VERSION ""

NS_ :

BS_:
BU_: IAP ODS _4WD BCM HUD DATC MDPS AAF_Tester AEMC SMK _4WD EPB CUBIS MTS TMU EVP CGW TPMS LPI DI_BOX SPAS EMS LCA TCU IBOX FATC AFLS FPCM SCC AHLS AVM ABS SNV OPI PGS SAS AAF Dummy LDWS_LKAS LVR ESC PSB CLU ECS ACU REA
BO_ 339 TCS11: 8 ESC
	SG_ TCS_REQ : 0|1@1+ (1.0,0.0) [0.0|1.0] ""  _4WD,EMS,EPB,TCU
	SG_ MSR_C_REQ : 1|1@1+ (1.0,0.0) [0.0|1.0] ""  EMS,EPB,SCC,TCU
	SG_ TCS_PAS : 2|1@1+ (1.0,0.0) [0.0|1.0] ""  _4WD,CLU,EMS,SCC,SPAS,TCU
	SG_ TCS_GSC : 3|1@1+ (1.0,0.0) [0.0|1.0] ""  _4WD,EMS,TCU
	SG_ CF_Esc_LimoInfo : 4|2@1+ (1.0,0.0) [0.0|3.0] ""  _4WD,SCC
	SG_ ABS_DIAG : 6|1@1+ (1.0,0.0) [0.0|1.0] ""  _4WD,CLU,EMS,EPB
	SG_ ABS_DEF : 7|1@1+ (1.0,0.0) [0.0|1.0] ""  _4WD,ACU,ECS,EMS,EPB,SCC,SPAS,TCU
	SG_ TCS_DEF : 8|1@1+ (1.0,0.0) [0.0|1.0] ""  _4WD,EMS,EPB,SCC,SPAS,TCU
	SG_ TCS_CTL : 9|1@1+ (1.0,0.0) [0.0|1.0] ""  _4WD,EMS,EPB,SCC,SPAS,TCU
	SG_ ABS_ACT : 10|1@1+ (1.0,0.0) [0.0|1.0] ""  _4WD,ACU,ECS,EMS,EPB,LDWS_LKAS,SCC,SPAS,TCU
	SG_ EBD_DEF : 11|1@1+ (1.0,0.0) [0.0|1.0] ""  _4WD,EMS,EPB,SPAS,TCU
	SG_ ESP_PAS : 12|1@1+ (1.0,0.0) [0.0|1.0] ""  _4WD,ACU,CLU,EMS,EPB,LDWS_LKAS,SCC,TCU
	SG_ ESP_DEF : 13|1@1+ (1.0,0.0) [0.0|1.0] ""  _4WD,ACU,ECS,EMS,EPB,LDWS_LKAS,SCC,TCU
	SG_ ESP_CTL : 14|1@1+ (1.0,0.0) [0.0|1.0] ""  _4WD,ACU,ECS,EMS,EPB,LDWS_LKAS,SCC,SPAS,TCU
	SG_ TCS_MFRN : 15|1@1+ (1.0,0.0) [0.0|1.0] ""  EMS,EPB,TCU
	SG_ DBC_CTL : 16|1@1+ (1.0,0.0) [0.0|1.0] ""  _4WD,EMS,EPB
	SG_ DBC_PAS : 17|1@1+ (1.0,0.0) [0.0|1.0] ""  _4WD,EMS,EPB
	SG_ DBC_DEF : 18|1@1+ (1.0,0.0) [0.0|1.0] ""  _4WD,EMS,EPB
	SG_ HAC_CTL : 19|1@1+ (1.0,0.0) [0.0|1.0] ""  _4WD,CLU,EMS,EPB,TCU
	SG_ HAC_PAS : 20|1@1+ (1.0,0.0) [0.0|1.0] ""  _4WD,CLU,EMS,EPB,TCU
	SG_ HAC_DEF : 21|1@1+ (1.0,0.0) [0.0|1.0] ""  _4WD,CLU,EMS,EPB,TCU
	SG_ ESS_STAT : 22|2@1+ (1.0,0.0) [0.0|3.0] ""  _4WD,BCM,CLU,EMS,EPB
	SG_ TQI_TCS : 24|8@1+ (0.390625,0.0) [0.0|99.609375] "%"  EMS,EPB,TCU
	SG_ TQI_MSR : 32|8@1+ (0.390625,0.0) [0.0|99.609375] "%"  EMS,EPB,TCU
	SG_ TQI_SLW_TCS : 40|8@1+ (0.390625,0.0) [0.0|99.609375] "%"  EMS,EPB,TCU
	SG_ CF_Esc_BrkCtl : 48|1@1+ (1.0,0.0) [0.0|1.0] ""  EMS
	SG_ BLA_CTL : 49|2@1+ (1.0,0.0) [0.0|3.0] ""  BCM,CGW,CLU
	SG_ AliveCounter_TCS1 : 52|4@1+ (1.0,0.0) [0.0|14.0] ""  EMS,EPB,LDWS_LKAS
	SG_ CheckSum_TCS1 : 56|8@1+ (1.0,0.0) [0.0|255.0] ""  EMS,EPB,LDWS_LKAS

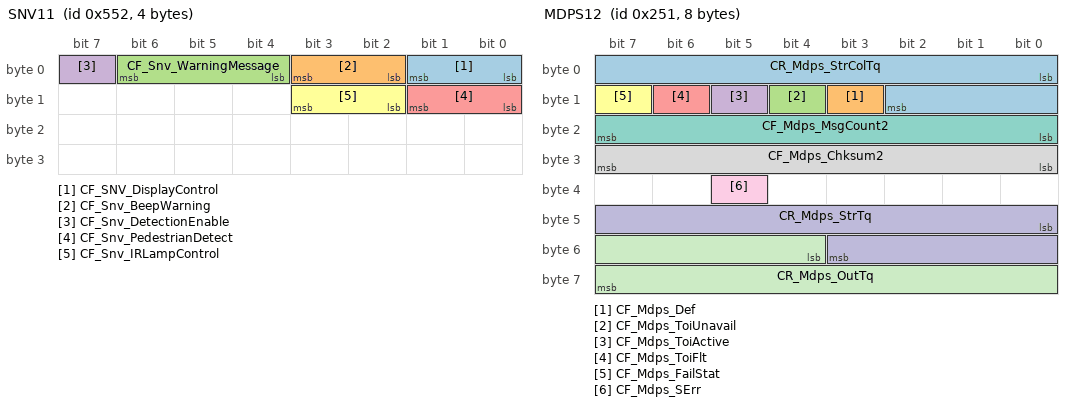
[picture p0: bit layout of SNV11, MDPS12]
BO_ 1362 SNV11: 4 SNV
	SG_ CF_SNV_DisplayControl : 0|2@1+ (1.0,0.0) [0.0|3.0] ""  CLU,HUD
	SG_ CF_Snv_BeepWarning : 2|2@1+ (1.0,0.0) [0.0|3.0] ""  CLU,HUD
	SG_ CF_Snv_WarningMessage : 4|3@1+ (1.0,0.0) [0.0|7.0] ""  CLU,HUD
	SG_ CF_Snv_DetectionEnable : 7|1@1+ (1.0,0.0) [0.0|1.0] ""  BCM,CLU,HUD
	SG_ CF_Snv_PedestrianDetect : 8|2@1+ (1.0,0.0) [0.0|3.0] ""  BCM,CLU,HUD
	SG_ CF_Snv_IRLampControl : 10|2@1+ (1.0,0.0) [0.0|3.0] ""  BCM,CLU,HUD

BO_ 593 MDPS12: 8 MDPS
	SG_ CR_Mdps_StrColTq : 0|11@1+ (0.0078125,-8.0) [-8.0|7.9921875] "Nm"  LDWS_LKAS
	SG_ CF_Mdps_Def : 11|1@1+ (1.0,0.0) [0.0|1.0] ""  ESC
	SG_ CF_Mdps_ToiUnavail : 12|1@1+ (1.0,0.0) [0.0|1.0] ""  LDWS_LKAS
	SG_ CF_Mdps_ToiActive : 13|1@1+ (1.0,0.0) [0.0|1.0] ""  LDWS_LKAS
	SG_ CF_Mdps_ToiFlt : 14|1@1+ (1.0,0.0) [0.0|1.0] ""  LDWS_LKAS
	SG_ CF_Mdps_FailStat : 15|1@1+ (1.0,0.0) [0.0|1.0] ""  LDWS_LKAS
	SG_ CF_Mdps_MsgCount2 : 16|8@1+ (1.0,0.0) [0.0|255.0] ""  ESC,LDWS_LKAS
	SG_ CF_Mdps_Chksum2 : 24|8@1+ (1.0,0.0) [0.0|255.0] ""  ESC,LDWS_LKAS
	SG_ CF_Mdps_SErr : 37|1@1+ (1.0,0.0) [0.0|1.0] ""  ESC
	SG_ CR_Mdps_StrTq : 40|12@1+ (0.01,-20.48) [-20.48|20.47] "Nm"  ESC
	SG_ CR_Mdps_OutTq : 52|12@1+ (0.1,-204.8) [-204.8|204.7] ""  ESC,LDWS_LKAS

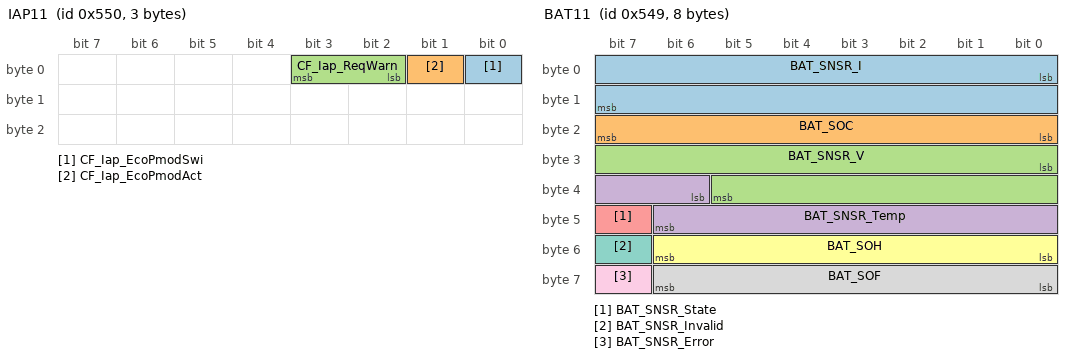
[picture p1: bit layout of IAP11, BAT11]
BO_ 1360 IAP11: 3 IAP
	SG_ CF_Iap_EcoPmodSwi : 0|1@1+ (1.0,0.0) [0.0|1.0] ""  CLU
	SG_ CF_Iap_EcoPmodAct : 1|1@1+ (1.0,0.0) [0.0|1.0] ""  CLU
	SG_ CF_Iap_ReqWarn : 2|2@1+ (1.0,0.0) [0.0|3.0] ""  CLU

BO_ 1356 TCU_DCT14: 8 TCU
	SG_ Vehicle_Stop_Time : 0|5@1+ (1.0,0.0) [0.0|0.0] ""  CLU
	SG_ HILL_HOLD_WARNING : 5|1@1+ (1.0,0.0) [0.0|0.0] ""  CLU

BO_ 1353 BAT11: 8 EMS
	SG_ BAT_SNSR_I : 0|16@1+ (0.01,-327.0) [-327.0|328.0] "A"  CGW,CUBIS,IBOX,TMU
	SG_ BAT_SOC : 16|8@1+ (1.0,0.0) [0.0|100.0] "%"  CGW,CUBIS,IBOX,TMU
	SG_ BAT_SNSR_V : 24|14@1+ (0.0010,6.0) [6.0|18.0] "V"  CGW,CUBIS,IBOX,TMU
	SG_ BAT_SNSR_Temp : 38|9@1- (0.5,-40.0) [-40.0|125.0] "¡É"  CGW,CUBIS,IBOX,TMU
	SG_ BAT_SNSR_State : 47|1@1+ (1.0,0.0) [0.0|1.0] ""  CGW,CUBIS,IBOX,TMU
	SG_ BAT_SOH : 48|7@1+ (1.0,0.0) [0.0|100.0] "%"  CGW,CUBIS,IBOX,TMU
	SG_ BAT_SNSR_Invalid : 55|1@1+ (1.0,0.0) [0.0|1.0] ""  CGW,CUBIS,IBOX,TMU
	SG_ BAT_SOF : 56|7@1+ (0.1,0.0) [0.0|12.0] "V"  CGW,CUBIS,IBOX,TMU
	SG_ BAT_SNSR_Error : 63|1@1+ (1.0,0.0) [0.0|1.0] ""  CGW,CUBIS,IBOX,TMU

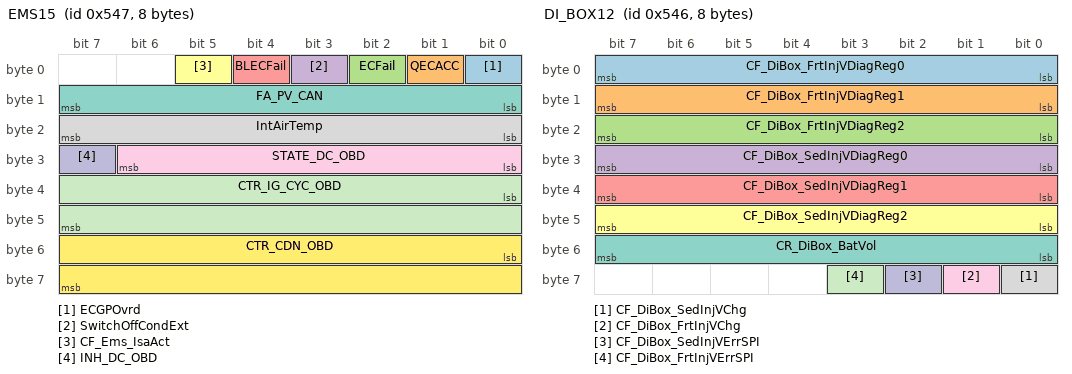
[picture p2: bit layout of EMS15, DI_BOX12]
BO_ 1351 EMS15: 8 EMS
	SG_ ECGPOvrd : 0|1@1+ (1.0,0.0) [0.0|1.0] ""  ESC,IBOX,SCC
	SG_ QECACC : 1|1@1+ (1.0,0.0) [0.0|1.0] ""  ESC,IBOX
	SG_ ECFail : 2|1@1+ (1.0,0.0) [0.0|1.0] ""  ESC,IBOX
	SG_ SwitchOffCondExt : 3|1@1+ (1.0,0.0) [0.0|1.0] ""  ESC,IBOX
	SG_ BLECFail : 4|1@1+ (1.0,0.0) [0.0|1.0] ""  ESC,IBOX
	SG_ CF_Ems_IsaAct : 5|1@1+ (1.0,0.0) [0.0|1.0] ""  CLU
	SG_ FA_PV_CAN : 8|8@1+ (0.3906,0.0) [0.0|99.2] "%"  IBOX,LDWS_LKAS,TCU
	SG_ IntAirTemp : 16|8@1+ (0.75,-48.0) [-48.0|143.25] "¡É"  _4WD,ECS,EPB,IBOX,TCU
	SG_ STATE_DC_OBD : 24|7@1+ (1.0,0.0) [0.0|127.0] ""  IBOX,TCU
	SG_ INH_DC_OBD : 31|1@1+ (1.0,0.0) [0.0|1.0] ""  IBOX,TCU
	SG_ CTR_IG_CYC_OBD : 32|16@1+ (1.0,0.0) [0.0|65535.0] ""  ACU,IBOX,TCU
	SG_ CTR_CDN_OBD : 48|16@1+ (1.0,0.0) [0.0|65535.0] ""  IBOX,TCU

BO_ 1350 DI_BOX12: 8 DI_BOX
	SG_ CF_DiBox_FrtInjVDiagReg0 : 0|8@1+ (1.0,0.0) [0.0|255.0] ""  EMS
	SG_ CF_DiBox_FrtInjVDiagReg1 : 8|8@1+ (1.0,0.0) [0.0|255.0] ""  EMS
	SG_ CF_DiBox_FrtInjVDiagReg2 : 16|8@1+ (1.0,0.0) [0.0|255.0] ""  EMS
	SG_ CF_DiBox_SedInjVDiagReg0 : 24|8@1+ (1.0,0.0) [0.0|255.0] ""  EMS
	SG_ CF_DiBox_SedInjVDiagReg1 : 32|8@1+ (1.0,0.0) [0.0|255.0] ""  EMS
	SG_ CF_DiBox_SedInjVDiagReg2 : 40|8@1+ (1.0,0.0) [0.0|255.0] ""  EMS
	SG_ CR_DiBox_BatVol : 48|8@1+ (0.1,0.0) [0.0|25.5] "V"  EMS
	SG_ CF_DiBox_SedInjVChg : 56|1@1+ (1.0,0.0) [0.0|1.0] ""  EMS
	SG_ CF_DiBox_FrtInjVChg : 57|1@1+ (1.0,0.0) [0.0|1.0] ""  EMS
	SG_ CF_DiBox_SedInjVErrSPI : 58|1@1+ (1.0,0.0) [0.0|1.0] ""  EMS
	SG_ CF_DiBox_FrtInjVErrSPI : 59|1@1+ (1.0,0.0) [0.0|1.0] ""  EMS

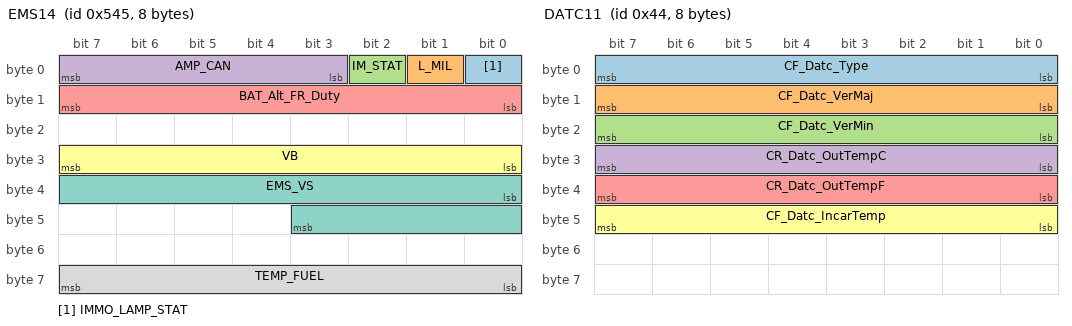
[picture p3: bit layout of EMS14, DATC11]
BO_ 1349 EMS14: 8 EMS
	SG_ IMMO_LAMP_STAT : 0|1@1+ (1.0,0.0) [0.0|1.0] ""  CLU,IBOX
	SG_ L_MIL : 1|1@1+ (1.0,0.0) [0.0|1.0] ""  CLU,CUBIS,IBOX
	SG_ IM_STAT : 2|1@1+ (1.0,0.0) [0.0|1.0] ""  CLU,IBOX
	SG_ AMP_CAN : 3|5@1+ (10.731613,458.98) [458.98|791.660003] "mmHg"  CLU,IBOX,TCU,TPMS
	SG_ BAT_Alt_FR_Duty : 8|8@1+ (0.4,0.0) [0.0|100.0] "%"  CGW,CUBIS,IBOX,TMU
	SG_ VB : 24|8@1+ (0.1015625,0.0) [0.0|25.8984375] "V"  CLU,CUBIS,DATC,EPB,FPCM,IBOX
	SG_ EMS_VS : 32|12@1+ (0.0625,0.0) [0.0|255.875] "km/h"  CLU
	SG_ TEMP_FUEL : 56|8@1+ (0.75,-48.0) [-48.0|143.25] "¡É"  FPCM

BO_ 68 DATC11: 8 DATC
	SG_ CF_Datc_Type : 0|8@1+ (1.0,0.0) [0.0|255.0] ""  CLU
	SG_ CF_Datc_VerMaj : 8|8@1+ (1.0,0.0) [0.0|255.0] ""  CLU
	SG_ CF_Datc_VerMin : 16|8@1+ (1.0,0.0) [0.0|255.0] ""  CLU
	SG_ CR_Datc_OutTempC : 24|8@1+ (0.5,-41.0) [-41.0|86.5] "¡É"  CLU,FPCM
	SG_ CR_Datc_OutTempF : 32|8@1+ (1.0,-42.0) [-42.0|213.0] "¡É"  CLU
	SG_ CF_Datc_IncarTemp : 40|8@1+ (0.5,-40.0) [-40.0|60.0] "¡É"  BCM,CLU

BO_ 67 DATC13: 8 DATC
	SG_ CF_Datc_TempDispUnit : 0|2@1+ (1.0,0.0) [0.0|3.0] ""  CLU,IBOX
	SG_ CF_Datc_ModDisp : 2|4@1+ (1.0,0.0) [0.0|15.0] ""  CLU
	SG_ CF_Datc_IonClean : 6|2@1+ (1.0,0.0) [0.0|3.0] ""  CLU
	SG_ CF_Datc_ChgReqDisp : 8|2@1+ (1.0,0.0) [0.0|3.0] ""  CLU
	SG_ CF_Datc_IntakeDisp : 10|2@1+ (1.0,0.0) [0.0|3.0] ""  CLU
	SG_ CF_Datc_AutoDisp : 12|2@1+ (1.0,0.0) [0.0|3.0] ""  CLU
	SG_ CF_Datc_FrDefLed : 14|2@1+ (1.0,0.0) [0.0|3.0] ""  CLU,IBOX
	SG_ CF_Datc_AutoDefogBlink : 16|2@1+ (1.0,0.0) [0.0|3.0] ""  CLU
	SG_ CF_Datc_ClmScanDisp : 18|2@1+ (1.0,0.0) [0.0|3.0] ""  CLU
	SG_ CF_Datc_AqsDisp : 20|2@1+ (1.0,0.0) [0.0|3.0] ""  CLU
	SG_ CF_Datc_AcDisp : 22|2@1+ (1.0,0.0) [0.0|3.0] ""  CLU
	SG_ CF_Datc_OpSts : 25|3@1+ (1.0,0.0) [0.0|7.0] ""  CLU
	SG_ CF_Mtc_MaxAcDisp : 28|2@1+ (1.0,0.0) [0.0|3.0] ""  CLU
	SG_ CF_Datc_DualDisp : 30|2@1+ (1.0,0.0) [0.0|3.0] ""  CLU
	SG_ CF_Datc_PwrInf : 32|4@1+ (1.0,0.0) [0.0|15.0] ""  CLU
	SG_ CF_Datc_RearManual : 38|2@1+ (1.0,0.0) [0.0|3.0] ""  CLU
	SG_ CF_Datc_RearAutoDisp : 40|2@1+ (1.0,0.0) [0.0|1.0] ""  CLU
	SG_ CF_Datc_RearOffDisp : 42|2@1+ (1.0,0.0) [0.0|3.0] ""  CLU
	SG_ CF_Datc_RearClimateScnDisp : 44|2@1+ (1.0,0.0) [0.0|3.0] ""  CLU
	SG_ CF_Datc_RearChgReqDisp : 46|2@1+ (1.0,0.0) [0.0|3.0] ""  CLU
	SG_ CF_Datc_RearModDisp : 48|4@1+ (1.0,0.0) [0.0|15.0] ""  CLU
	SG_ CF_Datc_RearBlwDisp : 52|4@1+ (1.0,0.0) [0.0|15.0] ""  CLU
	SG_ CF_Datc_PSModDisp : 56|4@1+ (1.0,0.0) [0.0|15.0] ""  CLU
	SG_ CF_Datc_FrontBlwDisp : 60|4@1+ (1.0,0.0) [0.0|15.0] ""  CLU,IBOX

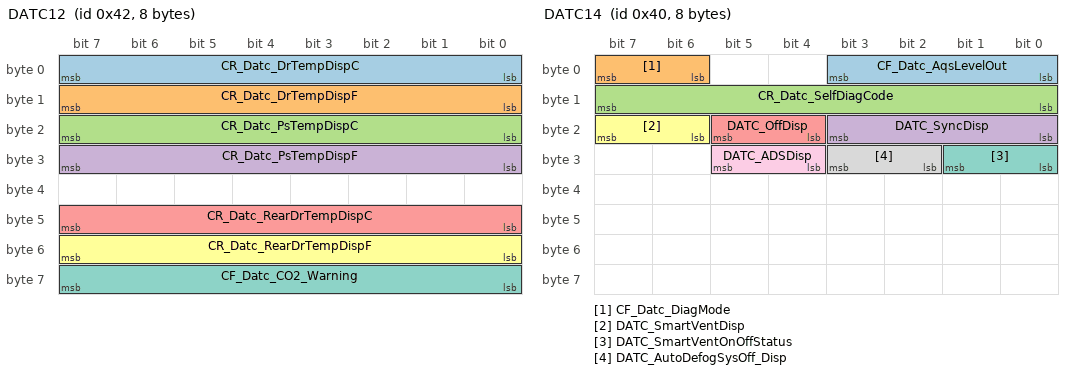
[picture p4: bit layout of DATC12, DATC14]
BO_ 66 DATC12: 8 DATC
	SG_ CR_Datc_DrTempDispC : 0|8@1+ (0.5,14.0) [15.0|32.0] "¡É"  CLU,IBOX
	SG_ CR_Datc_DrTempDispF : 8|8@1+ (1.0,56.0) [58.0|90.0] "¢µ"  CLU,IBOX
	SG_ CR_Datc_PsTempDispC : 16|8@1+ (0.5,14.0) [15.0|32.0] "¡É"  CLU,IBOX
	SG_ CR_Datc_PsTempDispF : 24|8@1+ (1.0,56.0) [58.0|90.0] "¢µ"  CLU,IBOX
	SG_ CR_Datc_RearDrTempDispC : 40|8@1+ (0.5,14.0) [15.0|32.0] "¡É"  CLU
	SG_ CR_Datc_RearDrTempDispF : 48|8@1+ (1.0,58.0) [58.0|90.0] "¢µ"  CLU
	SG_ CF_Datc_CO2_Warning : 56|8@1+ (1.0,0.0) [0.0|3.0] ""  CLU

BO_ 1345 CGW1: 8 BCM
	SG_ CF_Gway_IGNSw : 0|3@1+ (1.0,0.0) [0.0|7.0] ""  AVM,CLU,ECS,EMS,EPB,ESC,IBOX,LVR,MDPS,SAS,SCC,ECS,EMS,EPB,ESC,IBOX,LVR,MDPS,SAS,SCC
	SG_ CF_Gway_RKECmd : 3|3@1+ (1.0,0.0) [0.0|7.0] ""  CLU,ECS,EMS,IBOX,ECS,EMS,IBOX
	SG_ CF_Gway_DrvKeyLockSw : 6|1@1+ (1.0,0.0) [0.0|1.0] ""  ECS,EMS,IBOX,ECS,EMS,IBOX
	SG_ CF_Gway_DrvKeyUnlockSw : 7|1@1+ (1.0,0.0) [0.0|1.0] ""  ECS,EMS,IBOX,ECS,EMS,IBOX
	SG_ CF_Gway_DrvDrSw : 8|2@1+ (1.0,0.0) [0.0|3.0] ""  CLU,ECS,EMS,EPB,ESC,IBOX,SCC,TCU,ECS,EMS,EPB,ESC,IBOX,SCC,TCU
	SG_ CF_Gway_DrvSeatBeltSw : 10|2@1+ (1.0,0.0) [0.0|3.0] ""  EMS,EPB,ESC,IBOX,PSB,TCU,EMS,EPB,ESC,IBOX,PSB,TCU
	SG_ CF_Gway_TrunkTgSw : 12|2@1+ (1.0,0.0) [0.0|3.0] ""  CLU,ECS,EMS,EPB,ESC,IBOX,ECS,EMS,EPB,ESC,IBOX
	SG_ CF_Gway_AstSeatBeltSw : 14|2@1+ (1.0,0.0) [0.0|3.0] ""  IBOX,PSB,IBOX,PSB
	SG_ CF_Gway_SMKOption : 16|1@1+ (1.0,0.0) [0.0|1.0] ""  CLU,EMS,IBOX,EMS,IBOX,SMK
	SG_ CF_Gway_HoodSw : 17|2@1+ (1.0,0.0) [0.0|3.0] ""  CLU,EMS,EPB,ESC,IBOX,EMS,EPB,ESC,IBOX
	SG_ CF_Gway_TurnSigLh : 19|2@1+ (1.0,0.0) [0.0|3.0] ""  CLU,EMS,IBOX,LCA,LDWS_LKAS,SCC,EMS,IBOX,LCA,LDWS_LKAS,SCC
	SG_ CF_Gway_WiperIntT : 21|3@1+ (1.0,0.0) [0.0|7.0] ""  CLU,EMS,IBOX,LDWS_LKAS,EMS,ESC,IBOX,LDWS_LKAS
	SG_ CF_Gway_WiperIntSw : 24|1@1+ (1.0,0.0) [0.0|1.0] ""  CLU,EMS,IBOX,LDWS_LKAS,EMS,ESC,IBOX,LDWS_LKAS
	SG_ CF_Gway_WiperLowSw : 25|1@1+ (1.0,0.0) [0.0|1.0] ""  CLU,EMS,IBOX,LDWS_LKAS,EMS,ESC,IBOX,LDWS_LKAS
	SG_ CF_Gway_WiperHighSw : 26|1@1+ (1.0,0.0) [0.0|1.0] ""  CLU,EMS,IBOX,LDWS_LKAS,EMS,ESC,IBOX,LDWS_LKAS
	SG_ CF_Gway_WiperAutoSw : 27|1@1+ (1.0,0.0) [0.0|1.0] ""  CLU,EMS,IBOX,LDWS_LKAS,EMS,ESC,IBOX,LDWS_LKAS
	SG_ CF_Gway_RainSnsState : 28|3@1+ (1.0,0.0) [0.0|7.0] ""  AFLS,EMS,IBOX,LDWS_LKAS,AFLS,EMS,ESC,IBOX,LDWS_LKAS
	SG_ CF_Gway_HeadLampLow : 31|1@1+ (1.0,0.0) [0.0|1.0] ""  AFLS,CLU,EMS,IBOX,LDWS_LKAS,SNV,AFLS,EMS,IBOX,LDWS_LKAS,SNV
	SG_ CF_Gway_HeadLampHigh : 32|1@1+ (1.0,0.0) [0.0|1.0] ""  AFLS,CLU,EMS,IBOX,LDWS_LKAS,AFLS,EMS,IBOX,LDWS_LKAS
	SG_ CF_Gway_HazardSw : 33|2@1+ (1.0,0.0) [0.0|3.0] ""  ABS,EMS,ESC,IBOX,LCA,LDWS_LKAS,ABS,EMS,ESC,IBOX,LCA,LDWS_LKAS
	SG_ CF_Gway_AstDrSw : 35|1@1+ (1.0,0.0) [0.0|1.0] ""  CLU,IBOX,IBOX
	SG_ CF_Gway_DefoggerRly : 36|1@1+ (1.0,0.0) [0.0|1.0] ""  EMS,IBOX,EMS,IBOX
	SG_ CF_Gway_ALightStat : 37|1@1+ (1.0,0.0) [0.0|1.0] ""  AFLS,IBOX,LDWS_LKAS,AFLS,IBOX,LDWS_LKAS
	SG_ CF_Gway_LightSwState : 38|2@1+ (1.0,0.0) [0.0|3.0] ""  AFLS,IBOX,LDWS_LKAS,AFLS,IBOX,LDWS_LKAS
	SG_ CF_Gway_Frt_Fog_Act : 40|1@1+ (1.0,0.0) [0.0|1.0] ""  AFLS,CLU,IBOX,LDWS_LKAS,AFLS,IBOX,LDWS_LKAS
	SG_ CF_Gway_TSigRHSw : 41|1@1+ (1.0,0.0) [0.0|1.0] ""  IBOX,LDWS_LKAS,IBOX,LDWS_LKAS
	SG_ CF_Gway_TSigLHSw : 42|1@1+ (1.0,0.0) [0.0|1.0] ""  IBOX,LDWS_LKAS,IBOX,LDWS_LKAS
	SG_ CF_Gway_DriveTypeOption : 43|1@1+ (1.0,0.0) [0.0|1.0] ""  CLU,IBOX,LDWS_LKAS,IBOX,LDWS_LKAS
	SG_ CF_Gway_StarterRlyState : 44|1@1+ (1.0,0.0) [0.0|1.0] ""  EMS,IBOX,EMS,IBOX,SMK
	SG_ CF_Gway_PassiveAccessLock : 45|2@1+ (1.0,0.0) [0.0|7.0] ""  CLU,ECS,EMS,IBOX,ECS,EMS,IBOX,SMK
	SG_ CF_Gway_WiperMistSw : 47|1@1+ (1.0,0.0) [0.0|1.0] ""  CLU,EMS,IBOX,LDWS_LKAS
	SG_ CF_Gway_PassiveAccessUnlock : 48|2@1+ (1.0,0.0) [0.0|7.0] ""  CLU,ECS,EMS,IBOX,ECS,EMS,IBOX,SMK
	SG_ CF_Gway_RrSunRoofOpenState : 50|1@1+ (1.0,0.0) [0.0|1.0] ""  CLU,DATC,IBOX
	SG_ CF_Gway_PassingSW : 51|1@1+ (1.0,0.0) [0.0|1.0] ""  AFLS,IBOX,LDWS_LKAS,AFLS,IBOX,LDWS_LKAS
	SG_ CF_Gway_HBAControlMode : 52|1@1+ (1.0,0.0) [0.0|1.0] ""  IBOX,LDWS_LKAS,IBOX,LDWS_LKAS
	SG_ CF_Gway_HLpHighSw : 53|1@1+ (1.0,0.0) [0.0|1.0] ""  IBOX,LDWS_LKAS,IBOX,LDWS_LKAS
	SG_ CF_Gway_InhibitRMT : 54|2@1+ (1.0,0.0) [0.0|3.0] ""  EMS,EPB,ESC,IBOX,LCA,LDWS_LKAS,MDPS,PGS,SCC,SPAS,TPMS,EPB,ESC,IBOX,LCA,LDWS_LKAS,PGS,SCC,SPAS,TPMS
	SG_ CF_Gway_RainSnsOption : 56|1@1+ (1.0,0.0) [0.0|1.0] ""  CLU
	SG_ C_SunRoofOpenState : 57|1@1+ (1.0,0.0) [0.0|1.0] ""  CLU,DATC,IBOX,DATC,IBOX
	SG_ CF_Gway_Ign1 : 58|1@1+ (1.0,0.0) [0.0|1.0] ""  CLU
	SG_ CF_Gway_Ign2 : 59|1@1+ (1.0,0.0) [0.0|1.0] ""  CLU
	SG_ CF_Gway_ParkBrakeSw : 60|2@1+ (1.0,0.0) [0.0|3.0] ""  CLU,ESC,IBOX,SCC,ESC,IBOX,SCC
	SG_ CF_Gway_TurnSigRh : 62|2@1+ (1.0,0.0) [0.0|3.0] ""  CLU,EMS,IBOX,LCA,LDWS_LKAS,SCC,EMS,IBOX,LCA,LDWS_LKAS,SCC

BO_ 64 DATC14: 8 DATC
	SG_ CF_Datc_AqsLevelOut : 0|4@1+ (1.0,0.0) [0.0|3.0] ""  CLU
	SG_ CF_Datc_DiagMode : 6|2@1+ (1.0,0.0) [0.0|3.0] ""  CLU
	SG_ CR_Datc_SelfDiagCode : 8|8@1+ (1.0,-1.0) [0.0|254.0] ""  CLU
	SG_ DATC_SyncDisp : 16|4@1+ (1.0,0.0) [0.0|3.0] ""  CLU
	SG_ DATC_OffDisp : 20|2@1+ (1.0,0.0) [0.0|3.0] ""  CLU
	SG_ DATC_SmartVentDisp : 22|2@1+ (1.0,0.0) [0.0|3.0] ""  CLU
	SG_ DATC_SmartVentOnOffStatus : 24|2@1+ (1.0,0.0) [0.0|3.0] ""  CLU
	SG_ DATC_AutoDefogSysOff_Disp : 26|2@1+ (1.0,0.0) [0.0|3.0] ""  CLU
	SG_ DATC_ADSDisp : 28|2@1+ (1.0,0.0) [0.0|3.0] ""  CLU

BO_ 832 LKAS11: 8 LDWS_LKAS
	SG_ CF_Lkas_LdwsSysState : 2|4@1+ (1.0,0.0) [0.0|15.0] ""  CLU,IBOX,PSB
	SG_ CF_Lkas_SysWarning : 6|4@1+ (1.0,0.0) [0.0|15.0] ""  BCM,CLU
	SG_ CF_Lkas_LdwsLHWarning : 10|2@1+ (1.0,0.0) [0.0|3.0] ""  BCM,CLU,PSB
	SG_ CF_Lkas_LdwsRHWarning : 12|2@1+ (1.0,0.0) [0.0|3.0] ""  BCM,CLU,PSB
	SG_ CF_Lkas_HbaLamp : 14|1@1+ (1.0,0.0) [0.0|1.0] ""  CLU
	SG_ CF_Lkas_FcwBasReq : 15|1@1+ (1.0,0.0) [0.0|1.0] ""  ABS,ESC
	SG_ CR_Lkas_StrToqReq : 16|11@1+ (0.0078125,-8.0) [-8.0|8.0] "Nm"  MDPS
	SG_ CF_Lkas_ActToi : 27|1@1+ (1.0,0.0) [0.0|1.0] ""  MDPS
	SG_ CF_Lkas_ToiFlt : 28|1@1+ (1.0,0.0) [0.0|1.0] ""  MDPS
	SG_ CF_Lkas_HbaSysState : 29|3@1+ (1.0,0.0) [0.0|7.0] ""  BCM,CLU
	SG_ CF_Lkas_FcwOpt : 32|2@1+ (1.0,0.0) [0.0|3.0] ""  CLU
	SG_ CF_Lkas_HbaOpt : 34|1@1+ (1.0,0.0) [0.0|1.0] ""  BCM,CGW
	SG_ CF_Lkas_MsgCount : 36|4@1+ (1.0,0.0) [0.0|15.0] ""  CLU,MDPS
	SG_ CF_Lkas_FcwSysState : 40|3@1+ (1.0,0.0) [0.0|7.0] ""  CLU
	SG_ CF_Lkas_FcwCollisionWarning : 43|2@1+ (1.0,0.0) [0.0|3.0] ""  CLU
	SG_ CF_Lkas_FusionState : 45|2@1+ (1.0,0.0) [0.0|3.0] ""  SCC
	SG_ CF_Lkas_Chksum : 48|8@1+ (1.0,0.0) [0.0|255.0] ""  MDPS
	SG_ CF_Lkas_FcwOpt_USM : 56|3@1+ (1.0,0.0) [0.0|7.0] ""  CLU
	SG_ CF_Lkas_LdwsOpt_USM : 59|3@1+ (1.0,0.0) [0.0|7.0] ""  CLU,MDPS

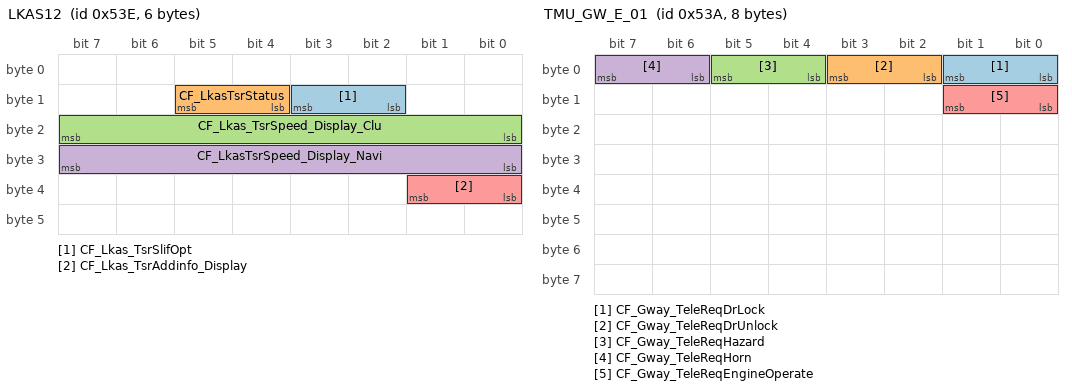
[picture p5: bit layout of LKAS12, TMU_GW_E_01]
BO_ 1342 LKAS12: 6 LDWS_LKAS
	SG_ CF_Lkas_TsrSlifOpt : 10|2@1+ (1.0,0.0) [0.0|3.0] ""  CLU
	SG_ CF_LkasTsrStatus : 12|2@1+ (1.0,0.0) [0.0|3.0] ""  CLU
	SG_ CF_Lkas_TsrSpeed_Display_Clu : 16|8@1+ (1.0,0.0) [0.0|255.0] ""  CLU
	SG_ CF_LkasTsrSpeed_Display_Navi : 24|8@1+ (1.0,0.0) [0.0|255.0] ""  BCM,CLU
	SG_ CF_Lkas_TsrAddinfo_Display : 32|2@1+ (1.0,0.0) [0.0|3.0] ""  CLU

BO_ 1338 TMU_GW_E_01: 8 CLU
	SG_ CF_Gway_TeleReqDrLock : 0|2@1+ (1.0,0.0) [0.0|3.0] ""  BCM
	SG_ CF_Gway_TeleReqDrUnlock : 2|2@1+ (1.0,0.0) [0.0|3.0] ""  BCM
	SG_ CF_Gway_TeleReqHazard : 4|2@1+ (1.0,0.0) [0.0|3.0] ""  BCM
	SG_ CF_Gway_TeleReqHorn : 6|2@1+ (1.0,0.0) [0.0|3.0] ""  BCM
	SG_ CF_Gway_TeleReqEngineOperate : 8|2@1+ (1.0,0.0) [0.0|3.0] ""  BCM

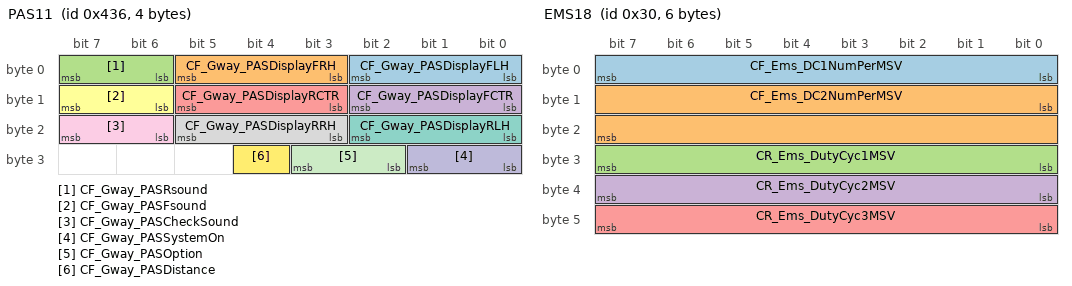
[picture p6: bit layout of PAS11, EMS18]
BO_ 1078 PAS11: 4 BCM
	SG_ CF_Gway_PASDisplayFLH : 0|3@1+ (1.0,0.0) [0.0|7.0] ""  AVM,CLU,AVM
	SG_ CF_Gway_PASDisplayFRH : 3|3@1+ (1.0,0.0) [0.0|7.0] ""  AVM,CLU,AVM
	SG_ CF_Gway_PASRsound : 6|2@1+ (1.0,0.0) [0.0|3.0] ""  CLU,Dummy
	SG_ CF_Gway_PASDisplayFCTR : 8|3@1+ (1.0,0.0) [0.0|7.0] ""  AVM,CLU,AVM
	SG_ CF_Gway_PASDisplayRCTR : 11|3@1+ (1.0,0.0) [0.0|7.0] ""  AVM,CLU,PGS,AVM
	SG_ CF_Gway_PASFsound : 14|2@1+ (1.0,0.0) [0.0|3.0] ""  CLU,Dummy
	SG_ CF_Gway_PASDisplayRLH : 16|3@1+ (1.0,0.0) [0.0|7.0] ""  AVM,CLU,PGS,AVM
	SG_ CF_Gway_PASDisplayRRH : 19|3@1+ (1.0,0.0) [0.0|7.0] ""  AVM,CLU,PGS,AVM
	SG_ CF_Gway_PASCheckSound : 22|2@1+ (1.0,0.0) [0.0|3.0] ""  CLU,Dummy
	SG_ CF_Gway_PASSystemOn : 24|2@1+ (1.0,0.0) [0.0|3.0] ""  CLU,Dummy
	SG_ CF_Gway_PASOption : 26|2@1+ (1.0,0.0) [0.0|3.0] ""  CLU
	SG_ CF_Gway_PASDistance : 28|1@1+ (1.0,0.0) [0.0|1.0] ""  CLU

BO_ 48 EMS18: 6 EMS
	SG_ CF_Ems_DC1NumPerMSV : 0|8@1+ (1.0,0.0) [0.0|255.0] ""  DI_BOX
	SG_ CF_Ems_DC2NumPerMSV : 8|16@1+ (1.0,0.0) [0.0|65535.0] ""  DI_BOX
	SG_ CR_Ems_DutyCyc1MSV : 24|8@1+ (0.1953,0.0) [0.0|49.8] "%"  DI_BOX
	SG_ CR_Ems_DutyCyc2MSV : 32|8@1+ (0.13725,0.0) [0.0|35.0] "%"  DI_BOX
	SG_ CR_Ems_DutyCyc3MSV : 40|8@1+ (0.392,0.0) [0.0|100.0] "%"  DI_BOX

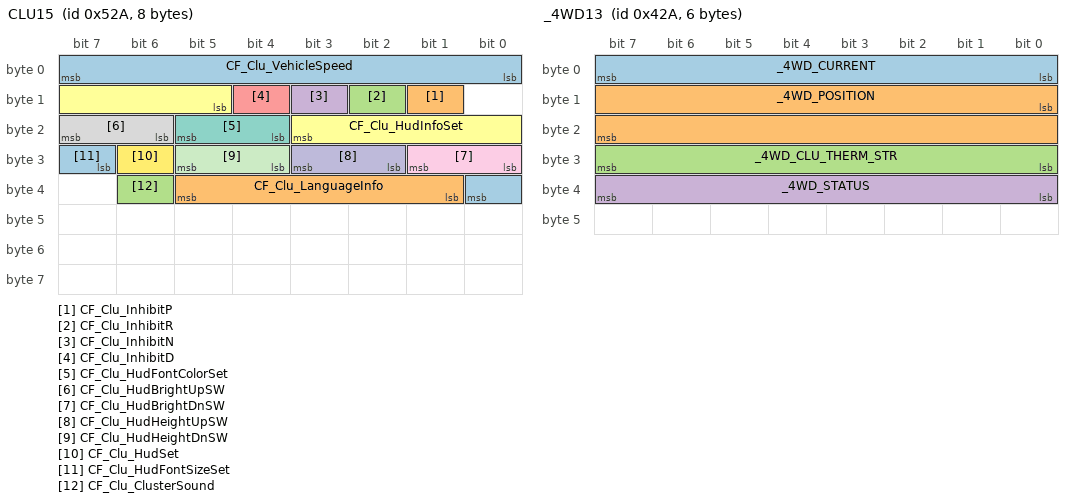
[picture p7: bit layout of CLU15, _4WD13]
BO_ 1322 CLU15: 8 CLU
	SG_ CF_Clu_VehicleSpeed : 0|8@1+ (1.0,0.0) [0.0|255.0] ""  BCM
	SG_ CF_Clu_InhibitP : 9|1@1+ (1.0,0.0) [0.0|1.0] ""  BCM
	SG_ CF_Clu_InhibitR : 10|1@1+ (1.0,0.0) [0.0|1.0] ""  BCM
	SG_ CF_Clu_InhibitN : 11|1@1+ (1.0,0.0) [0.0|1.0] ""  BCM
	SG_ CF_Clu_InhibitD : 12|1@1+ (1.0,0.0) [0.0|1.0] ""  BCM
	SG_ CF_Clu_HudInfoSet : 13|7@1+ (1.0,0.0) [0.0|127.0] ""  HUD
	SG_ CF_Clu_HudFontColorSet : 20|2@1+ (1.0,0.0) [0.0|3.0] ""  HUD
	SG_ CF_Clu_HudBrightUpSW : 22|2@1+ (1.0,0.0) [0.0|3.0] ""  HUD
	SG_ CF_Clu_HudBrightDnSW : 24|2@1+ (1.0,0.0) [0.0|3.0] ""  HUD
	SG_ CF_Clu_HudHeightUpSW : 26|2@1+ (1.0,0.0) [0.0|3.0] ""  HUD
	SG_ CF_Clu_HudHeightDnSW : 28|2@1+ (1.0,0.0) [0.0|3.0] ""  HUD
	SG_ CF_Clu_HudSet : 30|1@1+ (1.0,0.0) [0.0|1.0] ""  HUD
	SG_ CF_Clu_HudFontSizeSet : 31|2@1+ (1.0,0.0) [0.0|3.0] ""  HUD
	SG_ CF_Clu_LanguageInfo : 33|5@1+ (1.0,0.0) [0.0|31.0] ""  BCM,PGS
	SG_ CF_Clu_ClusterSound : 38|1@1- (1.0,0.0) [0.0|0.0] ""  BCM,CGW,FATC

BO_ 1066 _4WD13: 6 _4WD
	SG_ _4WD_CURRENT : 0|8@1+ (0.390625,0.0) [-50.0|50.0] "A"  TCU
	SG_ _4WD_POSITION : 8|16@1+ (0.015625,0.0) [-180.0|180.0] "Deg"  TCU
	SG_ _4WD_CLU_THERM_STR : 24|8@1+ (1.0,0.0) [0.0|100.0] "%"  TCU
	SG_ _4WD_STATUS : 32|8@1+ (1.0,0.0) [0.0|15.0] ""  ESC,TCU

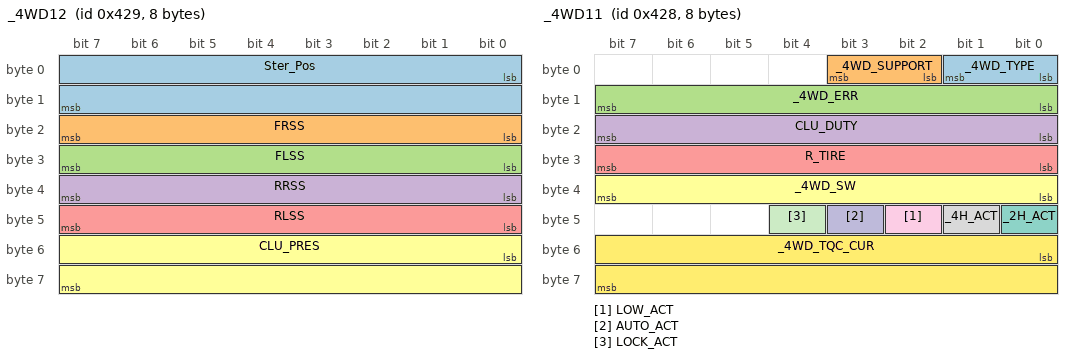
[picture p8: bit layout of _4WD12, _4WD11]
BO_ 1065 _4WD12: 8 _4WD
	SG_ Ster_Pos : 0|16@1+ (1.0,-600.0) [-600.0|600.0] "Deg"  ESC
	SG_ FRSS : 16|8@1+ (1.0,0.0) [0.0|254.0] "km/h"  ESC
	SG_ FLSS : 24|8@1+ (1.0,0.0) [0.0|254.0] "km/h"  ESC
	SG_ RRSS : 32|8@1+ (1.0,0.0) [0.0|254.0] "km/h"  ESC
	SG_ RLSS : 40|8@1+ (1.0,0.0) [0.0|254.0] "km/h"  ESC
	SG_ CLU_PRES : 48|16@1+ (0.0625,-50.0) [-50.0|50.0] "Bar"  ESC

BO_ 809 EMS12: 8 EMS
	SG_ CONF_TCU m1 : 0|6@1+ (1.0,0.0) [0.0|63.0] ""  _4WD,ACU,BCM,CLU,DATC,EPB,ESC,IBOX,LCA,SMK
	SG_ CAN_VERS m0 : 0|6@1+ (1.0,0.0) [0.0|7.7] ""  _4WD,ABS,ESC,IBOX
	SG_ TQ_STND m3 : 0|6@1+ (10.0,0.0) [0.0|630.0] "Nm"  _4WD,DATC,ECS,EPB,ESC,FATC,IBOX
	SG_ OBD_FRF_ACK m2 : 0|6@1+ (1.0,0.0) [0.0|63.0] ""  _4WD,ESC,IBOX
	SG_ MUL_CODE M : 6|2@1+ (1.0,0.0) [0.0|3.0] ""  _4WD,ABS,ACU,BCM,CLU,DATC,ECS,EPB,ESC,IBOX,LCA,SMK,TCU
	SG_ TEMP_ENG : 8|8@1+ (0.75,-48.0) [-48.0|143.25] "¡É"  _4WD,BCM,CLU,DATC,EPB,ESC,IBOX,SMK,TCU
	SG_ MAF_FAC_ALTI_MMV : 16|8@1+ (0.00781,0.0) [0.0|1.99155] ""  IBOX,TCU
	SG_ VB_OFF_ACT : 24|1@1+ (1.0,0.0) [0.0|1.0] ""  IBOX,TCU
	SG_ ACK_ES : 25|1@1+ (1.0,0.0) [0.0|1.0] ""  _4WD,ACU,IBOX
	SG_ CONF_MIL_FMY : 26|3@1+ (1.0,0.0) [0.0|7.0] ""  ESC,IBOX,TCU
	SG_ OD_OFF_REQ : 29|1@1+ (1.0,0.0) [0.0|1.0] ""  IBOX,TCU
	SG_ ACC_ACT : 30|1@1+ (1.0,0.0) [0.0|1.0] ""  _4WD,ABS,CLU,ESC,IAP,IBOX,SCC,TCU
	SG_ CLU_ACK : 31|1@1+ (1.0,0.0) [0.0|1.0] ""  _4WD,EPB,ESC,IBOX
	SG_ BRAKE_ACT : 32|2@1+ (1.0,0.0) [0.0|3.0] ""  _4WD,ABS,ACU,AFLS,CLU,DATC,ECS,EPB,ESC,IBOX,LDWS_LKAS,TCU
	SG_ ENG_CHR : 34|4@1+ (1.0,0.0) [0.0|15.0] ""  _4WD,ABS,ACU,CLU,DATC,EPB,ESC,FATC,IBOX,SCC,SMK,TCU
	SG_ GP_CTL : 38|2@1+ (1.0,0.0) [0.0|3.0] ""  IBOX
	SG_ TPS : 40|8@1+ (0.4694836,-15.0234742) [-15.0234742|104.6948357] "%"  _4WD,ABS,ACU,CLU,DATC,ECS,EPB,ESC,IBOX,TCU
	SG_ PV_AV_CAN : 48|8@1+ (0.3906,0.0) [0.0|99.603] "%"  _4WD,AAF,ABS,ACU,AFLS,CLU,DATC,EPB,ESC,IAP,IBOX,LDWS_LKAS,SCC,TCU
	SG_ ENG_VOL : 56|8@1+ (0.1,0.0) [0.0|25.5] "liter"  _4WD,ABS,ACU,BCM,CLU,DATC,EPB,ESC,IBOX,LDWS_LKAS,SCC,SMK

BO_ 1064 _4WD11: 8 _4WD
	SG_ _4WD_TYPE : 0|2@1+ (1.0,0.0) [0.0|3.0] ""  ACU,ESC,TPMS
	SG_ _4WD_SUPPORT : 2|2@1+ (1.0,0.0) [0.0|3.0] ""  ABS,ESC,TPMS
	SG_ _4WD_ERR : 8|8@1+ (1.0,0.0) [0.0|255.0] ""  CLU,ESC
	SG_ CLU_DUTY : 16|8@1+ (1.0,0.0) [0.0|64.0] "%"  ABS,ESC
	SG_ R_TIRE : 24|8@1+ (1.0,200.0) [200.0|455.0] "mm"  ABS,ESC,TPMS
	SG_ _4WD_SW : 32|8@1+ (1.0,0.0) [0.0|9.9] ""  ESC
	SG_ _2H_ACT : 40|1@1+ (1.0,0.0) [0.0|1.0] ""  ABS,ESC
	SG_ _4H_ACT : 41|1@1+ (1.0,0.0) [0.0|1.0] ""  ABS,CLU,ESC,TPMS
	SG_ LOW_ACT : 42|1@1+ (1.0,0.0) [0.0|1.0] ""  ABS,ESC,TCU,TPMS
	SG_ AUTO_ACT : 43|1@1+ (1.0,0.0) [0.0|1.0] ""  ABS,ESC,TPMS
	SG_ LOCK_ACT : 44|1@1+ (1.0,0.0) [0.0|1.0] ""  ABS,CLU,ESC,TPMS
	SG_ _4WD_TQC_CUR : 48|16@1+ (1.0,0.0) [0.0|65535.0] "Nm"  ABS,ESC

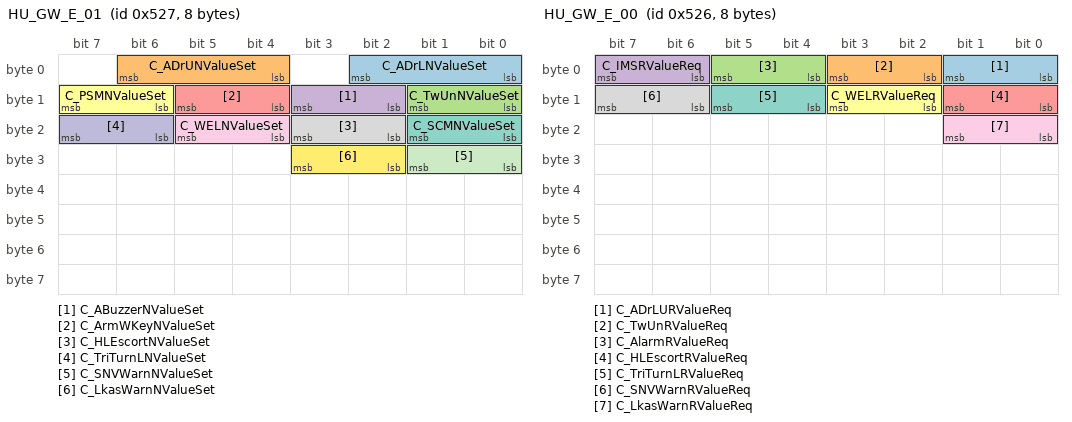
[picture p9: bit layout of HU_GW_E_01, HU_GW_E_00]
BO_ 1319 HU_GW_E_01: 8 CLU
	SG_ C_ADrLNValueSet : 0|3@1+ (1.0,0.0) [0.0|7.0] ""  BCM
	SG_ C_ADrUNValueSet : 4|3@1+ (1.0,0.0) [0.0|7.0] ""  BCM
	SG_ C_TwUnNValueSet : 8|2@1+ (1.0,0.0) [0.0|3.0] ""  BCM
	SG_ C_ABuzzerNValueSet : 10|2@1+ (1.0,0.0) [0.0|3.0] ""  BCM
	SG_ C_ArmWKeyNValueSet : 12|2@1+ (1.0,0.0) [0.0|3.0] ""  BCM
	SG_ C_PSMNValueSet : 14|2@1+ (1.0,0.0) [0.0|3.0] ""  BCM
	SG_ C_SCMNValueSet : 16|2@1+ (1.0,0.0) [0.0|3.0] ""  BCM
	SG_ C_HLEscortNValueSet : 18|2@1+ (1.0,0.0) [0.0|3.0] ""  BCM
	SG_ C_WELNValueSet : 20|2@1+ (1.0,0.0) [0.0|3.0] ""  BCM
	SG_ C_TriTurnLNValueSet : 22|2@1+ (1.0,0.0) [0.0|3.0] ""  BCM
	SG_ C_SNVWarnNValueSet : 24|2@1+ (1.0,0.0) [0.0|3.0] ""  BCM
	SG_ C_LkasWarnNValueSet : 26|2@1+ (1.0,0.0) [0.0|3.0] ""  BCM

BO_ 1318 HU_GW_E_00: 8 CLU
	SG_ C_ADrLURValueReq : 0|2@1+ (1.0,0.0) [0.0|3.0] ""  BCM
	SG_ C_TwUnRValueReq : 2|2@1+ (1.0,0.0) [0.0|3.0] ""  BCM
	SG_ C_AlarmRValueReq : 4|2@1+ (1.0,0.0) [0.0|3.0] ""  BCM
	SG_ C_IMSRValueReq : 6|2@1+ (1.0,0.0) [0.0|3.0] ""  BCM
	SG_ C_HLEscortRValueReq : 8|2@1+ (1.0,0.0) [0.0|3.0] ""  BCM
	SG_ C_WELRValueReq : 10|2@1+ (1.0,0.0) [0.0|3.0] ""  BCM
	SG_ C_TriTurnLRValueReq : 12|2@1+ (1.0,0.0) [0.0|3.0] ""  BCM
	SG_ C_SNVWarnRValueReq : 14|2@1+ (1.0,0.0) [0.0|3.0] ""  BCM
	SG_ C_LkasWarnRValueReq : 16|2@1+ (1.0,0.0) [0.0|3.0] ""  BCM

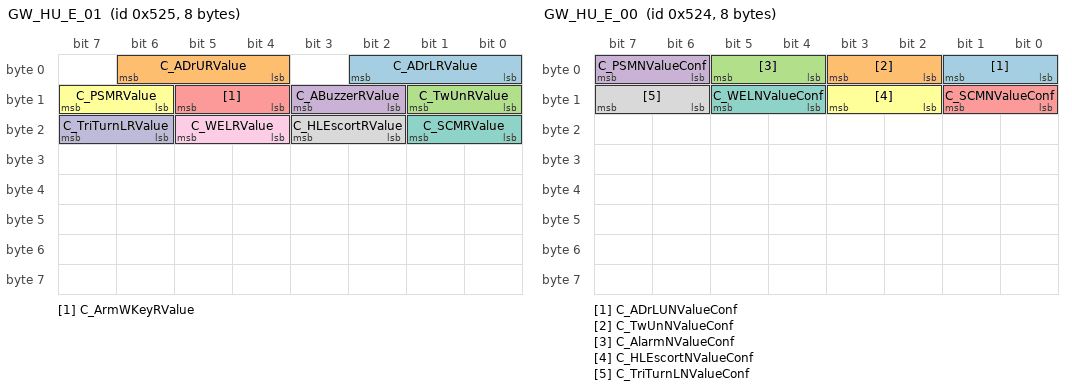
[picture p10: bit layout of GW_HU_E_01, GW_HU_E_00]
BO_ 1317 GW_HU_E_01: 8 BCM
	SG_ C_ADrLRValue : 0|3@1+ (1.0,0.0) [0.0|7.0] ""  CLU
	SG_ C_ADrURValue : 4|3@1+ (1.0,0.0) [0.0|7.0] ""  CLU
	SG_ C_TwUnRValue : 8|2@1+ (1.0,0.0) [0.0|3.0] ""  CLU
	SG_ C_ABuzzerRValue : 10|2@1+ (1.0,0.0) [0.0|3.0] ""  CLU
	SG_ C_ArmWKeyRValue : 12|2@1+ (1.0,0.0) [0.0|3.0] ""  CLU
	SG_ C_PSMRValue : 14|2@1+ (1.0,0.0) [0.0|3.0] ""  CLU
	SG_ C_SCMRValue : 16|2@1+ (1.0,0.0) [0.0|3.0] ""  CLU
	SG_ C_HLEscortRValue : 18|2@1+ (1.0,0.0) [0.0|3.0] ""  CLU
	SG_ C_WELRValue : 20|2@1+ (1.0,0.0) [0.0|3.0] ""  CLU
	SG_ C_TriTurnLRValue : 22|2@1+ (1.0,0.0) [0.0|3.0] ""  CLU

BO_ 1316 GW_HU_E_00: 8 BCM
	SG_ C_ADrLUNValueConf : 0|2@1+ (1.0,0.0) [0.0|3.0] ""  CLU
	SG_ C_TwUnNValueConf : 2|2@1+ (1.0,0.0) [0.0|3.0] ""  CLU
	SG_ C_AlarmNValueConf : 4|2@1+ (1.0,0.0) [0.0|3.0] ""  CLU
	SG_ C_PSMNValueConf : 6|2@1+ (1.0,0.0) [0.0|3.0] ""  CLU
	SG_ C_SCMNValueConf : 8|2@1+ (1.0,0.0) [0.0|3.0] ""  CLU
	SG_ C_HLEscortNValueConf : 10|2@1+ (1.0,0.0) [0.0|3.0] ""  CLU
	SG_ C_WELNValueConf : 12|2@1+ (1.0,0.0) [0.0|3.0] ""  CLU
	SG_ C_TriTurnLNValueConf : 14|2@1+ (1.0,0.0) [0.0|3.0] ""  CLU

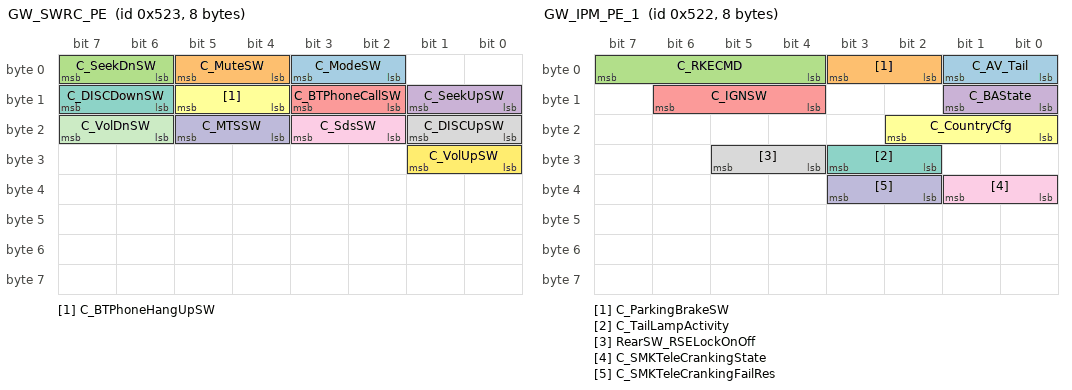
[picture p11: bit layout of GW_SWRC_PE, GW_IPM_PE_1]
BO_ 1315 GW_SWRC_PE: 8 BCM
	SG_ C_ModeSW : 2|2@1+ (1.0,0.0) [0.0|3.0] ""  CLU
	SG_ C_MuteSW : 4|2@1+ (1.0,0.0) [0.0|3.0] ""  CLU
	SG_ C_SeekDnSW : 6|2@1+ (1.0,0.0) [0.0|3.0] ""  CLU
	SG_ C_SeekUpSW : 8|2@1+ (1.0,0.0) [0.0|3.0] ""  CLU
	SG_ C_BTPhoneCallSW : 10|2@1+ (1.0,0.0) [0.0|3.0] ""  CLU
	SG_ C_BTPhoneHangUpSW : 12|2@1+ (1.0,0.0) [0.0|3.0] ""  CLU
	SG_ C_DISCDownSW : 14|2@1+ (1.0,0.0) [0.0|3.0] ""  CLU
	SG_ C_DISCUpSW : 16|2@1+ (1.0,0.0) [0.0|3.0] ""  CLU
	SG_ C_SdsSW : 18|2@1+ (1.0,0.0) [0.0|3.0] ""  CLU
	SG_ C_MTSSW : 20|2@1+ (1.0,0.0) [0.0|3.0] ""  CLU
	SG_ C_VolDnSW : 22|2@1+ (1.0,0.0) [0.0|3.0] ""  CLU
	SG_ C_VolUpSW : 24|2@1+ (1.0,0.0) [0.0|3.0] ""  CLU

BO_ 1314 GW_IPM_PE_1: 8 BCM
	SG_ C_AV_Tail : 0|2@1+ (1.0,0.0) [0.0|3.0] ""  CLU
	SG_ C_ParkingBrakeSW : 2|2@1+ (1.0,0.0) [0.0|3.0] ""  CLU
	SG_ C_RKECMD : 4|4@1+ (1.0,0.0) [0.0|15.0] ""  CLU
	SG_ C_BAState : 8|2@1+ (1.0,0.0) [0.0|3.0] ""  CLU
	SG_ C_IGNSW : 12|3@1+ (1.0,0.0) [0.0|7.0] ""  CLU
	SG_ C_CountryCfg : 16|3@1+ (1.0,0.0) [0.0|7.0] ""  CLU
	SG_ C_TailLampActivity : 26|2@1+ (1.0,0.0) [0.0|3.0] ""  CLU
	SG_ RearSW_RSELockOnOff : 28|2@1+ (1.0,0.0) [0.0|3.0] ""  CLU
	SG_ C_SMKTeleCrankingState : 32|2@1+ (1.0,0.0) [0.0|3.0] ""  CLU
	SG_ C_SMKTeleCrankingFailRes : 34|2@1+ (1.0,0.0) [0.0|3.0] ""  CLU

BO_ 1057 SCC12: 8 SCC
	SG_ CF_VSM_Prefill : 0|1@1+ (1.0,0.0) [0.0|1.0] ""  ESC
	SG_ CF_VSM_DecCmdAct : 1|1@1+ (1.0,0.0) [0.0|1.0] ""  ESC
	SG_ CF_VSM_HBACmd : 2|2@1+ (1.0,0.0) [0.0|3.0] ""  ESC
	SG_ CF_VSM_Warn : 4|2@1+ (1.0,0.0) [0.0|3.0] ""  CLU,ESC,IAP
	SG_ CF_VSM_Stat : 6|2@1+ (1.0,0.0) [0.0|3.0] ""  CLU,ESC,PSB
	SG_ CF_VSM_BeltCmd : 8|3@1+ (1.0,0.0) [0.0|7.0] ""  ESC,PSB
	SG_ ACCFailInfo : 11|2@1+ (1.0,0.0) [0.0|3.0] ""  CLU,CUBIS,ESC,IBOX
	SG_ ACCMode : 13|2@1+ (1.0,0.0) [0.0|3.0] ""  CLU,ESC,IBOX,TCU
	SG_ StopReq : 15|1@1+ (1.0,0.0) [0.0|1.0] ""  EPB,ESC
	SG_ CR_VSM_DecCmd : 16|8@1+ (0.01,0.0) [0.0|2.55] "g"  ESC
	SG_ aReqMax : 24|11@1+ (0.01,-10.23) [-10.23|10.24] "m/s^2"  EMS,ESC,TCU
	SG_ TakeOverReq : 35|1@1+ (1.0,0.0) [0.0|1.0] ""  CLU,ESC,TCU
	SG_ PreFill : 36|1@1+ (1.0,0.0) [0.0|1.0] ""  ESC,TCU
	SG_ aReqMin : 37|11@1+ (0.01,-10.23) [-10.23|10.24] "m/s^2"  EMS,ESC,TCU
	SG_ CF_VSM_ConfMode : 48|2@1+ (1.0,0.0) [0.0|3.0] ""  CLU,ESC
	SG_ AEB_Failinfo : 50|2@1+ (1.0,0.0) [0.0|3.0] ""  CLU,ESC
	SG_ AEB_Status : 52|2@1+ (1.0,0.0) [0.0|3.0] ""  CLU,ESC
	SG_ AEB_CmdAct : 54|1@1+ (1.0,0.0) [0.0|1.0] ""  ESC
	SG_ AEB_StopReq : 55|1@1+ (1.0,0.0) [0.0|1.0] ""  CLU,ESC
	SG_ CR_VSM_Alive : 56|4@1+ (1.0,0.0) [0.0|15.0] ""  ESC,PSB
	SG_ CR_VSM_ChkSum : 60|4@1+ (1.0,0.0) [0.0|15.0] ""  ESC,PSB

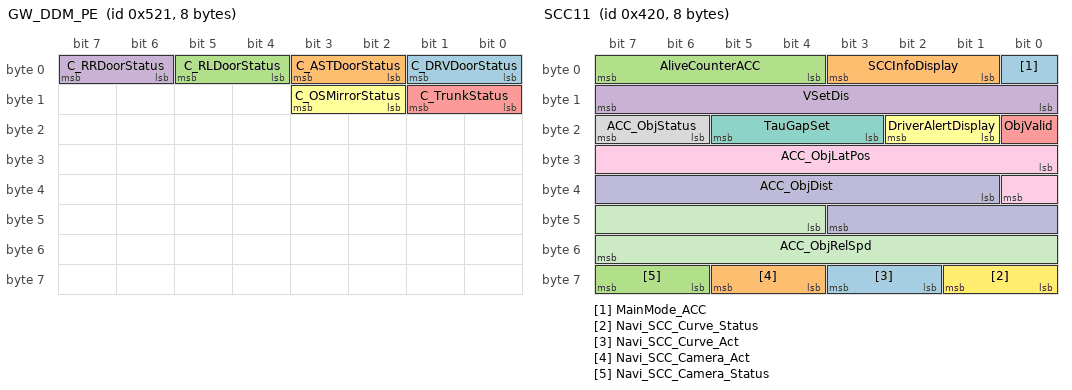
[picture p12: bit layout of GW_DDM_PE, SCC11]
BO_ 1313 GW_DDM_PE: 8 BCM
	SG_ C_DRVDoorStatus : 0|2@1+ (1.0,0.0) [0.0|3.0] ""  CLU
	SG_ C_ASTDoorStatus : 2|2@1+ (1.0,0.0) [0.0|3.0] ""  CLU
	SG_ C_RLDoorStatus : 4|2@1+ (1.0,0.0) [0.0|3.0] ""  CLU
	SG_ C_RRDoorStatus : 6|2@1+ (1.0,0.0) [0.0|3.0] ""  CLU
	SG_ C_TrunkStatus : 8|2@1+ (1.0,0.0) [0.0|3.0] ""  CLU
	SG_ C_OSMirrorStatus : 10|2@1+ (1.0,0.0) [0.0|3.0] ""  CLU

BO_ 1056 SCC11: 8 SCC
	SG_ MainMode_ACC : 0|1@1+ (1.0,0.0) [0.0|1.0] ""  CLU,EMS,ESC
	SG_ SCCInfoDisplay : 1|3@1+ (1.0,0.0) [0.0|7.0] ""  CLU,ESC
	SG_ AliveCounterACC : 4|4@1+ (1.0,0.0) [0.0|15.0] ""  CLU,EMS,ESC,TCU
	SG_ VSetDis : 8|8@1+ (1.0,0.0) [0.0|255.0] "km/h or MPH"  CLU,ESC,TCU
	SG_ ObjValid : 16|1@1+ (1.0,0.0) [0.0|1.0] ""  CLU,ESC,TCU
	SG_ DriverAlertDisplay : 17|2@1+ (1.0,0.0) [0.0|3.0] ""  CLU,ESC
	SG_ TauGapSet : 19|3@1+ (1.0,0.0) [0.0|7.0] ""  CLU,ESC,TCU
	SG_ ACC_ObjStatus : 22|2@1+ (1.0,0.0) [0.0|3.0] ""  ABS,ESC
	SG_ ACC_ObjLatPos : 24|9@1+ (0.1,-20.0) [-20.0|31.1] "m"  ABS,ESC
	SG_ ACC_ObjDist : 33|11@1+ (0.1,0.0) [0.0|204.7] "m"  ABS,ESC
	SG_ ACC_ObjRelSpd : 44|12@1+ (0.1,-170.0) [-170.0|239.5] "m/s"  ABS,ESC
	SG_ Navi_SCC_Curve_Status : 56|2@1+ (1.0,0.0) [0.0|3.0] ""  CLU
	SG_ Navi_SCC_Curve_Act : 58|2@1+ (1.0,0.0) [0.0|3.0] ""  CLU
	SG_ Navi_SCC_Camera_Act : 60|2@1+ (1.0,0.0) [0.0|3.0] ""  CLU
	SG_ Navi_SCC_Camera_Status : 62|2@1+ (1.0,0.0) [0.0|3.0] ""  CLU

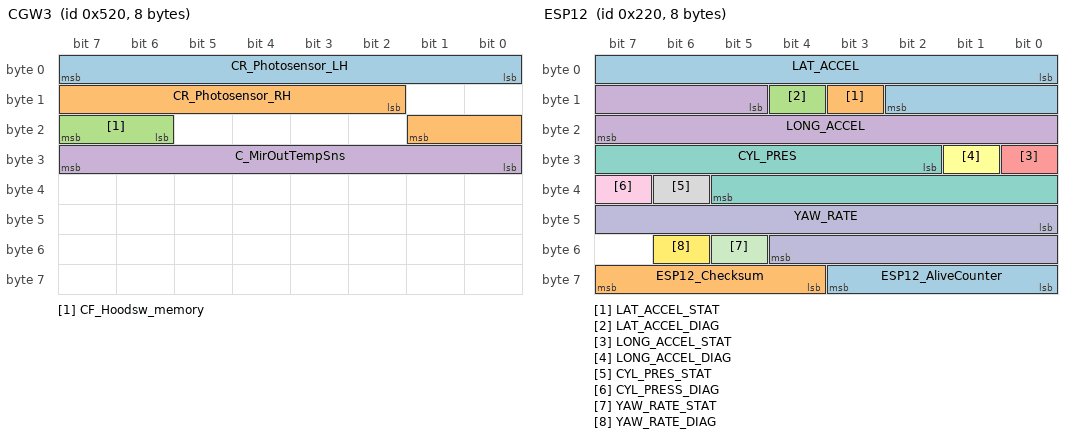
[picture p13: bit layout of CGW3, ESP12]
BO_ 1312 CGW3: 8 BCM
	SG_ CR_Photosensor_LH : 0|8@1+ (78.125,0.0) [0.0|20000.0] ""  DATC,DATC
	SG_ CR_Photosensor_RH : 10|8@1+ (78.125,0.0) [0.0|20000.0] ""  DATC,DATC
	SG_ CF_Hoodsw_memory : 22|2@1+ (1.0,0.0) [0.0|3.0] ""  EMS,EMS
	SG_ C_MirOutTempSns : 24|8@1+ (0.5,-40.5) [-40.0|60.0] "¡É"  AAF,CLU,DATC,EMS,SPAS,AAF,DATC,EMS,SPAS

BO_ 544 ESP12: 8 ESC
	SG_ LAT_ACCEL : 0|11@1+ (0.01,-10.23) [-10.23|10.24] "m/s^2"  _4WD,ECS,IBOX,LCA,LDWS_LKAS,MDPS,PSB,SCC,TCU
	SG_ LAT_ACCEL_STAT : 11|1@1+ (1.0,0.0) [0.0|1.0] ""  _4WD,IBOX,LDWS_LKAS,MDPS,PSB,SCC,TCU
	SG_ LAT_ACCEL_DIAG : 12|1@1+ (1.0,0.0) [0.0|1.0] ""  _4WD,IBOX,LDWS_LKAS,MDPS,PSB,SCC,TCU
	SG_ LONG_ACCEL : 13|11@1+ (0.01,-10.23) [-10.23|10.24] "m/s^2"  _4WD,ECS,EMS,EPB,IBOX,LCA,LDWS_LKAS,PSB,SCC,SPAS,TCU
	SG_ LONG_ACCEL_STAT : 24|1@1+ (1.0,0.0) [0.0|1.0] ""  _4WD,EMS,EPB,IBOX,LDWS_LKAS,PSB,SCC,SPAS,TCU
	SG_ LONG_ACCEL_DIAG : 25|1@1+ (1.0,0.0) [0.0|1.0] ""  _4WD,EMS,EPB,IBOX,LDWS_LKAS,PSB,SCC,SPAS,TCU
	SG_ CYL_PRES : 26|12@1+ (0.1,0.0) [0.0|409.5] "Bar"  _4WD,ECS,EMS,EPB,IBOX,LDWS_LKAS,PSB,SCC,TCU
	SG_ CYL_PRES_STAT : 38|1@1+ (1.0,0.0) [0.0|1.0] ""  _4WD,ECS,EMS,EPB,IBOX,LDWS_LKAS,PSB,SCC,TCU
	SG_ CYL_PRESS_DIAG : 39|1@1+ (1.0,0.0) [0.0|1.0] ""  _4WD,ECS,EMS,EPB,IBOX,PSB,SCC,TCU
	SG_ YAW_RATE : 40|13@1+ (0.01,-40.95) [-40.95|40.96] "¢ª/s"  _4WD,AFLS,IBOX,LCA,LDWS_LKAS,MDPS,PSB,SCC,SPAS,TCU
	SG_ YAW_RATE_STAT : 53|1@1+ (1.0,0.0) [0.0|1.0] ""  _4WD,AFLS,IBOX,LCA,LDWS_LKAS,MDPS,PSB,SCC,SPAS,TCU
	SG_ YAW_RATE_DIAG : 54|1@1+ (1.0,0.0) [0.0|1.0] ""  _4WD,AFLS,IBOX,LCA,LDWS_LKAS,MDPS,PSB,SCC,SPAS,TCU
	SG_ ESP12_AliveCounter : 56|4@1+ (1.0,0.0) [0.0|15.0] ""  _4WD,EMS,LPI,TCU,TMU
	SG_ ESP12_Checksum : 60|4@1+ (1.0,0.0) [0.0|15.0] ""  _4WD,EMS,LPI,TCU,TMU

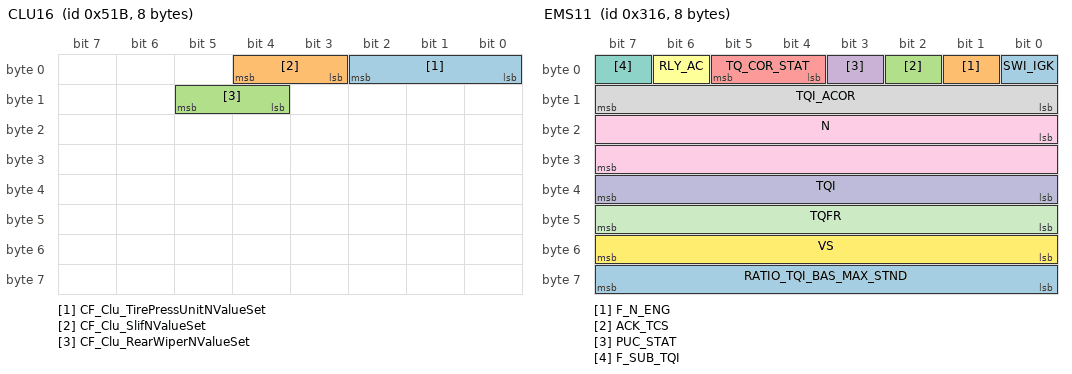
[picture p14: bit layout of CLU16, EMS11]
BO_ 1307 CLU16: 8 CLU
	SG_ CF_Clu_TirePressUnitNValueSet : 0|3@1+ (1.0,0.0) [0.0|7.0] ""  TPMS
	SG_ CF_Clu_SlifNValueSet : 3|2@1+ (1.0,0.0) [0.0|3.0] ""  LDWS_LKAS
	SG_ CF_Clu_RearWiperNValueSet : 12|2@1+ (1.0,0.0) [0.0|3.0] ""  BCM

BO_ 790 EMS11: 8 EMS
	SG_ SWI_IGK : 0|1@1+ (1.0,0.0) [0.0|1.0] ""  _4WD,ABS,ACU,AHLS,CUBIS,DI_BOX,ECS,EPB,ESC,IBOX,LDWS_LKAS,MDPS,REA,SAS,SCC,TCU
	SG_ F_N_ENG : 1|1@1+ (1.0,0.0) [0.0|1.0] ""  _4WD,ACU,AFLS,CLU,CUBIS,DATC,ECS,EPB,ESC,IBOX,MDPS,SCC,TCU
	SG_ ACK_TCS : 2|1@1+ (1.0,0.0) [0.0|1.0] ""  ESC,IBOX
	SG_ PUC_STAT : 3|1@1+ (1.0,0.0) [0.0|1.0] ""  _4WD,CLU,DATC,IBOX,TCU
	SG_ TQ_COR_STAT : 4|2@1+ (1.0,0.0) [0.0|3.0] ""  _4WD,ESC,IBOX,TCU
	SG_ RLY_AC : 6|1@1+ (1.0,0.0) [0.0|1.0] ""  DATC,IBOX,TCU
	SG_ F_SUB_TQI : 7|1@1+ (1.0,0.0) [0.0|1.0] ""  _4WD,ECS,EPB,ESC,IBOX,TCU
	SG_ TQI_ACOR : 8|8@1+ (0.390625,0.0) [0.0|99.6094] "%"  _4WD,EPB,ESC,IBOX,TCU
	SG_ N : 16|16@1+ (0.25,0.0) [0.0|16383.75] "rpm"  _4WD,ACU,AFLS,CLU,CUBIS,DATC,ECS,EPB,ESC,FPCM,IBOX,MDPS,SCC,TCU
	SG_ TQI : 32|8@1+ (0.390625,0.0) [0.0|99.6094] "%"  _4WD,ECS,EPB,ESC,IBOX,TCU
	SG_ TQFR : 40|8@1+ (0.390625,0.0) [0.0|99.6094] "%"  _4WD,EPB,ESC,IBOX,TCU
	SG_ VS : 48|8@1+ (1.0,0.0) [0.0|254.0] "km/h"  _4WD,AAF,ACU,AHLS,BCM,CLU,DATC,ECS,EPB,IBOX,LCA,LDWS_LKAS,LVR,MDPS,ODS,SCC,SMK,SPAS,TCU,TPMS
	SG_ RATIO_TQI_BAS_MAX_STND : 56|8@1+ (0.0078,0.0) [0.0|2.0] ""  _4WD,IBOX,TCU

BO_ 1301 CLU14: 8 CLU
	SG_ CF_Clu_ADrUNValueSet : 0|3@1+ (1.0,0.0) [0.0|7.0] ""  BCM
	SG_ CF_Clu_ADrLNValueSet : 3|3@1+ (1.0,0.0) [0.0|7.0] ""  BCM
	SG_ CF_Clu_EscortHLNValueSet : 6|2@1+ (1.0,0.0) [0.0|3.0] ""  BCM
	SG_ CF_Clu_DoorLSNValueSet : 8|3@1+ (1.0,0.0) [0.0|7.0] ""  BCM
	SG_ CF_Clu_PSMNValueSet : 11|3@1+ (1.0,0.0) [0.0|7.0] ""  BCM
	SG_ CF_Clu_TTUnlockNValueSet : 14|2@1+ (1.0,0.0) [0.0|3.0] ""  BCM
	SG_ CF_Clu_PTGMNValueSet : 16|2@1+ (1.0,0.0) [0.0|3.0] ""  BCM
	SG_ CF_Clu_SCMNValueSet : 18|2@1+ (1.0,0.0) [0.0|3.0] ""  BCM
	SG_ CF_Clu_WlightNValueSet : 20|2@1+ (1.0,0.0) [0.0|3.0] ""  BCM
	SG_ CF_Clu_TempUnitNValueSet : 22|2@1+ (1.0,0.0) [0.0|3.0] ""  BCM,DATC
	SG_ CF_Clu_MoodLpNValueSet : 24|3@1+ (1.0,0.0) [0.0|7.0] ""  BCM
	SG_ CF_Clu_TrfChgSet : 27|2@1+ (1.0,0.0) [0.0|3.0] ""  AFLS
	SG_ CF_Clu_OTTurnNValueSet : 29|3@1+ (1.0,0.0) [0.0|7.0] ""  BCM
	SG_ CF_Clu_LcaNValueSet : 32|2@1+ (1.0,0.0) [0.0|3.0] ""  LCA
	SG_ CF_Clu_RctaNValueSet : 34|2@1+ (1.0,0.0) [0.0|3.0] ""  LCA
	SG_ CF_Clu_RcwNValueSet : 36|2@1+ (1.0,0.0) [0.0|3.0] ""  LCA
	SG_ CF_Clu_EscOffNValueSet : 38|3@1+ (1.0,0.0) [0.0|7.0] ""  ESC
	SG_ CF_Clu_SccNaviCrvNValueSet : 41|2@1+ (1.0,0.0) [0.0|3.0] ""  SCC
	SG_ CF_Clu_SccNaviCamNValueSet : 43|2@1+ (1.0,0.0) [0.0|3.0] ""  SCC
	SG_ CF_Clu_SccAebNValueSet : 45|2@1+ (1.0,0.0) [0.0|3.0] ""  SCC
	SG_ CF_Clu_LkasModeNValueSet : 47|2@1+ (1.0,0.0) [0.0|3.0] ""  LDWS_LKAS
	SG_ CF_Clu_FcwNValueSet : 51|2@1+ (1.0,0.0) [0.0|3.0] ""  LDWS_LKAS
	SG_ CF_Clu_PasSpkrLvNValueSet : 53|3@1+ (1.0,0.0) [0.0|7.0] ""  BCM
	SG_ CF_Clu_SccDrvModeNValueSet : 56|3@1+ (1.0,0.0) [0.0|7.0] ""  SCC
	SG_ CF_Clu_HAnBNValueSet : 59|2@1+ (1.0,0.0) [0.0|3.0] ""  BCM
	SG_ CF_Clu_HfreeTrunkTgNValueSet : 61|3@1+ (1.0,0.0) [0.0|7.0] ""  BCM

BO_ 275 TCU13: 8 TCU
	SG_ N_TGT_LUP : 0|8@1+ (10.0,500.0) [500.0|3040.0] "rpm"  EMS,IBOX
	SG_ SLOPE_TCU : 8|6@1+ (0.5,-16.0) [-16.0|15.5] "%"  CLU,CUBIS,EMS,IBOX
	SG_ CF_Tcu_InhCda : 14|1@1+ (1.0,0.0) [0.0|1.0] ""  EMS,IBOX
	SG_ CF_Tcu_IsgInhib : 15|1@1+ (1.0,0.0) [0.0|1.0] ""  EMS,IBOX
	SG_ CF_Tcu_BkeOnReq : 16|2@1+ (1.0,0.0) [0.0|3.0] ""  EMS,IBOX
	SG_ CF_Tcu_NCStat : 18|2@1+ (1.0,0.0) [0.0|3.0] ""  EMS,IBOX
	SG_ CF_Tcu_TarGr : 20|4@1+ (1.0,0.0) [0.0|15.0] ""  _4WD,CLU,DATC,EMS,EPB,ESC,IBOX,SCC
	SG_ CF_Tcu_ShfPatt : 24|4@1+ (1.0,0.0) [0.0|15.0] ""  CLU,CUBIS,EMS,IBOX
	SG_ CF_Tcu_InhVis : 28|1@1+ (1.0,0.0) [0.0|1.0] ""  EMS,IBOX
	SG_ CF_Tcu_PRelReq : 29|1@1+ (1.0,0.0) [0.0|1.0] ""  IBOX,LVR
	SG_ CF_Tcu_ITPhase : 30|1@1+ (1.0,0.0) [0.0|1.0] ""  EMS,IBOX
	SG_ CF_Tcu_ActEcoRdy : 31|1@1+ (1.0,0.0) [0.0|1.0] ""  EMS,IBOX
	SG_ CF_Tcu_TqGrdLim : 32|8@1+ (10.0,0.0) [0.0|2540.0] "Nm/s"  EMS,IBOX
	SG_ CR_Tcu_IsgTgtRPM : 40|8@1+ (20.0,0.0) [0.0|3500.0] "rpm"  EMS,IBOX
	SG_ CF_Tcu_SptRdy : 48|1@1+ (1.0,0.0) [0.0|1.0] ""  CLU,IBOX
	SG_ CF_Tcu_SbwPInfo : 56|1@1+ (1.0,0.0) [0.0|1.0] ""  EMS,IBOX
	SG_ CF_Tcu_Alive3 : 58|2@1+ (1.0,0.0) [0.0|3.0] ""  EMS,IBOX
	SG_ CF_Tcu_ChkSum3 : 60|4@1+ (1.0,0.0) [0.0|15.0] ""  EMS,IBOX

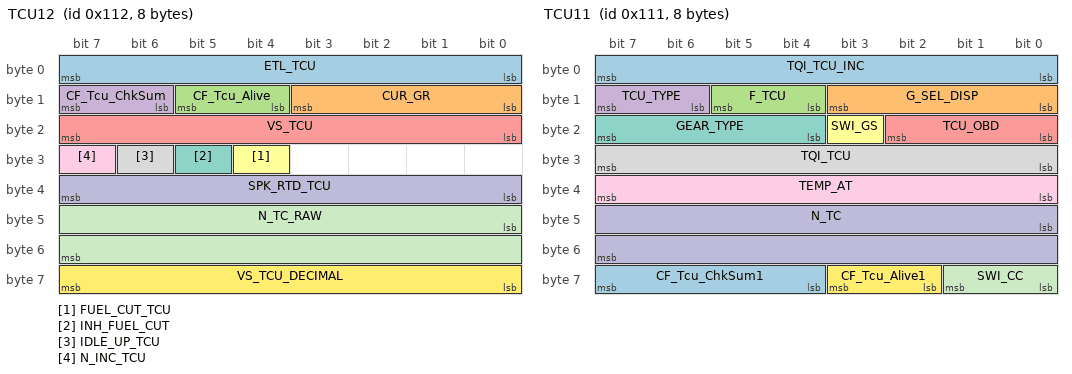
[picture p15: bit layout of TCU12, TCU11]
BO_ 274 TCU12: 8 TCU
	SG_ ETL_TCU : 0|8@1+ (2.0,0.0) [0.0|508.0] "Nm"  EMS,IBOX
	SG_ CUR_GR : 8|4@1+ (1.0,0.0) [0.0|15.0] ""  _4WD,EMS,ESC,IBOX,SCC,TPMS
	SG_ CF_Tcu_Alive : 12|2@1+ (1.0,0.0) [0.0|3.0] ""  EMS,ESC,IBOX,SCC
	SG_ CF_Tcu_ChkSum : 14|2@1+ (1.0,0.0) [0.0|3.0] ""  EMS,ESC,IBOX,SCC
	SG_ VS_TCU : 16|8@1+ (1.0,0.0) [0.0|254.0] "km/h"  BCM,CLU,DATC,EMS,IBOX,LCA,LVR,PGS,SMK,SNV
	SG_ FUEL_CUT_TCU : 28|1@1+ (1.0,0.0) [0.0|1.0] ""  EMS,IBOX
	SG_ INH_FUEL_CUT : 29|1@1+ (1.0,0.0) [0.0|1.0] ""  EMS,IBOX
	SG_ IDLE_UP_TCU : 30|1@1+ (1.0,0.0) [0.0|1.0] ""  EMS,IBOX
	SG_ N_INC_TCU : 31|1@1+ (1.0,0.0) [0.0|1.0] ""  EMS,IBOX
	SG_ SPK_RTD_TCU : 32|8@1+ (0.375,-23.625) [-15.0|15.0] "¢ª"  EMS,IBOX
	SG_ N_TC_RAW : 40|16@1+ (0.25,0.0) [0.0|16383.5] "rpm"  EMS,IBOX
	SG_ VS_TCU_DECIMAL : 56|8@1+ (0.0078125,0.0) [0.0|0.9921875] "km/h"  CLU,EMS,IBOX,LCA

BO_ 273 TCU11: 8 TCU
	SG_ TQI_TCU_INC : 0|8@1+ (0.390625,0.0) [0.0|99.609375] "%"  EMS,ESC,IBOX
	SG_ G_SEL_DISP : 8|4@1+ (1.0,0.0) [0.0|15.0] ""  _4WD,AFLS,AVM,BCM,CGW,CLU,CUBIS,ECS,EMS,EPB,ESC,IAP,IBOX,LCA,LDWS_LKAS,LVR,MDPS,PGS,SCC,SMK,SNV,SPAS,TPMS
	SG_ F_TCU : 12|2@1+ (1.0,0.0) [0.0|3.0] ""  EMS,ESC,IBOX
	SG_ TCU_TYPE : 14|2@1+ (1.0,0.0) [0.0|3.0] ""  _4WD,EMS,ESC,IBOX
	SG_ TCU_OBD : 16|3@1+ (1.0,0.0) [0.0|7.0] ""  EMS,ESC,IBOX
	SG_ SWI_GS : 19|1@1+ (1.0,0.0) [0.0|1.0] ""  _4WD,EMS,EPB,ESC,IBOX,SCC
	SG_ GEAR_TYPE : 20|4@1+ (1.0,0.0) [0.0|15.0] ""  _4WD,CLU,EMS,ESC,IBOX,SCC
	SG_ TQI_TCU : 24|8@1+ (0.390625,0.0) [0.0|99.609375] "%"  EMS,ESC,IBOX
	SG_ TEMP_AT : 32|8@1+ (1.0,-40.0) [-40.0|214.0] "¡É"  AAF,CLU,CUBIS,EMS,ESC,IBOX
	SG_ N_TC : 40|16@1+ (0.25,0.0) [0.0|16383.5] "rpm"  _4WD,EMS,EPB,ESC,IBOX
	SG_ SWI_CC : 56|2@1+ (1.0,0.0) [0.0|3.0] ""  _4WD,CLU,EMS,ESC,IBOX
	SG_ CF_Tcu_Alive1 : 58|2@1+ (1.0,0.0) [0.0|3.0] ""  EMS,IBOX
	SG_ CF_Tcu_ChkSum1 : 60|4@1+ (1.0,0.0) [0.0|15.0] ""  EMS,IBOX

BO_ 16 ACU13: 8 ACU
	SG_ CF_Acu_CshAct : 0|1@1+ (1.0,0.0) [0.0|1.0] ""  CUBIS,IBOX,ODS

BO_ 1040 CGW_USM1: 8 BCM
	SG_ CF_Gway_ATTurnRValue : 0|2@1+ (1.0,0.0) [0.0|3.0] ""  CLU
	SG_ CF_Gway_PTGMRValue : 2|2@1+ (1.0,0.0) [0.0|3.0] ""  CLU
	SG_ CF_Gway_EscortHLRValue : 4|2@1+ (1.0,0.0) [0.0|3.0] ""  CLU
	SG_ CF_Gway_TTUnlockRValue : 6|2@1+ (1.0,0.0) [0.0|3.0] ""  CLU
	SG_ CF_Gway_ADrLRValue : 8|3@1+ (1.0,0.0) [0.0|7.0] ""  CLU
	SG_ CF_Gway_ADrURValue : 11|3@1+ (1.0,0.0) [0.0|7.0] ""  CLU
	SG_ CF_Gway_SCMRValue : 14|2@1+ (1.0,0.0) [0.0|3.0] ""  CLU
	SG_ CF_Gway_WlightRValue : 16|2@1+ (1.0,0.0) [0.0|3.0] ""  CLU
	SG_ CF_Gway_PSMRValue : 18|3@1+ (1.0,0.0) [0.0|7.0] ""  CLU
	SG_ CF_Gway_OTTurnRValue : 21|3@1+ (1.0,0.0) [0.0|7.0] ""  CLU
	SG_ CF_Gway_DrLockSoundRValue : 24|3@1+ (1.0,0.0) [0.0|7.0] ""  CLU
	SG_ CF_Gway_HAnBRValue : 27|3@1+ (1.0,0.0) [0.0|7.0] ""  CLU
	SG_ CF_Gway_MoodLpRValue : 30|2@1+ (1.0,0.0) [0.0|3.0] ""  CLU
	SG_ CF_Gway_HfreeTrunkRValue : 32|3@1+ (1.0,0.0) [0.0|7.0] ""  CLU
	SG_ CF_Gway_AutoLightRValue : 35|3@1+ (1.0,0.0) [0.0|7.0] ""  CLU
	SG_ CF_Gway_RearWiperRValue : 38|2@1+ (1.0,0.0) [0.0|3.0] ""  CLU
	SG_ CF_Gway_PasSpkrLvRValue : 40|3@1+ (1.0,0.0) [0.0|7.0] ""  CLU

BO_ 1292 CLU13: 8 CLU
	SG_ CF_Clu_LowfuelWarn : 0|2@1+ (1.0,0.0) [0.0|3.0] ""  BCM,FPCM,IBOX
	SG_ CF_Clu_RefDetMod : 2|1@1+ (1.0,0.0) [0.0|1.0] ""  IBOX
	SG_ CF_Clu_AvgFCU : 3|2@1+ (1.0,0.0) [0.0|3.0] ""  IBOX
	SG_ CF_Clu_AvsmCur : 5|1@1+ (1.0,0.0) [0.0|1.0] ""  ESC,SCC
	SG_ CF_Clu_AvgFCI : 6|10@1+ (0.1,0.0) [0.0|102.2] ""  IBOX
	SG_ CF_Clu_DrivingModeSwi : 16|2@1+ (1.0,0.0) [0.0|3.0] ""  DATC,ECS,EMS,ESC,IAP,MDPS,TCU
	SG_ CF_Clu_FuelDispLvl : 18|5@1+ (1.0,0.0) [0.0|31.0] ""  CGW,IBOX
	SG_ CF_Clu_FlexSteerSW : 23|1@1+ (1.0,0.0) [0.0|1.0] ""  MDPS
	SG_ CF_Clu_DTE : 24|10@1+ (1.0,0.0) [0.0|1023.0] ""  DATC
	SG_ CF_Clu_TripUnit : 34|2@1+ (1.0,0.0) [0.0|3.0] ""  DATC
	SG_ CF_Clu_SWL_Stat : 36|3@1+ (1.0,0.0) [0.0|7.0] ""  ACU,EMS
	SG_ CF_Clu_ActiveEcoSW : 39|1@1+ (1.0,0.0) [0.0|1.0] ""  DATC,EMS,TCU
	SG_ CF_Clu_EcoDriveInf : 40|3@1+ (1.0,0.0) [0.0|7.0] ""  CUBIS,EMS,IAP,IBOX
	SG_ CF_Clu_IsaMainSW : 43|1@1+ (1.0,0.0) [0.0|1.0] ""  EMS
	SG_ CF_Clu_LdwsLkasSW : 56|1@1+ (1.0,0.0) [0.0|1.0] ""  LDWS_LKAS
	SG_ CF_Clu_AltLStatus : 59|1@1+ (1.0,0.0) [0.0|1.0] ""  BCM,DATC,EMS
	SG_ CF_Clu_AliveCnt2 : 60|4@1+ (1.0,0.0) [0.0|15.0] ""  EMS,LDWS_LKAS

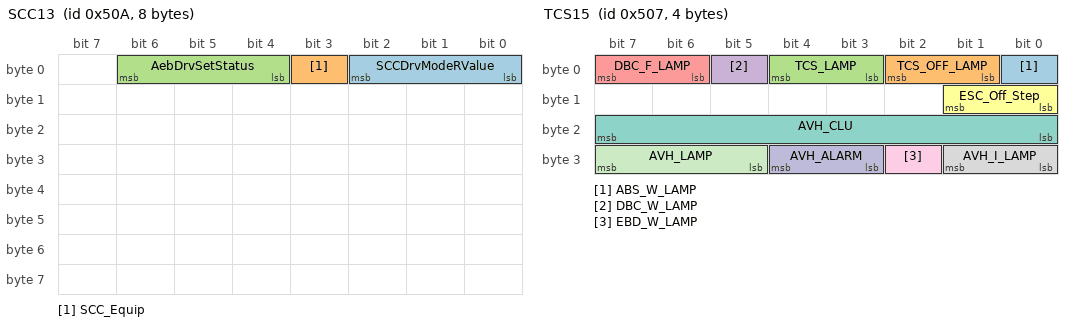
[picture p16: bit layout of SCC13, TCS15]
BO_ 1290 SCC13: 8 SCC
	SG_ SCCDrvModeRValue : 0|3@1+ (1.0,0.0) [0.0|7.0] ""  CLU
	SG_ SCC_Equip : 3|1@1+ (1.0,0.0) [0.0|1.0] ""  ESC
	SG_ AebDrvSetStatus : 4|3@1+ (1.0,0.0) [0.0|7.0] ""  CLU,ESC

BO_ 1287 TCS15: 4 ESC
	SG_ ABS_W_LAMP : 0|1@1+ (1.0,0.0) [0.0|1.0] ""  _4WD,CLU,CUBIS,IBOX
	SG_ TCS_OFF_LAMP : 1|2@1+ (1.0,0.0) [0.0|1.0] ""  _4WD,ACU,CLU
	SG_ TCS_LAMP : 3|2@1+ (1.0,0.0) [0.0|3.0] ""  _4WD,ACU,CLU,CUBIS,IBOX,SCC
	SG_ DBC_W_LAMP : 5|1@1+ (1.0,0.0) [0.0|1.0] ""  _4WD,CLU
	SG_ DBC_F_LAMP : 6|2@1+ (1.0,0.0) [0.0|3.0] ""  _4WD,CLU
	SG_ ESC_Off_Step : 8|2@1+ (1.0,0.0) [0.0|3.0] ""  CLU
	SG_ AVH_CLU : 16|8@1+ (1.0,0.0) [0.0|255.0] ""  CLU,EPB
	SG_ AVH_I_LAMP : 24|2@1+ (1.0,0.0) [0.0|3.0] ""  EPB
	SG_ EBD_W_LAMP : 26|1@1+ (1.0,0.0) [0.0|1.0] ""  _4WD,CLU
	SG_ AVH_ALARM : 27|2@1+ (1.0,0.0) [0.0|3.0] ""  CLU
	SG_ AVH_LAMP : 29|3@1+ (1.0,0.0) [0.0|7.0] ""  CLU,EPB,SPAS

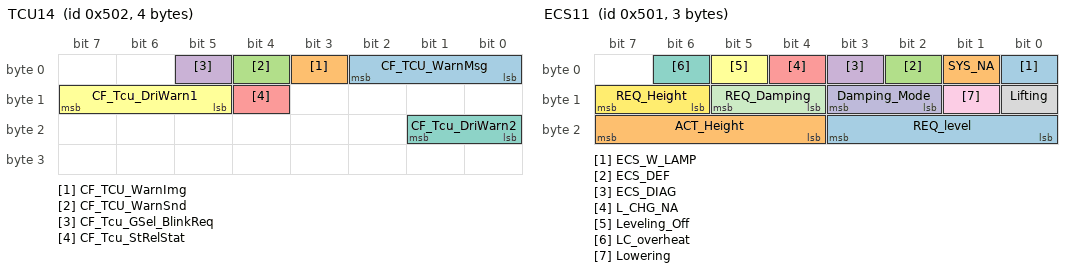
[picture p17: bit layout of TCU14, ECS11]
BO_ 1282 TCU14: 4 TCU
	SG_ CF_TCU_WarnMsg : 0|3@1+ (1.0,0.0) [0.0|7.0] ""  CLU
	SG_ CF_TCU_WarnImg : 3|1@1+ (1.0,0.0) [0.0|1.0] ""  CLU
	SG_ CF_TCU_WarnSnd : 4|1@1+ (1.0,0.0) [0.0|1.0] ""  CLU
	SG_ CF_Tcu_GSel_BlinkReq : 5|1@1+ (1.0,0.0) [0.0|1.0] ""  CLU,LVR
	SG_ CF_Tcu_StRelStat : 12|1@1+ (1.0,0.0) [0.0|1.0] ""  CLU,EMS,ESC
	SG_ CF_Tcu_DriWarn1 : 13|3@1+ (1.0,0.0) [0.0|7.0] ""  CLU,EMS,ESC
	SG_ CF_Tcu_DriWarn2 : 16|2@1+ (1.0,0.0) [0.0|3.0] ""  CLU,EMS,ESC

BO_ 1281 ECS11: 3 ECS
	SG_ ECS_W_LAMP : 0|1@1+ (1.0,0.0) [0.0|1.0] ""  CLU,CUBIS,IBOX
	SG_ SYS_NA : 1|1@1+ (1.0,0.0) [0.0|1.0] ""  CLU
	SG_ ECS_DEF : 2|1@1+ (1.0,0.0) [0.0|1.0] ""  CLU
	SG_ ECS_DIAG : 3|1@1+ (1.0,0.0) [0.0|1.0] ""  CLU
	SG_ L_CHG_NA : 4|1@1+ (1.0,0.0) [0.0|1.0] ""  CLU
	SG_ Leveling_Off : 5|1@1+ (1.0,0.0) [0.0|1.0] ""  CLU
	SG_ LC_overheat : 6|1@1+ (1.0,0.0) [0.0|1.0] ""  CLU
	SG_ Lifting : 8|1@1+ (1.0,0.0) [0.0|1.0] ""  CLU
	SG_ Lowering : 9|1@1+ (1.0,0.0) [0.0|1.0] ""  CLU
	SG_ Damping_Mode : 10|2@1+ (1.0,0.0) [0.0|3.0] ""  CLU
	SG_ REQ_Damping : 12|2@1+ (1.0,0.0) [0.0|3.0] ""  CLU
	SG_ REQ_Height : 14|2@1+ (1.0,0.0) [0.0|3.0] ""  CLU
	SG_ REQ_level : 16|4@1+ (1.0,0.0) [0.0|15.0] ""  CLU
	SG_ ACT_Height : 20|4@1+ (1.0,0.0) [0.0|15.0] ""  CLU

BO_ 1024 CLU_CFG11: 2 CLU
	SG_ Vehicle_Type : 0|16@1+ (1.0,0.0) [0.0|65536.0] ""  _4WD

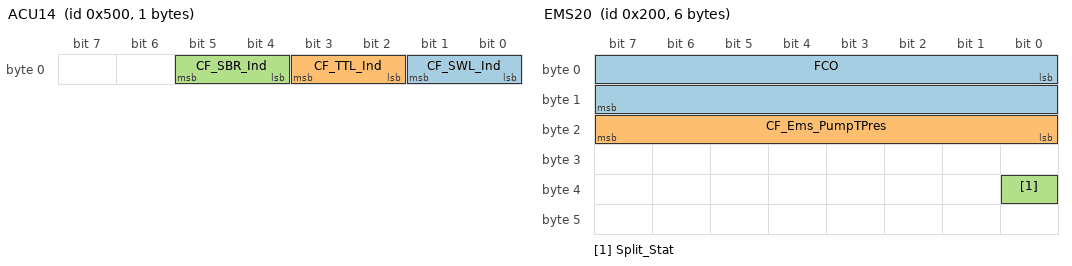
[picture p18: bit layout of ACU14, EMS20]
BO_ 1280 ACU14: 1 ACU
	SG_ CF_SWL_Ind : 0|2@1+ (1.0,0.0) [0.0|3.0] ""  CLU
	SG_ CF_TTL_Ind : 2|2@1+ (1.0,0.0) [0.0|3.0] ""  CLU
	SG_ CF_SBR_Ind : 4|2@1+ (1.0,0.0) [0.0|3.0] ""  BCM,CLU

BO_ 512 EMS20: 6 EMS
	SG_ FCO : 0|16@1+ (0.128,0.0) [0.0|8388.48] "ul"  CLU,CUBIS,FPCM,IBOX
	SG_ CF_Ems_PumpTPres : 16|8@1+ (3.137254902,0.0) [0.0|800.0] "kPa"  FPCM,IBOX
	SG_ Split_Stat : 32|1@1+ (1.0,0.0) [0.0|1.0] ""  FPCM

BO_TX_BU_ 1078 : BCM,CLU;
BO_TX_BU_ 1345 : BCM,CLU;
BO_TX_BU_ 1312 : BCM,CLU;
CM_ BO_ 1064 "[P] Periodic";
CM_ SG_ 1064 _4WD_TYPE "* FF = Front engine and Front wheel driving
* FR = Front engine and Rear wheel driving";
CM_ SG_ 1064 _4WD_ERR "This ¨è is for the ¡°4WD ECU, MAGNA & WIA JVÞä¡± system applied vehicles only.";
CM_ SG_ 1064 CLU_DUTY "Part time 4WD system does not support this information via CAN";
CM_ BO_ 1065 "[P] Periodic";
CM_ SG_ 1065 FRSS "This signal is not available in a part time 4WD system and 4WD system which use propeller shaft speed.";
CM_ SG_ 1065 FLSS "This signal is not available in a part time 4WD system and 4WD system which use propeller shaft speed.";
CM_ SG_ 1065 RRSS "This signal is not available in a part time 4WD system and 4WD system which use propeller shaft speed.";
CM_ SG_ 1065 RLSS "This signal is not available in a part time 4WD system and 4WD system which use propeller shaft speed.";
CM_ BO_ 1066 "[P] Periodic";
CM_ BO_ 16 "[E] On Event";
CM_ BO_ 1280 "[P] Periodic";
CM_ BO_ 1345 "[PE] Periodic and On Event";
CM_ SG_ 1345 CF_Gway_LightSwState "This signal is for ¡°IPM (Gateway)¡± applied vehicles only.";
CM_ SG_ 1345 CF_Gway_TSigRHSw "This signal is for ¡°IPM (Gateway)¡± applied vehicles only.";
CM_ SG_ 1345 CF_Gway_TSigLHSw "This signal is for ¡°IPM (Gateway)¡± applied vehicles only.";
CM_ SG_ 1345 CF_Gway_DriveTypeOption "This signal is for ¡°IPM (Gateway)¡± applied vehicles only.";
CM_ SG_ 1345 CF_Gway_StarterRlyState "This signal is for ¡°IPM (Gateway)¡± applied vehicles only.";
CM_ SG_ 1345 CF_Gway_PassiveAccessLock "This signal is for ¡°IPM (Gateway)¡± applied vehicles only.";
CM_ SG_ 1345 CF_Gway_PassiveAccessUnlock "This signal is for ¡°IPM (Gateway)¡± applied vehicles only.";
CM_ SG_ 1345 CF_Gway_HLpHighSw "This signal is for ¡°IPM (Gateway)¡± applied vehicles only.";
CM_ SG_ 1345 CF_Gway_InhibitRMT "This signal is for ¡°IPM (Gateway)¡± applied vehicles only.";
CM_ SG_ 1345 CF_Gway_Ign1 "Status of Ignition 1";
CM_ SG_ 1345 CF_Gway_Ign2 "Status of Ignition 2";
CM_ BO_ 1312 "[P] Periodic";
CM_ BO_ 1040 "[PE] Periodic and On Event";
CM_ SG_ 1040 CF_Gway_ATTurnRValue "This signal is for ¡°IPM (Gateway)¡± applied vehicles only.";
CM_ SG_ 1040 CF_Gway_EscortHLRValue "This signal is for ¡°IPM (Gateway)¡± applied vehicles only.";
CM_ SG_ 1040 CF_Gway_TTUnlockRValue "This signal is for ¡°IPM (Gateway)¡± applied vehicles only.";
CM_ SG_ 1040 CF_Gway_ADrLRValue "This signal is for ¡°IPM (Gateway)¡± applied vehicles only.";
CM_ SG_ 1040 CF_Gway_ADrURValue "This signal is for ¡°IPM (Gateway)¡± applied vehicles only.";
CM_ SG_ 1040 CF_Gway_SCMRValue "This signal is for ¡°IPM (Gateway)¡± applied vehicles only.";
CM_ SG_ 1040 CF_Gway_WlightRValue "This signal is for ¡°IPM (Gateway)¡± applied vehicles only.";
CM_ SG_ 1040 CF_Gway_PSMRValue "This signal is for ¡°IPM (Gateway)¡± applied vehicles only.";
CM_ SG_ 1040 CF_Gway_PasSpkrLvRValue "This signal is for ¡°IPM (Gateway)¡± applied vehicles only.";
CM_ BO_ 1313 "[PE] Periodic and On Event";
CM_ BO_ 1316 "[E] On Event";
CM_ BO_ 1317 "[E] On Event";
CM_ BO_ 1314 "[PE] Periodic and On Event";
CM_ BO_ 1315 "[PE] Periodic and On Event";
CM_ BO_ 1078 "[PE] Periodic and On Event";
CM_ SG_ 1078 CF_Gway_PASDisplayFLH "This signal is for ¡°IPM (Gateway)¡± applied vehicles only.";
CM_ SG_ 1078 CF_Gway_PASDisplayFRH "This signal is for ¡°IPM (Gateway)¡± applied vehicles only.";
CM_ SG_ 1078 CF_Gway_PASRsound "This signal is for ¡°IPM (Gateway)¡± applied vehicles only.";
CM_ SG_ 1078 CF_Gway_PASDisplayFCTR "This signal is for ¡°IPM (Gateway)¡± applied vehicles only.";
CM_ SG_ 1078 CF_Gway_PASDisplayRCTR "This signal is for ¡°IPM (Gateway)¡± applied vehicles only.";
CM_ SG_ 1078 CF_Gway_PASFsound "This signal is for ¡°IPM (Gateway)¡± applied vehicles only.";
CM_ SG_ 1078 CF_Gway_PASDisplayRLH "This signal is for ¡°IPM (Gateway)¡± applied vehicles only.";
CM_ SG_ 1078 CF_Gway_PASDisplayRRH "This signal is for ¡°IPM (Gateway)¡± applied vehicles only.";
CM_ SG_ 1078 CF_Gway_PASCheckSound "This signal is for ¡°IPM (Gateway)¡± applied vehicles only.";
CM_ BO_ 1292 "[P] Periodic";
CM_ SG_ 1292 CF_Clu_FlexSteerSW "This signal is for the FlexSteer system equipped vehicle only";
CM_ SG_ 1292 CF_Clu_ActiveEcoSW "This signal is for the Active ECO equipped vehicle only.";
CM_ SG_ 1292 CF_Clu_EcoDriveInf "This signal is for ¡°IPM (Gateway)¡± applied vehicles only.";
CM_ SG_ 1292 CF_Clu_AltLStatus "This signal is for ¡°IPM (Gateway)¡± applied vehicles only.";
CM_ SG_ 1292 CF_Clu_AliveCnt2 "This signal is for ¡°IPM (Gateway)¡± applied vehicles only.";
CM_ BO_ 1301 "[E] On Event";
CM_ SG_ 1301 CF_Clu_TrfChgSet "When this signal change, the message (CLU4) is sent 3 times.";
CM_ SG_ 1301 CF_Clu_SccNaviCamNValueSet "Request to set SCC system state";
CM_ SG_ 1301 CF_Clu_LkasModeNValueSet "Request to set LKAS control mode";
CM_ BO_ 1322 "[PE] Periodic and On Event";
CM_ SG_ 1322 CF_Clu_HudInfoSet "Request to set HUD display contents information";
CM_ SG_ 1322 CF_Clu_HudFontColorSet "Request to set HUD Color";
CM_ SG_ 1322 CF_Clu_HudBrightUpSW "Request to increase HUD Brightness";
CM_ SG_ 1322 CF_Clu_HudBrightDnSW "Request to decrease HUD Brightness";
CM_ SG_ 1322 CF_Clu_HudHeightUpSW "Request to increase HUD Height";
CM_ SG_ 1322 CF_Clu_HudHeightDnSW "Request to decrease HUD Height";
CM_ SG_ 1322 CF_Clu_HudSet "Request to set HUD display";
CM_ SG_ 1322 CF_Clu_HudFontSizeSet "Request to set HUD Font size";
CM_ SG_ 1322 CF_Clu_ClusterSound "Sound type of Cluster";
CM_ BO_ 1307 "[E] On Event";
CM_ SG_ 1307 CF_Clu_TirePressUnitNValueSet "Request to set Tire Pressure Unit";
CM_ SG_ 1307 CF_Clu_SlifNValueSet "Request to set SLIF status";
CM_ BO_ 1024 "[E] On Event";
CM_ BO_ 1318 "[E] On Event";
CM_ BO_ 1319 "[E] On Event";
CM_ BO_ 1338 "[E] On Event";
CM_ SG_ 1338 CF_Gway_TeleReqDrLock "-";
CM_ SG_ 1338 CF_Gway_TeleReqDrUnlock "-";
CM_ SG_ 1338 CF_Gway_TeleReqHazard "-";
CM_ SG_ 1338 CF_Gway_TeleReqHorn "-";
CM_ SG_ 1338 CF_Gway_TeleReqEngineOperate "-";
CM_ BO_ 68 "[PE] Periodic and On Event";
CM_ SG_ 68 CF_Datc_Type "This signal is for ¡°IPM (Gateway)¡± applied vehicles only.";
CM_ SG_ 68 CF_Datc_VerMaj "This signal is for ¡°IPM (Gateway)¡± applied vehicles only.";
CM_ SG_ 68 CF_Datc_VerMin "This signal is for ¡°IPM (Gateway)¡± applied vehicles only.";
CM_ SG_ 68 CR_Datc_OutTempC "This signal is for ¡°IPM (Gateway)¡± applied vehicles only.";
CM_ SG_ 68 CR_Datc_OutTempF "This signal is for ¡°IPM (Gateway)¡± applied vehicles only.";
CM_ BO_ 66 "[PE] Periodic and On Event";
CM_ SG_ 66 CR_Datc_DrTempDispC "This signal is for ¡°IPM (Gateway)¡± applied vehicles only.";
CM_ SG_ 66 CR_Datc_DrTempDispF "This signal is for ¡°IPM (Gateway)¡± applied vehicles only.";
CM_ SG_ 66 CR_Datc_PsTempDispC "This signal is for ¡°IPM (Gateway)¡± applied vehicles only.";
CM_ SG_ 66 CR_Datc_PsTempDispF "This signal is for ¡°IPM (Gateway)¡± applied vehicles only.";
CM_ BO_ 67 "[PE] Periodic and On Event";
CM_ SG_ 67 CF_Datc_TempDispUnit "This signal is for ¡°IPM (Gateway)¡± applied vehicles only.";
CM_ SG_ 67 CF_Datc_ModDisp "This signal is for ¡°IPM (Gateway)¡± applied vehicles only.";
CM_ SG_ 67 CF_Datc_IonClean "This signal is for ¡°IPM (Gateway)¡± applied vehicles only.";
CM_ SG_ 67 CF_Datc_ChgReqDisp "This signal is for ¡°IPM (Gateway)¡± applied vehicles only.";
CM_ SG_ 67 CF_Datc_IntakeDisp "This signal is for ¡°IPM (Gateway)¡± applied vehicles only.";
CM_ SG_ 67 CF_Datc_AutoDisp "This signal is for ¡°IPM (Gateway)¡± applied vehicles only.";
CM_ SG_ 67 CF_Datc_FrDefLed "This signal is for ¡°IPM (Gateway)¡± applied vehicles only.";
CM_ SG_ 67 CF_Datc_AutoDefogBlink "This signal is for ¡°IPM (Gateway)¡± applied vehicles only.";
CM_ SG_ 67 CF_Datc_ClmScanDisp "This signal is for ¡°IPM (Gateway)¡± applied vehicles only.";
CM_ SG_ 67 CF_Datc_AqsDisp "This signal is for ¡°IPM (Gateway)¡± applied vehicles only.";
CM_ SG_ 67 CF_Datc_AcDisp "This signal is for ¡°IPM (Gateway)¡± applied vehicles only.";
CM_ SG_ 67 CF_Datc_OpSts "This signal is for ¡°IPM (Gateway)¡± applied vehicles only.";
CM_ SG_ 67 CF_Mtc_MaxAcDisp "This signal is for ¡°IPM (Gateway)¡± applied vehicles only.";
CM_ SG_ 67 CF_Datc_DualDisp "This signal is for ¡°IPM (Gateway)¡± applied vehicles only.";
CM_ SG_ 67 CF_Datc_PwrInf "This signal is for ¡°IPM (Gateway)¡± applied vehicles only.";
CM_ SG_ 67 CF_Datc_RearManual "This signal is for ¡°IPM (Gateway)¡± applied vehicles only.";
CM_ SG_ 67 CF_Datc_RearBlwDisp "This signal is for ¡°IPM (Gateway)¡± applied vehicles only.";
CM_ SG_ 67 CF_Datc_FrontBlwDisp "This signal is for ¡°IPM (Gateway)¡± applied vehicles only.";
CM_ BO_ 64 "[PE] Periodic and On Event";
CM_ SG_ 64 CF_Datc_DiagMode "This signal is for ¡°IPM (Gateway)¡± applied vehicles only.";
CM_ SG_ 64 CR_Datc_SelfDiagCode "This signal is for ¡°IPM (Gateway)¡± applied vehicles only.";
CM_ BO_ 1350 "[P] Periodic";
CM_ BO_ 1281 "[P] Periodic";
CM_ SG_ 1281 REQ_level "Request level by ECS switch or automatic";
CM_ BO_ 1353 "[P] Periodic";
CM_ SG_ 1353 BAT_SNSR_I "This signal is Battery Current from battery sensor.";
CM_ SG_ 1353 BAT_SOC "This signal is Battery SOC from battery sensor.";
CM_ SG_ 1353 BAT_SNSR_V "This signal is Battery Voltage from battery sensor.";
CM_ SG_ 1353 BAT_SNSR_Temp "This signal is Battery electrolyte temperature from battery sensor.";
CM_ SG_ 1353 BAT_SNSR_State "This signal is Battery SOC is plausible or not.";
CM_ SG_ 1353 BAT_SOH "This signal is Battery SOH from battery sensor.";
CM_ SG_ 1353 BAT_SNSR_Invalid "This singnal is Battery Sensor Invalid flag.";
CM_ SG_ 1353 BAT_SOF "This signal is Battery SOF from battery sensor.";
CM_ SG_ 1353 BAT_SNSR_Error "This signal is Response error of Battery LIN sensor signal.";
CM_ BO_ 790 "[P] Periodic";
CM_ SG_ 790 SWI_IGK "In case of Delphi ECU, Output period tolerance(+1ms) will be applied to Engine Lamda3.";
CM_ SG_ 790 F_N_ENG "In case of Delphi ECU, Output period tolerance(+1ms) will be applied to Engine Lamda3.";
CM_ SG_ 790 ACK_TCS "In case of Delphi ECU, Output period tolerance(+1ms) will be applied to Engine Lamda3.";
CM_ SG_ 790 PUC_STAT "In case of Delphi ECU, Output period tolerance(+1ms) will be applied to Engine Lamda3.";
CM_ SG_ 790 TQ_COR_STAT "In case of Delphi ECU, Output period tolerance(+1ms) will be applied to Engine Lamda3.";
CM_ SG_ 790 RLY_AC "In case of Delphi ECU, Output period tolerance(+1ms) will be applied to Engine Lamda3.";
CM_ SG_ 790 F_SUB_TQI "In case of Delphi ECU, Output period tolerance(+1ms) will be applied to Engine Lamda3.";
CM_ SG_ 790 TQI_ACOR "In case of Delphi ECU, Output period tolerance(+1ms) will be applied to Engine Lamda3.";
CM_ SG_ 790 N "In case of Delphi ECU, Output period tolerance(+1ms) will be applied to Engine Lamda3.";
CM_ SG_ 790 TQI "In case of Delphi ECU, Output period tolerance(+1ms) will be applied to Engine Lamda3.";
CM_ SG_ 790 TQFR "In case of Delphi ECU, Output period tolerance(+1ms) will be applied to Engine Lamda3.";
CM_ SG_ 790 VS "In case of Delphi ECU, Output period tolerance(+1ms) will be applied to Engine Lamda3.";
CM_ SG_ 790 RATIO_TQI_BAS_MAX_STND "In case of Delphi ECU, Output period tolerance(+1ms) will be applied to Engine Lamda3.";
CM_ BO_ 809 "[P] Periodic";
CM_ SG_ 809 CONF_TCU "1. For the automatic variant coding at E.O.L : This signal value is valid 1.5sec later from initial IG-ON
2. In case of Delphi ECU, Output period tolerance(+1ms) will be applied to Engine Lamda3.";
CM_ SG_ 809 CAN_VERS "In case of Delphi ECU, Output period tolerance(+1ms) will be applied to Engine Lamda3.";
CM_ SG_ 809 TQ_STND "1. In case of an engine which maximum engine torque is higher than 520Nm, this factor value is 15.
2. In case of Delphi ECU, Output period tolerance(+1ms) will be applied to Engine Lamda3.";
CM_ SG_ 809 OBD_FRF_ACK "In case of Delphi ECU, Output period tolerance(+1ms) will be applied to Engine Lamda3.";
CM_ SG_ 809 MUL_CODE "In case of Delphi ECU, Output period tolerance(+1ms) will be applied to Engine Lamda3.";
CM_ SG_ 809 TEMP_ENG "In case of Delphi ECU, Output period tolerance(+1ms) will be applied to Engine Lamda3.";
CM_ SG_ 809 MAF_FAC_ALTI_MMV "In case of Delphi ECU, Output period tolerance(+1ms) will be applied to Engine Lamda3.";
CM_ SG_ 809 VB_OFF_ACT "1. This signal is only for the gasoline system.
2. In case of Delphi ECU, Output period tolerance(+1ms) will be applied to Engine Lamda3.";
CM_ SG_ 809 ACK_ES "In case of Delphi ECU, Output period tolerance(+1ms) will be applied to Engine Lamda3.";
CM_ SG_ 809 CONF_MIL_FMY "1. This value represents a calibrated constant from the ECU.
2. In case of Delphi ECU, Output period tolerance(+1ms) will be applied to Engine Lamda3.";
CM_ SG_ 809 OD_OFF_REQ "1. This signal is available in the auto cruise control system equiped vehicles only.
2. In case of Delphi ECU, Output period tolerance(+1ms) will be applied to Engine Lamda3.";
CM_ SG_ 809 ACC_ACT "1. There is signal relationship between ¡®ACC_ACT¡¯ and ¡®PV_AV_CAN¡¯. See ¡®PV_AV_CAN¡¯ signal description page.
2. In case of Delphi ECU, Output period tolerance(+1ms) will be applied to Engine Lamda3.";
CM_ SG_ 809 CLU_ACK "1. This signal is for the diesel engine and ISG system installed vehicles only.
2. In case of Delphi ECU, Output period tolerance(+1ms) will be applied to Engine Lamda3.";
CM_ SG_ 809 BRAKE_ACT "In case of Delphi ECU, Output period tolerance(+1ms) will be applied to Engine Lamda3.";
CM_ SG_ 809 ENG_CHR "1. For the automatic variant coding at E.O.L : This signal value is valid 1.5sec later from initial IG-ON
2. In case of Delphi ECU, Output period tolerance(+1ms) will be applied to Engine Lamda3.";
CM_ SG_ 809 GP_CTL "1. This signal is for the diesel engine system only.
2. In case of Delphi ECU, Output period tolerance(+1ms) will be applied to Engine Lamda3.";
CM_ SG_ 809 TPS "1. In diesel engine system, there is a signal relationship between TPS and PV_AV_CAN. For the details, please see PV_AV_CAN signal description page. 
2. In case of Delphi ECU, Output period tolerance(+1ms) will be applied to Engine Lamda3.";
CM_ SG_ 809 PV_AV_CAN "In case of Delphi ECU, Output period tolerance(+1ms) will be applied to Engine Lamda3.";
CM_ SG_ 809 ENG_VOL "In case of Delphi ECU, Output period tolerance(+1ms) will be applied to Engine Lamda3.";
CM_ BO_ 1349 "[P] Periodic";
CM_ SG_ 1349 IMMO_LAMP_STAT "In case of Delphi ECU, Output period tolerance(+1ms) will be applied to Engine Lamda3.";
CM_ SG_ 1349 L_MIL "In case of Delphi ECU, Output period tolerance(+1ms) will be applied to Engine Lamda3.";
CM_ SG_ 1349 IM_STAT "In case of Delphi ECU, Output period tolerance(+1ms) will be applied to Engine Lamda3.";
CM_ SG_ 1349 AMP_CAN "In case of Delphi ECU, Output period tolerance(+1ms) will be applied to Engine Lamda3.";
CM_ SG_ 1349 BAT_Alt_FR_Duty "This signal is Filtered electrical load PWM signal from Alternator.";
CM_ SG_ 1349 VB "In case of Delphi ECU, Output period tolerance(+1ms) will be applied to Engine Lamda3.";
CM_ BO_ 1351 "[P] Periodic";
CM_ SG_ 1351 ECGPOvrd "1. This signal is for the ¡°SCC(Smart Cruise Control)¡± system applied vehicles only
2. In case of Delphi ECU, Output period tolerance(+1ms) will be applied to Engine Lamda3.";
CM_ SG_ 1351 QECACC "1. This signal is for the ¡°SCC(Smart Cruise Control)¡± system applied vehicles only
2. In case of Delphi ECU, Output period tolerance(+1ms) will be applied to Engine Lamda3.";
CM_ SG_ 1351 ECFail "1. This signal is for the ¡°SCC(Smart Cruise Control)¡± system applied vehicles only
2. In case of Delphi ECU, Output period tolerance(+1ms) will be applied to Engine Lamda3.";
CM_ SG_ 1351 SwitchOffCondExt "1. This signal is for the ¡°SCC(Smart Cruise Control)¡± system applied vehicles only
2. In case of Delphi ECU, Output period tolerance(+1ms) will be applied to Engine Lamda3.";
CM_ SG_ 1351 BLECFail "1. These signals are for the ¡°SCC(Smart Cruise Control)¡± system applied vehicles only
2. In case of Delphi ECU, Output period tolerance(+1ms) will be applied to Engine Lamda3.";
CM_ SG_ 1351 FA_PV_CAN "1. This signal is for the ¡°SCC(Smart Cruise Control)¡± system applied vehicles only
2. In case of Delphi ECU, Output period tolerance(+1ms) will be applied to Engine Lamda3.";
CM_ SG_ 1351 IntAirTemp "1. This signal is for the ¡°SCC(Smart Cruise Control)¡± system applied vehicles only
2. In case of Delphi ECU, Output period tolerance(+1ms) will be applied to Engine Lamda3.";
CM_ SG_ 1351 STATE_DC_OBD "1. This signal is for the ¡°SCC(Smart Cruise Control)¡± system applied vehicles only
2. In case of Delphi ECU, Output period tolerance(+1ms) will be applied to Engine Lamda3.";
CM_ SG_ 1351 INH_DC_OBD "1. This signal is for the ¡°SCC(Smart Cruise Control)¡± system applied vehicles only
2. In case of Delphi ECU, Output period tolerance(+1ms) will be applied to Engine Lamda3.";
CM_ SG_ 1351 CTR_IG_CYC_OBD "1. This signal is for the ¡°SCC(Smart Cruise Control)¡± system applied vehicles only
2. In case of Delphi ECU, Output period tolerance(+1ms) will be applied to Engine Lamda3.";
CM_ SG_ 1351 CTR_CDN_OBD "1. This signal is for the ¡°SCC(Smart Cruise Control)¡± system applied vehicles only
2. In case of Delphi ECU, Output period tolerance(+1ms) will be applied to Engine Lamda3.";
CM_ BO_ 48 "[PE] Periodic and On Event";
CM_ SG_ 48 CF_Ems_DC1NumPerMSV "1. This signal is for the ¡°DI_BOX(Direction Injection interface BOX)¡± applied vehicles only.
2. This signal output period can be changed according to the engine RPM.";
CM_ SG_ 48 CF_Ems_DC2NumPerMSV "1. This signal is for the ¡°DI_BOX(Direction Injection interface BOX)¡± applied vehicles only.
2. This signal output period can be changed according to the engine RPM.";
CM_ SG_ 48 CR_Ems_DutyCyc1MSV "1. This signal is for the ¡°DI_BOX(Direction Injection interface BOX)¡± applied vehicles only.
2. This signal output period can be changed according to the engine RPM.";
CM_ SG_ 48 CR_Ems_DutyCyc2MSV "1. This signal is for the ¡°DI_BOX(Direction Injection interface BOX)¡± applied vehicles only.
2. This signal output period can be changed according to the engine RPM.";
CM_ SG_ 48 CR_Ems_DutyCyc3MSV "1. This signal is for the ¡°DI_BOX(Direction Injection interface BOX)¡± applied vehicles only.
2. This signal output period can be changed according to the engine RPM.";
CM_ BO_ 512 "[P] Periodic";
CM_ SG_ 512 FCO "In case of Delphi ECU, Output period tolerance(+1ms) will be applied to Engine Lamda3.";
CM_ SG_ 512 Split_Stat "In case of Delphi ECU, Output period tolerance(+1ms) will be applied to Engine Lamda3.";
CM_ BO_ 544 "[P] Periodic";
CM_ BO_ 339 "[P] Periodic";
CM_ BO_ 1287 "[P] Periodic";
CM_ SG_ 1287 AVH_CLU "This message is for ¡°EPB (Electric Parking Brake)¡± system applied vehicle only.";
CM_ SG_ 1287 AVH_I_LAMP "This message is for ¡°EPB (Electric Parking Brake)¡± system applied vehicle only.";
CM_ SG_ 1287 AVH_ALARM "This message is for ¡°EPB (Electric Parking Brake)¡± system applied vehicle only.";
CM_ SG_ 1287 AVH_LAMP "This message is for ¡°EPB (Electric Parking Brake)¡± system applied vehicle only.";
CM_ BO_ 1360 "[P] Periodic";
CM_ BO_ 832 "[P] Periodic";
CM_ SG_ 832 CF_Lkas_FcwOpt_USM "This message is for LDWS/LKAS/FCW/HBA system.";
CM_ SG_ 832 CF_Lkas_LdwsOpt_USM "This message is for LDWS/LKAS system";
CM_ BO_ 1342 "[P] Periodic";
CM_ BO_ 593 "[P] Periodic";
CM_ SG_ 593 CR_Mdps_StrTq "PH > 0 : Left Direction (CCW)
PH < 0 : Right Direction (CW)";
CM_ BO_ 1056 "[P] Periodic";
CM_ SG_ 1056 VSetDis "This signal can be sent in km/h or MPH according to the ¡°SPEED_UNIT¡± signal (See CLU1 message).";
CM_ BO_ 1057 "[P] Periodic";
CM_ BO_ 1290 "[PE] Periodic and On Event";
CM_ SG_ 1290 SCCDrvModeRValue "-";
CM_ BO_ 1362 "[P] Periodic";
CM_ BO_ 273 "[P] Periodic";
CM_ BO_ 274 "[P] Periodic";
CM_ SG_ 274 ETL_TCU "In case of an engine which maximum engine torque is higher than 520Nm, this factor value is 3, Initial value is 765, and max is 762";
CM_ SG_ 274 IDLE_UP_TCU "THIS SIGNAL IS FOR ¡°LAMBDA ENGINE¡± SYSTEM ONLY.";
CM_ BO_ 275 "[P] Periodic";
CM_ BO_ 1282 "[P] Periodic";
CM_ SG_ 1282 CF_Tcu_StRelStat "This message is for the ¡°DCT(Double Clutch T/M)¡± system applied vehicles only
If CAN communication is not available(eg. CAN error etc), all receivers should acknowledge Start release
NOT ready.";
CM_ SG_ 1282 CF_Tcu_DriWarn1 "This message is for the ¡°DCT(Double Clutch T/M)¡± system applied vehicles only";
CM_ SG_ 1282 CF_Tcu_DriWarn2 "This message is for the ¡°DCT(Double Clutch T/M)¡± system applied vehicles only";
CM_ BO_ 1356 "[P] Periodic";
BA_DEF_ SG_ "GenSigEnvVarType" ENUM "Int","Float","Undef" ;
BA_DEF_ SG_ "GenSigEVName" STRING ;
BA_DEF_ SG_ "GenSigInactiveValue" INT 0 65535 ;
BA_DEF_ SG_ "GenSigSendType" ENUM "Cyclic","OnWrite","OnWriteWithRepetition","OnChange","OnChangeWithRepetition","IfActive","IfActiveWithRepetition","NoSigSendType" ;
BA_DEF_ SG_ "GenSigStartValue" INT 0 1215752192 ;
BA_DEF_ SG_ "GwSigLatencyTime" INT 0 65535 ;
BA_DEF_ SG_ "GwSigMissingSourceType" ENUM "Undef","OldValue","DefaultValue","InitialValue" ;
BA_DEF_ SG_ "SignalCategory" HEX 10 15 ;
BA_DEF_ BO_ "GenMsgCycleTime" INT 0 2000 ;
BA_DEF_ BO_ "GenMsgCycleTimeFast" INT 0 500 ;
BA_DEF_ BO_ "GenMsgDelayTime" INT 0 20 ;
BA_DEF_ BO_ "GenMsgILSupport" ENUM "No","Yes" ;
BA_DEF_ BO_ "GenMsgNrOfRepetition" INT 0 3 ;
BA_DEF_ BO_ "GenMsgSendType" ENUM "Cyclic","not_used","not_used","not_used","not_used","not_used","not_used","not_used","NoMsgSendType" ;
BA_DEF_ BO_ "GenMsgStartDelayTime" INT 0 2000 ;
BA_DEF_REL_ BU_SG_REL_ "GenSigTimeoutTime" INT 0 7000 ;
BA_DEF_DEF_ "GenSigEnvVarType" "Undef" ;
BA_DEF_DEF_ "GenSigEVName" "@Signame" ;
BA_DEF_DEF_ "GenSigInactiveValue" 0 ;
BA_DEF_DEF_ "GenSigSendType" "NoSigSendType" ;
BA_DEF_DEF_ "GenSigStartValue" 0 ;
BA_DEF_DEF_ "GwSigLatencyTime" 40 ;
BA_DEF_DEF_ "GwSigMissingSourceType" "Undef" ;
BA_DEF_DEF_ "SignalCategory" 12 ;
BA_DEF_DEF_ "GenMsgCycleTime" 10 ;
BA_DEF_DEF_ "GenMsgCycleTimeFast" 40 ;
BA_DEF_DEF_ "GenMsgDelayTime" 20 ;
BA_DEF_DEF_ "GenMsgILSupport" "Yes" ;
BA_DEF_DEF_ "GenMsgNrOfRepetition" 0 ;
BA_DEF_DEF_ "GenMsgSendType" "Cyclic" ;
BA_DEF_DEF_ "GenMsgStartDelayTime" 0 ;
BA_DEF_DEF_REL_ "GenSigTimeoutTime" 500 ;
BA_ "GenMsgCycleTime" BO_ 1064 20;
BA_ "GenMsgCycleTime" BO_ 1065 20;
BA_ "GenSigStartValue" SG_ 1065 Ster_Pos 600;
BA_ "GenSigStartValue" SG_ 1065 CLU_PRES 800;
BA_ "GenMsgCycleTime" BO_ 1066 20;
BA_ "GenMsgSendType" BO_ 16 8;
BA_ "GenMsgCycleTime" BO_ 16 0;
BA_ "GenMsgNrOfRepetition" BO_ 16 3;
BA_REL_ "GenSigTimeoutTime" BU_SG_REL_ CUBIS SG_ 16 CF_Acu_CshAct 0;
BA_REL_ "GenSigTimeoutTime" BU_SG_REL_ IBOX SG_ 16 CF_Acu_CshAct 0;
BA_REL_ "GenSigTimeoutTime" BU_SG_REL_ ODS SG_ 16 CF_Acu_CshAct 0;
BA_ "GenSigSendType" SG_ 16 CF_Acu_CshAct 4;
BA_ "GenMsgCycleTime" BO_ 1280 100;
BA_REL_ "GenSigTimeoutTime" BU_SG_REL_ CLU SG_ 1280 CF_SWL_Ind 1000;
BA_REL_ "GenSigTimeoutTime" BU_SG_REL_ CLU SG_ 1280 CF_TTL_Ind 1000;
BA_REL_ "GenSigTimeoutTime" BU_SG_REL_ BCM SG_ 1280 CF_SBR_Ind 1000;
BA_REL_ "GenSigTimeoutTime" BU_SG_REL_ CLU SG_ 1280 CF_SBR_Ind 1000;
BA_ "GenMsgCycleTime" BO_ 1345 100;
BA_ "GenMsgNrOfRepetition" BO_ 1345 3;
BA_ "GenSigSendType" SG_ 1345 CF_Gway_IGNSw 4;
BA_ "GenSigSendType" SG_ 1345 CF_Gway_RKECmd 4;
BA_ "GenSigSendType" SG_ 1345 CF_Gway_DrvKeyLockSw 4;
BA_ "GenSigSendType" SG_ 1345 CF_Gway_DrvKeyUnlockSw 4;
BA_ "GenSigSendType" SG_ 1345 CF_Gway_DrvDrSw 4;
BA_ "GenSigSendType" SG_ 1345 CF_Gway_DrvSeatBeltSw 4;
BA_ "GenSigSendType" SG_ 1345 CF_Gway_TrunkTgSw 4;
BA_ "GenSigSendType" SG_ 1345 CF_Gway_AstSeatBeltSw 4;
BA_ "GenSigSendType" SG_ 1345 CF_Gway_SMKOption 4;
BA_ "GenSigSendType" SG_ 1345 CF_Gway_HoodSw 4;
BA_ "GenSigSendType" SG_ 1345 CF_Gway_TurnSigLh 4;
BA_ "GenSigSendType" SG_ 1345 CF_Gway_WiperIntT 4;
BA_ "GenSigSendType" SG_ 1345 CF_Gway_WiperIntSw 4;
BA_ "GenSigSendType" SG_ 1345 CF_Gway_WiperLowSw 4;
BA_ "GenSigSendType" SG_ 1345 CF_Gway_WiperHighSw 4;
BA_ "GenSigSendType" SG_ 1345 CF_Gway_WiperAutoSw 4;
BA_ "GenSigSendType" SG_ 1345 CF_Gway_RainSnsState 4;
BA_ "GenSigSendType" SG_ 1345 CF_Gway_HeadLampLow 4;
BA_ "GenSigSendType" SG_ 1345 CF_Gway_HeadLampHigh 4;
BA_ "GenSigSendType" SG_ 1345 CF_Gway_HazardSw 4;
BA_ "GenSigSendType" SG_ 1345 CF_Gway_AstDrSw 4;
BA_ "GenSigSendType" SG_ 1345 CF_Gway_DefoggerRly 4;
BA_ "GenSigSendType" SG_ 1345 CF_Gway_ALightStat 4;
BA_REL_ "GenSigTimeoutTime" BU_SG_REL_ AFLS SG_ 1345 CF_Gway_LightSwState 1000;
BA_REL_ "GenSigTimeoutTime" BU_SG_REL_ IBOX SG_ 1345 CF_Gway_LightSwState 1000;
BA_REL_ "GenSigTimeoutTime" BU_SG_REL_ LDWS_LKAS SG_ 1345 CF_Gway_LightSwState 1000;
BA_ "GenSigSendType" SG_ 1345 CF_Gway_LightSwState 4;
BA_ "GenSigSendType" SG_ 1345 CF_Gway_Frt_Fog_Act 4;
BA_REL_ "GenSigTimeoutTime" BU_SG_REL_ IBOX SG_ 1345 CF_Gway_TSigRHSw 1000;
BA_REL_ "GenSigTimeoutTime" BU_SG_REL_ LDWS_LKAS SG_ 1345 CF_Gway_TSigRHSw 1000;
BA_ "GenSigSendType" SG_ 1345 CF_Gway_TSigRHSw 4;
BA_REL_ "GenSigTimeoutTime" BU_SG_REL_ IBOX SG_ 1345 CF_Gway_TSigLHSw 1000;
BA_REL_ "GenSigTimeoutTime" BU_SG_REL_ LDWS_LKAS SG_ 1345 CF_Gway_TSigLHSw 1000;
BA_ "GenSigSendType" SG_ 1345 CF_Gway_TSigLHSw 4;
BA_ "GenSigSendType" SG_ 1345 CF_Gway_DriveTypeOption 4;
BA_REL_ "GenSigTimeoutTime" BU_SG_REL_ EMS SG_ 1345 CF_Gway_StarterRlyState 1000;
BA_REL_ "GenSigTimeoutTime" BU_SG_REL_ IBOX SG_ 1345 CF_Gway_StarterRlyState 1000;
BA_ "GenSigSendType" SG_ 1345 CF_Gway_StarterRlyState 4;
BA_REL_ "GenSigTimeoutTime" BU_SG_REL_ CLU SG_ 1345 CF_Gway_PassiveAccessLock 1000;
BA_REL_ "GenSigTimeoutTime" BU_SG_REL_ ECS SG_ 1345 CF_Gway_PassiveAccessLock 1000;
BA_REL_ "GenSigTimeoutTime" BU_SG_REL_ EMS SG_ 1345 CF_Gway_PassiveAccessLock 1000;
BA_REL_ "GenSigTimeoutTime" BU_SG_REL_ IBOX SG_ 1345 CF_Gway_PassiveAccessLock 1000;
BA_ "GenSigSendType" SG_ 1345 CF_Gway_PassiveAccessLock 4;
BA_ "GenSigSendType" SG_ 1345 CF_Gway_WiperMistSw 4;
BA_REL_ "GenSigTimeoutTime" BU_SG_REL_ CLU SG_ 1345 CF_Gway_PassiveAccessUnlock 1000;
BA_REL_ "GenSigTimeoutTime" BU_SG_REL_ ECS SG_ 1345 CF_Gway_PassiveAccessUnlock 1000;
BA_REL_ "GenSigTimeoutTime" BU_SG_REL_ EMS SG_ 1345 CF_Gway_PassiveAccessUnlock 1000;
BA_REL_ "GenSigTimeoutTime" BU_SG_REL_ IBOX SG_ 1345 CF_Gway_PassiveAccessUnlock 1000;
BA_ "GenSigSendType" SG_ 1345 CF_Gway_PassiveAccessUnlock 4;
BA_REL_ "GenSigTimeoutTime" BU_SG_REL_ CLU SG_ 1345 CF_Gway_RrSunRoofOpenState 1000;
BA_REL_ "GenSigTimeoutTime" BU_SG_REL_ DATC SG_ 1345 CF_Gway_RrSunRoofOpenState 1000;
BA_REL_ "GenSigTimeoutTime" BU_SG_REL_ IBOX SG_ 1345 CF_Gway_RrSunRoofOpenState 1000;
BA_ "GenSigSendType" SG_ 1345 CF_Gway_RrSunRoofOpenState 4;
BA_ "GenSigSendType" SG_ 1345 CF_Gway_PassingSW 4;
BA_ "GenSigSendType" SG_ 1345 CF_Gway_HBAControlMode 4;
BA_ "GenSigSendType" SG_ 1345 CF_Gway_HLpHighSw 4;
BA_ "GenSigSendType" SG_ 1345 CF_Gway_InhibitRMT 4;
BA_ "GenSigSendType" SG_ 1345 CF_Gway_RainSnsOption 4;
BA_REL_ "GenSigTimeoutTime" BU_SG_REL_ CLU SG_ 1345 C_SunRoofOpenState 1000;
BA_REL_ "GenSigTimeoutTime" BU_SG_REL_ DATC SG_ 1345 C_SunRoofOpenState 1000;
BA_REL_ "GenSigTimeoutTime" BU_SG_REL_ IBOX SG_ 1345 C_SunRoofOpenState 1000;
BA_ "GenSigSendType" SG_ 1345 C_SunRoofOpenState 4;
BA_REL_ "GenSigTimeoutTime" BU_SG_REL_ CLU SG_ 1345 CF_Gway_Ign1 1000;
BA_ "GenSigSendType" SG_ 1345 CF_Gway_Ign1 4;
BA_REL_ "GenSigTimeoutTime" BU_SG_REL_ CLU SG_ 1345 CF_Gway_Ign2 1000;
BA_ "GenSigSendType" SG_ 1345 CF_Gway_Ign2 4;
BA_ "GenSigSendType" SG_ 1345 CF_Gway_ParkBrakeSw 4;
BA_ "GenSigSendType" SG_ 1345 CF_Gway_TurnSigRh 4;
BA_ "GenMsgCycleTime" BO_ 1312 100;
BA_REL_ "GenSigTimeoutTime" BU_SG_REL_ EMS SG_ 1312 CF_Hoodsw_memory 0;
BA_REL_ "GenSigTimeoutTime" BU_SG_REL_ AAF SG_ 1312 C_MirOutTempSns 1000;
BA_REL_ "GenSigTimeoutTime" BU_SG_REL_ CLU SG_ 1312 C_MirOutTempSns 1000;
BA_REL_ "GenSigTimeoutTime" BU_SG_REL_ DATC SG_ 1312 C_MirOutTempSns 1000;
BA_REL_ "GenSigTimeoutTime" BU_SG_REL_ EMS SG_ 1312 C_MirOutTempSns 1000;
BA_REL_ "GenSigTimeoutTime" BU_SG_REL_ SPAS SG_ 1312 C_MirOutTempSns 1000;
BA_ "GenMsgCycleTime" BO_ 1040 200;
BA_ "GenMsgNrOfRepetition" BO_ 1040 3;
BA_ "GenSigSendType" SG_ 1040 CF_Gway_ATTurnRValue 4;
BA_ "GenSigSendType" SG_ 1040 CF_Gway_PTGMRValue 4;
BA_ "GenSigSendType" SG_ 1040 CF_Gway_EscortHLRValue 4;
BA_ "GenSigSendType" SG_ 1040 CF_Gway_TTUnlockRValue 4;
BA_ "GenSigSendType" SG_ 1040 CF_Gway_ADrLRValue 4;
BA_ "GenSigSendType" SG_ 1040 CF_Gway_ADrURValue 4;
BA_ "GenSigSendType" SG_ 1040 CF_Gway_SCMRValue 4;
BA_ "GenSigSendType" SG_ 1040 CF_Gway_WlightRValue 4;
BA_ "GenSigSendType" SG_ 1040 CF_Gway_PSMRValue 4;
BA_ "GenSigSendType" SG_ 1040 CF_Gway_OTTurnRValue 4;
BA_ "GenSigSendType" SG_ 1040 CF_Gway_DrLockSoundRValue 4;
BA_ "GenSigSendType" SG_ 1040 CF_Gway_HAnBRValue 4;
BA_ "GenSigSendType" SG_ 1040 CF_Gway_MoodLpRValue 4;
BA_ "GenSigSendType" SG_ 1040 CF_Gway_HfreeTrunkRValue 4;
BA_ "GenSigSendType" SG_ 1040 CF_Gway_AutoLightRValue 4;
BA_ "GenSigStartValue" SG_ 1040 CF_Gway_AutoLightRValue 2;
BA_ "GenSigSendType" SG_ 1040 CF_Gway_RearWiperRValue 4;
BA_ "GenSigSendType" SG_ 1040 CF_Gway_PasSpkrLvRValue 4;
BA_ "GenMsgCycleTime" BO_ 1313 200;
BA_ "GenMsgNrOfRepetition" BO_ 1313 3;
BA_REL_ "GenSigTimeoutTime" BU_SG_REL_ CLU SG_ 1313 C_DRVDoorStatus 700;
BA_ "GenSigSendType" SG_ 1313 C_DRVDoorStatus 4;
BA_ "GenSigStartValue" SG_ 1313 C_DRVDoorStatus 3;
BA_REL_ "GenSigTimeoutTime" BU_SG_REL_ CLU SG_ 1313 C_ASTDoorStatus 700;
BA_ "GenSigSendType" SG_ 1313 C_ASTDoorStatus 4;
BA_ "GenSigStartValue" SG_ 1313 C_ASTDoorStatus 3;
BA_REL_ "GenSigTimeoutTime" BU_SG_REL_ CLU SG_ 1313 C_RLDoorStatus 700;
BA_ "GenSigSendType" SG_ 1313 C_RLDoorStatus 4;
BA_ "GenSigStartValue" SG_ 1313 C_RLDoorStatus 3;
BA_REL_ "GenSigTimeoutTime" BU_SG_REL_ CLU SG_ 1313 C_RRDoorStatus 700;
BA_ "GenSigSendType" SG_ 1313 C_RRDoorStatus 4;
BA_ "GenSigStartValue" SG_ 1313 C_RRDoorStatus 3;
BA_REL_ "GenSigTimeoutTime" BU_SG_REL_ CLU SG_ 1313 C_TrunkStatus 700;
BA_ "GenSigSendType" SG_ 1313 C_TrunkStatus 4;
BA_ "GenSigStartValue" SG_ 1313 C_TrunkStatus 3;
BA_REL_ "GenSigTimeoutTime" BU_SG_REL_ CLU SG_ 1313 C_OSMirrorStatus 700;
BA_ "GenSigSendType" SG_ 1313 C_OSMirrorStatus 4;
BA_ "GenSigStartValue" SG_ 1313 C_OSMirrorStatus 3;
BA_ "GenMsgSendType" BO_ 1316 8;
BA_ "GenMsgCycleTime" BO_ 1316 0;
BA_ "GenMsgNrOfRepetition" BO_ 1316 3;
BA_REL_ "GenSigTimeoutTime" BU_SG_REL_ CLU SG_ 1316 C_ADrLUNValueConf 0;
BA_ "GenSigSendType" SG_ 1316 C_ADrLUNValueConf 4;
BA_ "GenSigStartValue" SG_ 1316 C_ADrLUNValueConf 3;
BA_REL_ "GenSigTimeoutTime" BU_SG_REL_ CLU SG_ 1316 C_TwUnNValueConf 0;
BA_ "GenSigSendType" SG_ 1316 C_TwUnNValueConf 4;
BA_ "GenSigStartValue" SG_ 1316 C_TwUnNValueConf 3;
BA_REL_ "GenSigTimeoutTime" BU_SG_REL_ CLU SG_ 1316 C_AlarmNValueConf 0;
BA_ "GenSigSendType" SG_ 1316 C_AlarmNValueConf 4;
BA_ "GenSigStartValue" SG_ 1316 C_AlarmNValueConf 3;
BA_REL_ "GenSigTimeoutTime" BU_SG_REL_ CLU SG_ 1316 C_PSMNValueConf 0;
BA_ "GenSigSendType" SG_ 1316 C_PSMNValueConf 4;
BA_ "GenSigStartValue" SG_ 1316 C_PSMNValueConf 3;
BA_REL_ "GenSigTimeoutTime" BU_SG_REL_ CLU SG_ 1316 C_SCMNValueConf 0;
BA_ "GenSigSendType" SG_ 1316 C_SCMNValueConf 4;
BA_ "GenSigStartValue" SG_ 1316 C_SCMNValueConf 3;
BA_REL_ "GenSigTimeoutTime" BU_SG_REL_ CLU SG_ 1316 C_HLEscortNValueConf 0;
BA_ "GenSigSendType" SG_ 1316 C_HLEscortNValueConf 4;
BA_ "GenSigStartValue" SG_ 1316 C_HLEscortNValueConf 3;
BA_REL_ "GenSigTimeoutTime" BU_SG_REL_ CLU SG_ 1316 C_WELNValueConf 0;
BA_ "GenSigSendType" SG_ 1316 C_WELNValueConf 4;
BA_ "GenSigStartValue" SG_ 1316 C_WELNValueConf 3;
BA_REL_ "GenSigTimeoutTime" BU_SG_REL_ CLU SG_ 1316 C_TriTurnLNValueConf 0;
BA_ "GenSigSendType" SG_ 1316 C_TriTurnLNValueConf 4;
BA_ "GenSigStartValue" SG_ 1316 C_TriTurnLNValueConf 3;
BA_ "GenMsgSendType" BO_ 1317 8;
BA_ "GenMsgCycleTime" BO_ 1317 0;
BA_ "GenMsgNrOfRepetition" BO_ 1317 3;
BA_REL_ "GenSigTimeoutTime" BU_SG_REL_ CLU SG_ 1317 C_ADrLRValue 0;
BA_ "GenSigSendType" SG_ 1317 C_ADrLRValue 4;
BA_ "GenSigStartValue" SG_ 1317 C_ADrLRValue 7;
BA_REL_ "GenSigTimeoutTime" BU_SG_REL_ CLU SG_ 1317 C_ADrURValue 0;
BA_ "GenSigSendType" SG_ 1317 C_ADrURValue 4;
BA_ "GenSigStartValue" SG_ 1317 C_ADrURValue 7;
BA_REL_ "GenSigTimeoutTime" BU_SG_REL_ CLU SG_ 1317 C_TwUnRValue 0;
BA_ "GenSigSendType" SG_ 1317 C_TwUnRValue 4;
BA_ "GenSigStartValue" SG_ 1317 C_TwUnRValue 3;
BA_REL_ "GenSigTimeoutTime" BU_SG_REL_ CLU SG_ 1317 C_ABuzzerRValue 0;
BA_ "GenSigSendType" SG_ 1317 C_ABuzzerRValue 4;
BA_ "GenSigStartValue" SG_ 1317 C_ABuzzerRValue 3;
BA_REL_ "GenSigTimeoutTime" BU_SG_REL_ CLU SG_ 1317 C_ArmWKeyRValue 0;
BA_ "GenSigSendType" SG_ 1317 C_ArmWKeyRValue 4;
BA_ "GenSigStartValue" SG_ 1317 C_ArmWKeyRValue 3;
BA_REL_ "GenSigTimeoutTime" BU_SG_REL_ CLU SG_ 1317 C_PSMRValue 0;
BA_ "GenSigSendType" SG_ 1317 C_PSMRValue 4;
BA_ "GenSigStartValue" SG_ 1317 C_PSMRValue 3;
BA_REL_ "GenSigTimeoutTime" BU_SG_REL_ CLU SG_ 1317 C_SCMRValue 0;
BA_ "GenSigSendType" SG_ 1317 C_SCMRValue 4;
BA_ "GenSigStartValue" SG_ 1317 C_SCMRValue 3;
BA_REL_ "GenSigTimeoutTime" BU_SG_REL_ CLU SG_ 1317 C_HLEscortRValue 0;
BA_ "GenSigSendType" SG_ 1317 C_HLEscortRValue 4;
BA_ "GenSigStartValue" SG_ 1317 C_HLEscortRValue 3;
BA_REL_ "GenSigTimeoutTime" BU_SG_REL_ CLU SG_ 1317 C_WELRValue 0;
BA_ "GenSigSendType" SG_ 1317 C_WELRValue 4;
BA_ "GenSigStartValue" SG_ 1317 C_WELRValue 3;
BA_REL_ "GenSigTimeoutTime" BU_SG_REL_ CLU SG_ 1317 C_TriTurnLRValue 0;
BA_ "GenSigSendType" SG_ 1317 C_TriTurnLRValue 4;
BA_ "GenSigStartValue" SG_ 1317 C_TriTurnLRValue 3;
BA_ "GenMsgCycleTime" BO_ 1314 200;
BA_ "GenMsgNrOfRepetition" BO_ 1314 3;
BA_REL_ "GenSigTimeoutTime" BU_SG_REL_ CLU SG_ 1314 C_AV_Tail 700;
BA_ "GenSigSendType" SG_ 1314 C_AV_Tail 4;
BA_ "GenSigStartValue" SG_ 1314 C_AV_Tail 3;
BA_REL_ "GenSigTimeoutTime" BU_SG_REL_ CLU SG_ 1314 C_ParkingBrakeSW 700;
BA_ "GenSigSendType" SG_ 1314 C_ParkingBrakeSW 4;
BA_ "GenSigStartValue" SG_ 1314 C_ParkingBrakeSW 3;
BA_REL_ "GenSigTimeoutTime" BU_SG_REL_ CLU SG_ 1314 C_RKECMD 700;
BA_ "GenSigSendType" SG_ 1314 C_RKECMD 4;
BA_ "GenSigStartValue" SG_ 1314 C_RKECMD 15;
BA_REL_ "GenSigTimeoutTime" BU_SG_REL_ CLU SG_ 1314 C_BAState 700;
BA_ "GenSigSendType" SG_ 1314 C_BAState 4;
BA_ "GenSigStartValue" SG_ 1314 C_BAState 3;
BA_REL_ "GenSigTimeoutTime" BU_SG_REL_ CLU SG_ 1314 C_IGNSW 700;
BA_ "GenSigSendType" SG_ 1314 C_IGNSW 4;
BA_ "GenSigStartValue" SG_ 1314 C_IGNSW 7;
BA_REL_ "GenSigTimeoutTime" BU_SG_REL_ CLU SG_ 1314 C_CountryCfg 700;
BA_ "GenSigSendType" SG_ 1314 C_CountryCfg 4;
BA_ "GenSigStartValue" SG_ 1314 C_CountryCfg 7;
BA_REL_ "GenSigTimeoutTime" BU_SG_REL_ CLU SG_ 1314 C_TailLampActivity 700;
BA_ "GenSigSendType" SG_ 1314 C_TailLampActivity 4;
BA_ "GenSigStartValue" SG_ 1314 C_TailLampActivity 3;
BA_REL_ "GenSigTimeoutTime" BU_SG_REL_ CLU SG_ 1314 RearSW_RSELockOnOff 700;
BA_ "GenSigSendType" SG_ 1314 RearSW_RSELockOnOff 4;
BA_ "GenSigStartValue" SG_ 1314 RearSW_RSELockOnOff 3;
BA_REL_ "GenSigTimeoutTime" BU_SG_REL_ CLU SG_ 1314 C_SMKTeleCrankingState 700;
BA_ "GenSigSendType" SG_ 1314 C_SMKTeleCrankingState 4;
BA_ "GenSigStartValue" SG_ 1314 C_SMKTeleCrankingState 3;
BA_REL_ "GenSigTimeoutTime" BU_SG_REL_ CLU SG_ 1314 C_SMKTeleCrankingFailRes 700;
BA_ "GenSigSendType" SG_ 1314 C_SMKTeleCrankingFailRes 4;
BA_ "GenSigStartValue" SG_ 1314 C_SMKTeleCrankingFailRes 3;
BA_ "GenMsgCycleTime" BO_ 1315 200;
BA_ "GenMsgNrOfRepetition" BO_ 1315 3;
BA_REL_ "GenSigTimeoutTime" BU_SG_REL_ CLU SG_ 1315 C_ModeSW 700;
BA_ "GenSigSendType" SG_ 1315 C_ModeSW 4;
BA_ "GenSigStartValue" SG_ 1315 C_ModeSW 3;
BA_REL_ "GenSigTimeoutTime" BU_SG_REL_ CLU SG_ 1315 C_MuteSW 700;
BA_ "GenSigSendType" SG_ 1315 C_MuteSW 4;
BA_ "GenSigStartValue" SG_ 1315 C_MuteSW 3;
BA_REL_ "GenSigTimeoutTime" BU_SG_REL_ CLU SG_ 1315 C_SeekDnSW 700;
BA_ "GenSigSendType" SG_ 1315 C_SeekDnSW 4;
BA_ "GenSigStartValue" SG_ 1315 C_SeekDnSW 3;
BA_REL_ "GenSigTimeoutTime" BU_SG_REL_ CLU SG_ 1315 C_SeekUpSW 700;
BA_ "GenSigSendType" SG_ 1315 C_SeekUpSW 4;
BA_ "GenSigStartValue" SG_ 1315 C_SeekUpSW 3;
BA_REL_ "GenSigTimeoutTime" BU_SG_REL_ CLU SG_ 1315 C_BTPhoneCallSW 700;
BA_ "GenSigSendType" SG_ 1315 C_BTPhoneCallSW 4;
BA_ "GenSigStartValue" SG_ 1315 C_BTPhoneCallSW 3;
BA_REL_ "GenSigTimeoutTime" BU_SG_REL_ CLU SG_ 1315 C_BTPhoneHangUpSW 700;
BA_ "GenSigSendType" SG_ 1315 C_BTPhoneHangUpSW 4;
BA_ "GenSigStartValue" SG_ 1315 C_BTPhoneHangUpSW 3;
BA_REL_ "GenSigTimeoutTime" BU_SG_REL_ CLU SG_ 1315 C_DISCDownSW 700;
BA_ "GenSigSendType" SG_ 1315 C_DISCDownSW 4;
BA_ "GenSigStartValue" SG_ 1315 C_DISCDownSW 3;
BA_REL_ "GenSigTimeoutTime" BU_SG_REL_ CLU SG_ 1315 C_DISCUpSW 700;
BA_ "GenSigSendType" SG_ 1315 C_DISCUpSW 4;
BA_ "GenSigStartValue" SG_ 1315 C_DISCUpSW 3;
BA_REL_ "GenSigTimeoutTime" BU_SG_REL_ CLU SG_ 1315 C_SdsSW 700;
BA_ "GenSigSendType" SG_ 1315 C_SdsSW 4;
BA_ "GenSigStartValue" SG_ 1315 C_SdsSW 3;
BA_REL_ "GenSigTimeoutTime" BU_SG_REL_ CLU SG_ 1315 C_MTSSW 700;
BA_ "GenSigSendType" SG_ 1315 C_MTSSW 4;
BA_ "GenSigStartValue" SG_ 1315 C_MTSSW 3;
BA_REL_ "GenSigTimeoutTime" BU_SG_REL_ CLU SG_ 1315 C_VolDnSW 700;
BA_ "GenSigSendType" SG_ 1315 C_VolDnSW 4;
BA_ "GenSigStartValue" SG_ 1315 C_VolDnSW 3;
BA_REL_ "GenSigTimeoutTime" BU_SG_REL_ CLU SG_ 1315 C_VolUpSW 700;
BA_ "GenSigSendType" SG_ 1315 C_VolUpSW 4;
BA_ "GenSigStartValue" SG_ 1315 C_VolUpSW 3;
BA_ "GenMsgCycleTime" BO_ 1078 50;
BA_ "GenMsgNrOfRepetition" BO_ 1078 3;
BA_REL_ "GenSigTimeoutTime" BU_SG_REL_ AVM SG_ 1078 CF_Gway_PASDisplayFLH 1000;
BA_REL_ "GenSigTimeoutTime" BU_SG_REL_ CLU SG_ 1078 CF_Gway_PASDisplayFLH 1000;
BA_ "GenSigSendType" SG_ 1078 CF_Gway_PASDisplayFLH 4;
BA_REL_ "GenSigTimeoutTime" BU_SG_REL_ AVM SG_ 1078 CF_Gway_PASDisplayFRH 1000;
BA_REL_ "GenSigTimeoutTime" BU_SG_REL_ CLU SG_ 1078 CF_Gway_PASDisplayFRH 1000;
BA_ "GenSigSendType" SG_ 1078 CF_Gway_PASDisplayFRH 4;
BA_REL_ "GenSigTimeoutTime" BU_SG_REL_ CLU SG_ 1078 CF_Gway_PASRsound 1000;
BA_ "GenSigSendType" SG_ 1078 CF_Gway_PASRsound 4;
BA_REL_ "GenSigTimeoutTime" BU_SG_REL_ AVM SG_ 1078 CF_Gway_PASDisplayFCTR 1000;
BA_REL_ "GenSigTimeoutTime" BU_SG_REL_ CLU SG_ 1078 CF_Gway_PASDisplayFCTR 1000;
BA_ "GenSigSendType" SG_ 1078 CF_Gway_PASDisplayFCTR 4;
BA_REL_ "GenSigTimeoutTime" BU_SG_REL_ AVM SG_ 1078 CF_Gway_PASDisplayRCTR 1000;
BA_REL_ "GenSigTimeoutTime" BU_SG_REL_ CLU SG_ 1078 CF_Gway_PASDisplayRCTR 1000;
BA_REL_ "GenSigTimeoutTime" BU_SG_REL_ PGS SG_ 1078 CF_Gway_PASDisplayRCTR 1000;
BA_ "GenSigSendType" SG_ 1078 CF_Gway_PASDisplayRCTR 4;
BA_REL_ "GenSigTimeoutTime" BU_SG_REL_ CLU SG_ 1078 CF_Gway_PASFsound 1000;
BA_ "GenSigSendType" SG_ 1078 CF_Gway_PASFsound 4;
BA_REL_ "GenSigTimeoutTime" BU_SG_REL_ AVM SG_ 1078 CF_Gway_PASDisplayRLH 1000;
BA_REL_ "GenSigTimeoutTime" BU_SG_REL_ CLU SG_ 1078 CF_Gway_PASDisplayRLH 1000;
BA_REL_ "GenSigTimeoutTime" BU_SG_REL_ PGS SG_ 1078 CF_Gway_PASDisplayRLH 1000;
BA_ "GenSigSendType" SG_ 1078 CF_Gway_PASDisplayRLH 4;
BA_REL_ "GenSigTimeoutTime" BU_SG_REL_ AVM SG_ 1078 CF_Gway_PASDisplayRRH 1000;
BA_REL_ "GenSigTimeoutTime" BU_SG_REL_ CLU SG_ 1078 CF_Gway_PASDisplayRRH 1000;
BA_REL_ "GenSigTimeoutTime" BU_SG_REL_ PGS SG_ 1078 CF_Gway_PASDisplayRRH 1000;
BA_ "GenSigSendType" SG_ 1078 CF_Gway_PASDisplayRRH 4;
BA_REL_ "GenSigTimeoutTime" BU_SG_REL_ CLU SG_ 1078 CF_Gway_PASCheckSound 1000;
BA_ "GenSigSendType" SG_ 1078 CF_Gway_PASCheckSound 4;
BA_REL_ "GenSigTimeoutTime" BU_SG_REL_ CLU SG_ 1078 CF_Gway_PASSystemOn 1000;
BA_ "GenSigSendType" SG_ 1078 CF_Gway_PASSystemOn 4;
BA_REL_ "GenSigTimeoutTime" BU_SG_REL_ CLU SG_ 1078 CF_Gway_PASOption 1000;
BA_ "GenSigSendType" SG_ 1078 CF_Gway_PASOption 4;
BA_REL_ "GenSigTimeoutTime" BU_SG_REL_ CLU SG_ 1078 CF_Gway_PASDistance 1000;
BA_ "GenSigSendType" SG_ 1078 CF_Gway_PASDistance 4;
BA_ "GenMsgCycleTime" BO_ 1292 100;
BA_REL_ "GenSigTimeoutTime" BU_SG_REL_ BCM SG_ 1292 CF_Clu_LowfuelWarn 1000;
BA_REL_ "GenSigTimeoutTime" BU_SG_REL_ FPCM SG_ 1292 CF_Clu_LowfuelWarn 1000;
BA_REL_ "GenSigTimeoutTime" BU_SG_REL_ IBOX SG_ 1292 CF_Clu_LowfuelWarn 1000;
BA_REL_ "GenSigTimeoutTime" BU_SG_REL_ IBOX SG_ 1292 CF_Clu_RefDetMod 1000;
BA_REL_ "GenSigTimeoutTime" BU_SG_REL_ IBOX SG_ 1292 CF_Clu_AvgFCU 1000;
BA_REL_ "GenSigTimeoutTime" BU_SG_REL_ ESC SG_ 1292 CF_Clu_AvsmCur 1000;
BA_REL_ "GenSigTimeoutTime" BU_SG_REL_ SCC SG_ 1292 CF_Clu_AvsmCur 1000;
BA_REL_ "GenSigTimeoutTime" BU_SG_REL_ IBOX SG_ 1292 CF_Clu_AvgFCI 1000;
BA_REL_ "GenSigTimeoutTime" BU_SG_REL_ DATC SG_ 1292 CF_Clu_DrivingModeSwi 1000;
BA_REL_ "GenSigTimeoutTime" BU_SG_REL_ ECS SG_ 1292 CF_Clu_DrivingModeSwi 1000;
BA_REL_ "GenSigTimeoutTime" BU_SG_REL_ EMS SG_ 1292 CF_Clu_DrivingModeSwi 1000;
BA_REL_ "GenSigTimeoutTime" BU_SG_REL_ ESC SG_ 1292 CF_Clu_DrivingModeSwi 1000;
BA_REL_ "GenSigTimeoutTime" BU_SG_REL_ IAP SG_ 1292 CF_Clu_DrivingModeSwi 1000;
BA_REL_ "GenSigTimeoutTime" BU_SG_REL_ MDPS SG_ 1292 CF_Clu_DrivingModeSwi 1000;
BA_REL_ "GenSigTimeoutTime" BU_SG_REL_ TCU SG_ 1292 CF_Clu_DrivingModeSwi 1000;
BA_REL_ "GenSigTimeoutTime" BU_SG_REL_ CGW SG_ 1292 CF_Clu_FuelDispLvl 1000;
BA_REL_ "GenSigTimeoutTime" BU_SG_REL_ IBOX SG_ 1292 CF_Clu_FuelDispLvl 1000;
BA_REL_ "GenSigTimeoutTime" BU_SG_REL_ MDPS SG_ 1292 CF_Clu_FlexSteerSW 1000;
BA_REL_ "GenSigTimeoutTime" BU_SG_REL_ DATC SG_ 1292 CF_Clu_DTE 1000;
BA_REL_ "GenSigTimeoutTime" BU_SG_REL_ DATC SG_ 1292 CF_Clu_TripUnit 1000;
BA_REL_ "GenSigTimeoutTime" BU_SG_REL_ ACU SG_ 1292 CF_Clu_SWL_Stat 1000;
BA_REL_ "GenSigTimeoutTime" BU_SG_REL_ EMS SG_ 1292 CF_Clu_SWL_Stat 1000;
BA_REL_ "GenSigTimeoutTime" BU_SG_REL_ DATC SG_ 1292 CF_Clu_ActiveEcoSW 1000;
BA_REL_ "GenSigTimeoutTime" BU_SG_REL_ EMS SG_ 1292 CF_Clu_ActiveEcoSW 1000;
BA_REL_ "GenSigTimeoutTime" BU_SG_REL_ TCU SG_ 1292 CF_Clu_ActiveEcoSW 1000;
BA_REL_ "GenSigTimeoutTime" BU_SG_REL_ CUBIS SG_ 1292 CF_Clu_EcoDriveInf 1000;
BA_REL_ "GenSigTimeoutTime" BU_SG_REL_ EMS SG_ 1292 CF_Clu_EcoDriveInf 1000;
BA_REL_ "GenSigTimeoutTime" BU_SG_REL_ IAP SG_ 1292 CF_Clu_EcoDriveInf 1000;
BA_REL_ "GenSigTimeoutTime" BU_SG_REL_ IBOX SG_ 1292 CF_Clu_EcoDriveInf 1000;
BA_REL_ "GenSigTimeoutTime" BU_SG_REL_ LDWS_LKAS SG_ 1292 CF_Clu_LdwsLkasSW 1000;
BA_REL_ "GenSigTimeoutTime" BU_SG_REL_ BCM SG_ 1292 CF_Clu_AltLStatus 1000;
BA_REL_ "GenSigTimeoutTime" BU_SG_REL_ DATC SG_ 1292 CF_Clu_AltLStatus 1000;
BA_REL_ "GenSigTimeoutTime" BU_SG_REL_ EMS SG_ 1292 CF_Clu_AltLStatus 1000;
BA_REL_ "GenSigTimeoutTime" BU_SG_REL_ EMS SG_ 1292 CF_Clu_AliveCnt2 1000;
BA_REL_ "GenSigTimeoutTime" BU_SG_REL_ LDWS_LKAS SG_ 1292 CF_Clu_AliveCnt2 1000;
BA_ "GenMsgSendType" BO_ 1301 8;
BA_ "GenMsgCycleTime" BO_ 1301 0;
BA_ "GenMsgNrOfRepetition" BO_ 1301 3;
BA_REL_ "GenSigTimeoutTime" BU_SG_REL_ BCM SG_ 1301 CF_Clu_ADrUNValueSet 0;
BA_ "GenSigSendType" SG_ 1301 CF_Clu_ADrUNValueSet 4;
BA_REL_ "GenSigTimeoutTime" BU_SG_REL_ BCM SG_ 1301 CF_Clu_ADrLNValueSet 0;
BA_ "GenSigSendType" SG_ 1301 CF_Clu_ADrLNValueSet 4;
BA_REL_ "GenSigTimeoutTime" BU_SG_REL_ BCM SG_ 1301 CF_Clu_EscortHLNValueSet 0;
BA_ "GenSigSendType" SG_ 1301 CF_Clu_EscortHLNValueSet 4;
BA_REL_ "GenSigTimeoutTime" BU_SG_REL_ BCM SG_ 1301 CF_Clu_DoorLSNValueSet 0;
BA_ "GenSigSendType" SG_ 1301 CF_Clu_DoorLSNValueSet 4;
BA_REL_ "GenSigTimeoutTime" BU_SG_REL_ BCM SG_ 1301 CF_Clu_PSMNValueSet 0;
BA_ "GenSigSendType" SG_ 1301 CF_Clu_PSMNValueSet 4;
BA_REL_ "GenSigTimeoutTime" BU_SG_REL_ BCM SG_ 1301 CF_Clu_TTUnlockNValueSet 0;
BA_ "GenSigSendType" SG_ 1301 CF_Clu_TTUnlockNValueSet 4;
BA_REL_ "GenSigTimeoutTime" BU_SG_REL_ BCM SG_ 1301 CF_Clu_PTGMNValueSet 0;
BA_ "GenSigSendType" SG_ 1301 CF_Clu_PTGMNValueSet 4;
BA_REL_ "GenSigTimeoutTime" BU_SG_REL_ BCM SG_ 1301 CF_Clu_SCMNValueSet 0;
BA_ "GenSigSendType" SG_ 1301 CF_Clu_SCMNValueSet 4;
BA_REL_ "GenSigTimeoutTime" BU_SG_REL_ BCM SG_ 1301 CF_Clu_WlightNValueSet 0;
BA_ "GenSigSendType" SG_ 1301 CF_Clu_WlightNValueSet 4;
BA_REL_ "GenSigTimeoutTime" BU_SG_REL_ BCM SG_ 1301 CF_Clu_TempUnitNValueSet 0;
BA_REL_ "GenSigTimeoutTime" BU_SG_REL_ DATC SG_ 1301 CF_Clu_TempUnitNValueSet 0;
BA_ "GenSigSendType" SG_ 1301 CF_Clu_TempUnitNValueSet 4;
BA_REL_ "GenSigTimeoutTime" BU_SG_REL_ BCM SG_ 1301 CF_Clu_MoodLpNValueSet 0;
BA_ "GenSigSendType" SG_ 1301 CF_Clu_MoodLpNValueSet 4;
BA_REL_ "GenSigTimeoutTime" BU_SG_REL_ AFLS SG_ 1301 CF_Clu_TrfChgSet 0;
BA_ "GenSigSendType" SG_ 1301 CF_Clu_TrfChgSet 4;
BA_REL_ "GenSigTimeoutTime" BU_SG_REL_ BCM SG_ 1301 CF_Clu_OTTurnNValueSet 0;
BA_ "GenSigSendType" SG_ 1301 CF_Clu_OTTurnNValueSet 4;
BA_REL_ "GenSigTimeoutTime" BU_SG_REL_ LCA SG_ 1301 CF_Clu_LcaNValueSet 0;
BA_ "GenSigSendType" SG_ 1301 CF_Clu_LcaNValueSet 4;
BA_REL_ "GenSigTimeoutTime" BU_SG_REL_ LCA SG_ 1301 CF_Clu_RctaNValueSet 0;
BA_ "GenSigSendType" SG_ 1301 CF_Clu_RctaNValueSet 4;
BA_REL_ "GenSigTimeoutTime" BU_SG_REL_ LCA SG_ 1301 CF_Clu_RcwNValueSet 0;
BA_ "GenSigSendType" SG_ 1301 CF_Clu_RcwNValueSet 4;
BA_REL_ "GenSigTimeoutTime" BU_SG_REL_ ESC SG_ 1301 CF_Clu_EscOffNValueSet 0;
BA_ "GenSigSendType" SG_ 1301 CF_Clu_EscOffNValueSet 4;
BA_REL_ "GenSigTimeoutTime" BU_SG_REL_ SCC SG_ 1301 CF_Clu_SccNaviCrvNValueSet 0;
BA_ "GenSigSendType" SG_ 1301 CF_Clu_SccNaviCrvNValueSet 4;
BA_REL_ "GenSigTimeoutTime" BU_SG_REL_ SCC SG_ 1301 CF_Clu_SccNaviCamNValueSet 0;
BA_ "GenSigSendType" SG_ 1301 CF_Clu_SccNaviCamNValueSet 4;
BA_REL_ "GenSigTimeoutTime" BU_SG_REL_ SCC SG_ 1301 CF_Clu_SccAebNValueSet 0;
BA_ "GenSigSendType" SG_ 1301 CF_Clu_SccAebNValueSet 4;
BA_REL_ "GenSigTimeoutTime" BU_SG_REL_ LDWS_LKAS SG_ 1301 CF_Clu_LkasModeNValueSet 0;
BA_ "GenSigSendType" SG_ 1301 CF_Clu_LkasModeNValueSet 4;
BA_REL_ "GenSigTimeoutTime" BU_SG_REL_ LDWS_LKAS SG_ 1301 CF_Clu_FcwNValueSet 0;
BA_ "GenSigSendType" SG_ 1301 CF_Clu_FcwNValueSet 4;
BA_REL_ "GenSigTimeoutTime" BU_SG_REL_ BCM SG_ 1301 CF_Clu_PasSpkrLvNValueSet 0;
BA_ "GenSigSendType" SG_ 1301 CF_Clu_PasSpkrLvNValueSet 4;
BA_REL_ "GenSigTimeoutTime" BU_SG_REL_ SCC SG_ 1301 CF_Clu_SccDrvModeNValueSet 0;
BA_ "GenSigSendType" SG_ 1301 CF_Clu_SccDrvModeNValueSet 4;
BA_REL_ "GenSigTimeoutTime" BU_SG_REL_ BCM SG_ 1301 CF_Clu_HAnBNValueSet 0;
BA_ "GenSigSendType" SG_ 1301 CF_Clu_HAnBNValueSet 4;
BA_REL_ "GenSigTimeoutTime" BU_SG_REL_ BCM SG_ 1301 CF_Clu_HfreeTrunkTgNValueSet 0;
BA_ "GenSigSendType" SG_ 1301 CF_Clu_HfreeTrunkTgNValueSet 4;
BA_ "GenMsgCycleTime" BO_ 1322 200;
BA_ "GenMsgNrOfRepetition" BO_ 1322 3;
BA_REL_ "GenSigTimeoutTime" BU_SG_REL_ BCM SG_ 1322 CF_Clu_VehicleSpeed 0;
BA_ "GenSigSendType" SG_ 1322 CF_Clu_VehicleSpeed 4;
BA_REL_ "GenSigTimeoutTime" BU_SG_REL_ BCM SG_ 1322 CF_Clu_InhibitP 0;
BA_ "GenSigSendType" SG_ 1322 CF_Clu_InhibitP 4;
BA_REL_ "GenSigTimeoutTime" BU_SG_REL_ BCM SG_ 1322 CF_Clu_InhibitR 0;
BA_ "GenSigSendType" SG_ 1322 CF_Clu_InhibitR 4;
BA_REL_ "GenSigTimeoutTime" BU_SG_REL_ BCM SG_ 1322 CF_Clu_InhibitN 0;
BA_ "GenSigSendType" SG_ 1322 CF_Clu_InhibitN 4;
BA_REL_ "GenSigTimeoutTime" BU_SG_REL_ BCM SG_ 1322 CF_Clu_InhibitD 0;
BA_ "GenSigSendType" SG_ 1322 CF_Clu_InhibitD 4;
BA_REL_ "GenSigTimeoutTime" BU_SG_REL_ HUD SG_ 1322 CF_Clu_HudInfoSet 1000;
BA_ "GenSigSendType" SG_ 1322 CF_Clu_HudInfoSet 4;
BA_REL_ "GenSigTimeoutTime" BU_SG_REL_ HUD SG_ 1322 CF_Clu_HudFontColorSet 1000;
BA_ "GenSigSendType" SG_ 1322 CF_Clu_HudFontColorSet 4;
BA_REL_ "GenSigTimeoutTime" BU_SG_REL_ HUD SG_ 1322 CF_Clu_HudBrightUpSW 1000;
BA_ "GenSigSendType" SG_ 1322 CF_Clu_HudBrightUpSW 4;
BA_REL_ "GenSigTimeoutTime" BU_SG_REL_ HUD SG_ 1322 CF_Clu_HudBrightDnSW 1000;
BA_ "GenSigSendType" SG_ 1322 CF_Clu_HudBrightDnSW 4;
BA_REL_ "GenSigTimeoutTime" BU_SG_REL_ HUD SG_ 1322 CF_Clu_HudHeightUpSW 1000;
BA_ "GenSigSendType" SG_ 1322 CF_Clu_HudHeightUpSW 4;
BA_REL_ "GenSigTimeoutTime" BU_SG_REL_ HUD SG_ 1322 CF_Clu_HudHeightDnSW 1000;
BA_ "GenSigSendType" SG_ 1322 CF_Clu_HudHeightDnSW 4;
BA_REL_ "GenSigTimeoutTime" BU_SG_REL_ HUD SG_ 1322 CF_Clu_HudSet 1000;
BA_ "GenSigSendType" SG_ 1322 CF_Clu_HudSet 4;
BA_REL_ "GenSigTimeoutTime" BU_SG_REL_ HUD SG_ 1322 CF_Clu_HudFontSizeSet 1000;
BA_ "GenSigSendType" SG_ 1322 CF_Clu_HudFontSizeSet 4;
BA_REL_ "GenSigTimeoutTime" BU_SG_REL_ BCM SG_ 1322 CF_Clu_LanguageInfo 0;
BA_REL_ "GenSigTimeoutTime" BU_SG_REL_ PGS SG_ 1322 CF_Clu_LanguageInfo 0;
BA_ "GenSigSendType" SG_ 1322 CF_Clu_LanguageInfo 4;
BA_REL_ "GenSigTimeoutTime" BU_SG_REL_ BCM SG_ 1322 CF_Clu_ClusterSound 1000;
BA_REL_ "GenSigTimeoutTime" BU_SG_REL_ CGW SG_ 1322 CF_Clu_ClusterSound 1000;
BA_REL_ "GenSigTimeoutTime" BU_SG_REL_ FATC SG_ 1322 CF_Clu_ClusterSound 1000;
BA_ "GenSigSendType" SG_ 1322 CF_Clu_ClusterSound 4;
BA_ "GenMsgSendType" BO_ 1307 8;
BA_ "GenMsgCycleTime" BO_ 1307 0;
BA_ "GenMsgNrOfRepetition" BO_ 1307 3;
BA_REL_ "GenSigTimeoutTime" BU_SG_REL_ TPMS SG_ 1307 CF_Clu_TirePressUnitNValueSet 0;
BA_ "GenSigSendType" SG_ 1307 CF_Clu_TirePressUnitNValueSet 4;
BA_REL_ "GenSigTimeoutTime" BU_SG_REL_ LDWS_LKAS SG_ 1307 CF_Clu_SlifNValueSet 0;
BA_ "GenSigSendType" SG_ 1307 CF_Clu_SlifNValueSet 4;
BA_REL_ "GenSigTimeoutTime" BU_SG_REL_ BCM SG_ 1307 CF_Clu_RearWiperNValueSet 0;
BA_ "GenSigSendType" SG_ 1307 CF_Clu_RearWiperNValueSet 4;
BA_ "GenMsgSendType" BO_ 1024 8;
BA_ "GenMsgCycleTime" BO_ 1024 0;
BA_ "GenMsgNrOfRepetition" BO_ 1024 3;
BA_REL_ "GenSigTimeoutTime" BU_SG_REL_ _4WD SG_ 1024 Vehicle_Type 0;
BA_ "GenSigSendType" SG_ 1024 Vehicle_Type 4;
BA_ "GenMsgSendType" BO_ 1318 8;
BA_ "GenMsgCycleTime" BO_ 1318 0;
BA_ "GenMsgNrOfRepetition" BO_ 1318 3;
BA_REL_ "GenSigTimeoutTime" BU_SG_REL_ BCM SG_ 1318 C_ADrLURValueReq 0;
BA_ "GenSigSendType" SG_ 1318 C_ADrLURValueReq 4;
BA_ "GenSigStartValue" SG_ 1318 C_ADrLURValueReq 3;
BA_REL_ "GenSigTimeoutTime" BU_SG_REL_ BCM SG_ 1318 C_TwUnRValueReq 0;
BA_ "GenSigSendType" SG_ 1318 C_TwUnRValueReq 4;
BA_ "GenSigStartValue" SG_ 1318 C_TwUnRValueReq 3;
BA_REL_ "GenSigTimeoutTime" BU_SG_REL_ BCM SG_ 1318 C_AlarmRValueReq 0;
BA_ "GenSigSendType" SG_ 1318 C_AlarmRValueReq 4;
BA_ "GenSigStartValue" SG_ 1318 C_AlarmRValueReq 3;
BA_REL_ "GenSigTimeoutTime" BU_SG_REL_ BCM SG_ 1318 C_IMSRValueReq 0;
BA_ "GenSigSendType" SG_ 1318 C_IMSRValueReq 4;
BA_ "GenSigStartValue" SG_ 1318 C_IMSRValueReq 3;
BA_REL_ "GenSigTimeoutTime" BU_SG_REL_ BCM SG_ 1318 C_HLEscortRValueReq 0;
BA_ "GenSigSendType" SG_ 1318 C_HLEscortRValueReq 4;
BA_ "GenSigStartValue" SG_ 1318 C_HLEscortRValueReq 3;
BA_REL_ "GenSigTimeoutTime" BU_SG_REL_ BCM SG_ 1318 C_WELRValueReq 0;
BA_ "GenSigSendType" SG_ 1318 C_WELRValueReq 4;
BA_ "GenSigStartValue" SG_ 1318 C_WELRValueReq 3;
BA_REL_ "GenSigTimeoutTime" BU_SG_REL_ BCM SG_ 1318 C_TriTurnLRValueReq 0;
BA_ "GenSigSendType" SG_ 1318 C_TriTurnLRValueReq 4;
BA_ "GenSigStartValue" SG_ 1318 C_TriTurnLRValueReq 3;
BA_REL_ "GenSigTimeoutTime" BU_SG_REL_ BCM SG_ 1318 C_SNVWarnRValueReq 0;
BA_ "GenSigSendType" SG_ 1318 C_SNVWarnRValueReq 4;
BA_ "GenSigStartValue" SG_ 1318 C_SNVWarnRValueReq 3;
BA_REL_ "GenSigTimeoutTime" BU_SG_REL_ BCM SG_ 1318 C_LkasWarnRValueReq 0;
BA_ "GenSigSendType" SG_ 1318 C_LkasWarnRValueReq 4;
BA_ "GenSigStartValue" SG_ 1318 C_LkasWarnRValueReq 3;
BA_ "GenMsgSendType" BO_ 1319 8;
BA_ "GenMsgCycleTime" BO_ 1319 0;
BA_ "GenMsgNrOfRepetition" BO_ 1319 3;
BA_REL_ "GenSigTimeoutTime" BU_SG_REL_ BCM SG_ 1319 C_ADrLNValueSet 0;
BA_ "GenSigSendType" SG_ 1319 C_ADrLNValueSet 4;
BA_ "GenSigStartValue" SG_ 1319 C_ADrLNValueSet 7;
BA_REL_ "GenSigTimeoutTime" BU_SG_REL_ BCM SG_ 1319 C_ADrUNValueSet 0;
BA_ "GenSigSendType" SG_ 1319 C_ADrUNValueSet 4;
BA_ "GenSigStartValue" SG_ 1319 C_ADrUNValueSet 7;
BA_REL_ "GenSigTimeoutTime" BU_SG_REL_ BCM SG_ 1319 C_TwUnNValueSet 0;
BA_ "GenSigSendType" SG_ 1319 C_TwUnNValueSet 4;
BA_ "GenSigStartValue" SG_ 1319 C_TwUnNValueSet 3;
BA_REL_ "GenSigTimeoutTime" BU_SG_REL_ BCM SG_ 1319 C_ABuzzerNValueSet 0;
BA_ "GenSigSendType" SG_ 1319 C_ABuzzerNValueSet 4;
BA_ "GenSigStartValue" SG_ 1319 C_ABuzzerNValueSet 3;
BA_REL_ "GenSigTimeoutTime" BU_SG_REL_ BCM SG_ 1319 C_ArmWKeyNValueSet 0;
BA_ "GenSigSendType" SG_ 1319 C_ArmWKeyNValueSet 4;
BA_ "GenSigStartValue" SG_ 1319 C_ArmWKeyNValueSet 3;
BA_REL_ "GenSigTimeoutTime" BU_SG_REL_ BCM SG_ 1319 C_PSMNValueSet 0;
BA_ "GenSigSendType" SG_ 1319 C_PSMNValueSet 4;
BA_ "GenSigStartValue" SG_ 1319 C_PSMNValueSet 3;
BA_REL_ "GenSigTimeoutTime" BU_SG_REL_ BCM SG_ 1319 C_SCMNValueSet 0;
BA_ "GenSigSendType" SG_ 1319 C_SCMNValueSet 4;
BA_ "GenSigStartValue" SG_ 1319 C_SCMNValueSet 3;
BA_REL_ "GenSigTimeoutTime" BU_SG_REL_ BCM SG_ 1319 C_HLEscortNValueSet 0;
BA_ "GenSigSendType" SG_ 1319 C_HLEscortNValueSet 4;
BA_ "GenSigStartValue" SG_ 1319 C_HLEscortNValueSet 3;
BA_REL_ "GenSigTimeoutTime" BU_SG_REL_ BCM SG_ 1319 C_WELNValueSet 0;
BA_ "GenSigSendType" SG_ 1319 C_WELNValueSet 4;
BA_ "GenSigStartValue" SG_ 1319 C_WELNValueSet 3;
BA_REL_ "GenSigTimeoutTime" BU_SG_REL_ BCM SG_ 1319 C_TriTurnLNValueSet 0;
BA_ "GenSigSendType" SG_ 1319 C_TriTurnLNValueSet 4;
BA_ "GenSigStartValue" SG_ 1319 C_TriTurnLNValueSet 3;
BA_REL_ "GenSigTimeoutTime" BU_SG_REL_ BCM SG_ 1319 C_SNVWarnNValueSet 0;
BA_ "GenSigSendType" SG_ 1319 C_SNVWarnNValueSet 4;
BA_ "GenSigStartValue" SG_ 1319 C_SNVWarnNValueSet 3;
BA_REL_ "GenSigTimeoutTime" BU_SG_REL_ BCM SG_ 1319 C_LkasWarnNValueSet 0;
BA_ "GenSigSendType" SG_ 1319 C_LkasWarnNValueSet 4;
BA_ "GenSigStartValue" SG_ 1319 C_LkasWarnNValueSet 3;
BA_ "GenMsgSendType" BO_ 1338 8;
BA_ "GenMsgCycleTime" BO_ 1338 0;
BA_ "GenMsgNrOfRepetition" BO_ 1338 3;
BA_ "GenSigSendType" SG_ 1338 CF_Gway_TeleReqDrLock 4;
BA_ "GenSigSendType" SG_ 1338 CF_Gway_TeleReqDrUnlock 4;
BA_ "GenSigSendType" SG_ 1338 CF_Gway_TeleReqHazard 4;
BA_ "GenSigSendType" SG_ 1338 CF_Gway_TeleReqHorn 4;
BA_ "GenSigSendType" SG_ 1338 CF_Gway_TeleReqEngineOperate 4;
BA_ "GenMsgCycleTime" BO_ 68 1000;
BA_ "GenMsgNrOfRepetition" BO_ 68 3;
BA_REL_ "GenSigTimeoutTime" BU_SG_REL_ CLU SG_ 68 CF_Datc_Type 5000;
BA_ "GenSigSendType" SG_ 68 CF_Datc_Type 4;
BA_REL_ "GenSigTimeoutTime" BU_SG_REL_ CLU SG_ 68 CF_Datc_VerMaj 5000;
BA_ "GenSigSendType" SG_ 68 CF_Datc_VerMaj 4;
BA_REL_ "GenSigTimeoutTime" BU_SG_REL_ CLU SG_ 68 CF_Datc_VerMin 5000;
BA_ "GenSigSendType" SG_ 68 CF_Datc_VerMin 4;
BA_REL_ "GenSigTimeoutTime" BU_SG_REL_ CLU SG_ 68 CR_Datc_OutTempC 5000;
BA_REL_ "GenSigTimeoutTime" BU_SG_REL_ FPCM SG_ 68 CR_Datc_OutTempC 5000;
BA_ "GenSigSendType" SG_ 68 CR_Datc_OutTempC 4;
BA_REL_ "GenSigTimeoutTime" BU_SG_REL_ CLU SG_ 68 CR_Datc_OutTempF 5000;
BA_ "GenSigSendType" SG_ 68 CR_Datc_OutTempF 4;
BA_REL_ "GenSigTimeoutTime" BU_SG_REL_ BCM SG_ 68 CF_Datc_IncarTemp 5000;
BA_REL_ "GenSigTimeoutTime" BU_SG_REL_ CLU SG_ 68 CF_Datc_IncarTemp 5000;
BA_ "GenSigSendType" SG_ 68 CF_Datc_IncarTemp 4;
BA_ "GenMsgCycleTime" BO_ 66 1000;
BA_ "GenMsgNrOfRepetition" BO_ 66 3;
BA_REL_ "GenSigTimeoutTime" BU_SG_REL_ CLU SG_ 66 CR_Datc_DrTempDispC 5000;
BA_REL_ "GenSigTimeoutTime" BU_SG_REL_ IBOX SG_ 66 CR_Datc_DrTempDispC 5000;
BA_ "GenSigSendType" SG_ 66 CR_Datc_DrTempDispC 4;
BA_REL_ "GenSigTimeoutTime" BU_SG_REL_ CLU SG_ 66 CR_Datc_DrTempDispF 5000;
BA_REL_ "GenSigTimeoutTime" BU_SG_REL_ IBOX SG_ 66 CR_Datc_DrTempDispF 5000;
BA_ "GenSigSendType" SG_ 66 CR_Datc_DrTempDispF 4;
BA_REL_ "GenSigTimeoutTime" BU_SG_REL_ CLU SG_ 66 CR_Datc_PsTempDispC 5000;
BA_REL_ "GenSigTimeoutTime" BU_SG_REL_ IBOX SG_ 66 CR_Datc_PsTempDispC 5000;
BA_ "GenSigSendType" SG_ 66 CR_Datc_PsTempDispC 4;
BA_REL_ "GenSigTimeoutTime" BU_SG_REL_ CLU SG_ 66 CR_Datc_PsTempDispF 5000;
BA_REL_ "GenSigTimeoutTime" BU_SG_REL_ IBOX SG_ 66 CR_Datc_PsTempDispF 5000;
BA_ "GenSigSendType" SG_ 66 CR_Datc_PsTempDispF 4;
BA_REL_ "GenSigTimeoutTime" BU_SG_REL_ CLU SG_ 66 CR_Datc_RearDrTempDispC 5000;
BA_ "GenSigSendType" SG_ 66 CR_Datc_RearDrTempDispC 4;
BA_REL_ "GenSigTimeoutTime" BU_SG_REL_ CLU SG_ 66 CR_Datc_RearDrTempDispF 5000;
BA_ "GenSigSendType" SG_ 66 CR_Datc_RearDrTempDispF 4;
BA_REL_ "GenSigTimeoutTime" BU_SG_REL_ CLU SG_ 66 CF_Datc_CO2_Warning 5000;
BA_ "GenSigSendType" SG_ 66 CF_Datc_CO2_Warning 4;
BA_ "GenMsgCycleTime" BO_ 67 1000;
BA_ "GenMsgNrOfRepetition" BO_ 67 3;
BA_REL_ "GenSigTimeoutTime" BU_SG_REL_ CLU SG_ 67 CF_Datc_TempDispUnit 5000;
BA_REL_ "GenSigTimeoutTime" BU_SG_REL_ IBOX SG_ 67 CF_Datc_TempDispUnit 5000;
BA_ "GenSigSendType" SG_ 67 CF_Datc_TempDispUnit 4;
BA_REL_ "GenSigTimeoutTime" BU_SG_REL_ CLU SG_ 67 CF_Datc_ModDisp 5000;
BA_ "GenSigSendType" SG_ 67 CF_Datc_ModDisp 4;
BA_REL_ "GenSigTimeoutTime" BU_SG_REL_ CLU SG_ 67 CF_Datc_IonClean 5000;
BA_ "GenSigSendType" SG_ 67 CF_Datc_IonClean 4;
BA_REL_ "GenSigTimeoutTime" BU_SG_REL_ CLU SG_ 67 CF_Datc_ChgReqDisp 5000;
BA_ "GenSigSendType" SG_ 67 CF_Datc_ChgReqDisp 4;
BA_REL_ "GenSigTimeoutTime" BU_SG_REL_ CLU SG_ 67 CF_Datc_IntakeDisp 5000;
BA_ "GenSigSendType" SG_ 67 CF_Datc_IntakeDisp 4;
BA_REL_ "GenSigTimeoutTime" BU_SG_REL_ CLU SG_ 67 CF_Datc_AutoDisp 5000;
BA_ "GenSigSendType" SG_ 67 CF_Datc_AutoDisp 4;
BA_REL_ "GenSigTimeoutTime" BU_SG_REL_ CLU SG_ 67 CF_Datc_FrDefLed 5000;
BA_REL_ "GenSigTimeoutTime" BU_SG_REL_ IBOX SG_ 67 CF_Datc_FrDefLed 5000;
BA_ "GenSigSendType" SG_ 67 CF_Datc_FrDefLed 4;
BA_REL_ "GenSigTimeoutTime" BU_SG_REL_ CLU SG_ 67 CF_Datc_AutoDefogBlink 5000;
BA_ "GenSigSendType" SG_ 67 CF_Datc_AutoDefogBlink 4;
BA_REL_ "GenSigTimeoutTime" BU_SG_REL_ CLU SG_ 67 CF_Datc_ClmScanDisp 5000;
BA_ "GenSigSendType" SG_ 67 CF_Datc_ClmScanDisp 4;
BA_REL_ "GenSigTimeoutTime" BU_SG_REL_ CLU SG_ 67 CF_Datc_AqsDisp 5000;
BA_ "GenSigSendType" SG_ 67 CF_Datc_AqsDisp 4;
BA_REL_ "GenSigTimeoutTime" BU_SG_REL_ CLU SG_ 67 CF_Datc_AcDisp 5000;
BA_ "GenSigSendType" SG_ 67 CF_Datc_AcDisp 4;
BA_REL_ "GenSigTimeoutTime" BU_SG_REL_ CLU SG_ 67 CF_Datc_OpSts 5000;
BA_ "GenSigSendType" SG_ 67 CF_Datc_OpSts 4;
BA_ "GenSigStartValue" SG_ 67 CF_Datc_OpSts 7;
BA_REL_ "GenSigTimeoutTime" BU_SG_REL_ CLU SG_ 67 CF_Mtc_MaxAcDisp 5000;
BA_ "GenSigSendType" SG_ 67 CF_Mtc_MaxAcDisp 4;
BA_REL_ "GenSigTimeoutTime" BU_SG_REL_ CLU SG_ 67 CF_Datc_DualDisp 5000;
BA_ "GenSigSendType" SG_ 67 CF_Datc_DualDisp 4;
BA_REL_ "GenSigTimeoutTime" BU_SG_REL_ CLU SG_ 67 CF_Datc_PwrInf 5000;
BA_ "GenSigSendType" SG_ 67 CF_Datc_PwrInf 4;
BA_REL_ "GenSigTimeoutTime" BU_SG_REL_ CLU SG_ 67 CF_Datc_RearManual 5000;
BA_ "GenSigSendType" SG_ 67 CF_Datc_RearManual 4;
BA_REL_ "GenSigTimeoutTime" BU_SG_REL_ CLU SG_ 67 CF_Datc_RearAutoDisp 5000;
BA_ "GenSigSendType" SG_ 67 CF_Datc_RearAutoDisp 4;
BA_REL_ "GenSigTimeoutTime" BU_SG_REL_ CLU SG_ 67 CF_Datc_RearOffDisp 5000;
BA_ "GenSigSendType" SG_ 67 CF_Datc_RearOffDisp 4;
BA_REL_ "GenSigTimeoutTime" BU_SG_REL_ CLU SG_ 67 CF_Datc_RearClimateScnDisp 5000;
BA_ "GenSigSendType" SG_ 67 CF_Datc_RearClimateScnDisp 4;
BA_REL_ "GenSigTimeoutTime" BU_SG_REL_ CLU SG_ 67 CF_Datc_RearChgReqDisp 5000;
BA_ "GenSigSendType" SG_ 67 CF_Datc_RearChgReqDisp 4;
BA_REL_ "GenSigTimeoutTime" BU_SG_REL_ CLU SG_ 67 CF_Datc_RearModDisp 5000;
BA_ "GenSigSendType" SG_ 67 CF_Datc_RearModDisp 4;
BA_REL_ "GenSigTimeoutTime" BU_SG_REL_ CLU SG_ 67 CF_Datc_RearBlwDisp 5000;
BA_ "GenSigSendType" SG_ 67 CF_Datc_RearBlwDisp 4;
BA_REL_ "GenSigTimeoutTime" BU_SG_REL_ CLU SG_ 67 CF_Datc_PSModDisp 5000;
BA_ "GenSigSendType" SG_ 67 CF_Datc_PSModDisp 4;
BA_REL_ "GenSigTimeoutTime" BU_SG_REL_ CLU SG_ 67 CF_Datc_FrontBlwDisp 5000;
BA_REL_ "GenSigTimeoutTime" BU_SG_REL_ IBOX SG_ 67 CF_Datc_FrontBlwDisp 5000;
BA_ "GenSigSendType" SG_ 67 CF_Datc_FrontBlwDisp 4;
BA_ "GenMsgCycleTime" BO_ 64 200;
BA_ "GenMsgNrOfRepetition" BO_ 64 3;
BA_REL_ "GenSigTimeoutTime" BU_SG_REL_ CLU SG_ 64 CF_Datc_AqsLevelOut 1000;
BA_ "GenSigSendType" SG_ 64 CF_Datc_AqsLevelOut 4;
BA_REL_ "GenSigTimeoutTime" BU_SG_REL_ CLU SG_ 64 CF_Datc_DiagMode 1000;
BA_ "GenSigSendType" SG_ 64 CF_Datc_DiagMode 4;
BA_REL_ "GenSigTimeoutTime" BU_SG_REL_ CLU SG_ 64 CR_Datc_SelfDiagCode 1000;
BA_ "GenSigSendType" SG_ 64 CR_Datc_SelfDiagCode 4;
BA_REL_ "GenSigTimeoutTime" BU_SG_REL_ CLU SG_ 64 DATC_SyncDisp 0;
BA_ "GenSigSendType" SG_ 64 DATC_SyncDisp 4;
BA_ "GenSigStartValue" SG_ 64 DATC_SyncDisp 15;
BA_REL_ "GenSigTimeoutTime" BU_SG_REL_ CLU SG_ 64 DATC_OffDisp 1000;
BA_ "GenSigSendType" SG_ 64 DATC_OffDisp 4;
BA_ "GenSigStartValue" SG_ 64 DATC_OffDisp 3;
BA_REL_ "GenSigTimeoutTime" BU_SG_REL_ CLU SG_ 64 DATC_SmartVentDisp 1000;
BA_ "GenSigSendType" SG_ 64 DATC_SmartVentDisp 4;
BA_REL_ "GenSigTimeoutTime" BU_SG_REL_ CLU SG_ 64 DATC_SmartVentOnOffStatus 0;
BA_ "GenSigSendType" SG_ 64 DATC_SmartVentOnOffStatus 4;
BA_REL_ "GenSigTimeoutTime" BU_SG_REL_ CLU SG_ 64 DATC_AutoDefogSysOff_Disp 0;
BA_ "GenSigSendType" SG_ 64 DATC_AutoDefogSysOff_Disp 4;
BA_ "GenSigStartValue" SG_ 64 DATC_AutoDefogSysOff_Disp 3;
BA_REL_ "GenSigTimeoutTime" BU_SG_REL_ CLU SG_ 64 DATC_ADSDisp 0;
BA_ "GenSigSendType" SG_ 64 DATC_ADSDisp 4;
BA_ "GenSigStartValue" SG_ 64 DATC_ADSDisp 3;
BA_ "GenMsgCycleTime" BO_ 1350 100;
BA_REL_ "GenSigTimeoutTime" BU_SG_REL_ EMS SG_ 1350 CF_DiBox_FrtInjVDiagReg0 1000;
BA_REL_ "GenSigTimeoutTime" BU_SG_REL_ EMS SG_ 1350 CF_DiBox_FrtInjVDiagReg1 1000;
BA_REL_ "GenSigTimeoutTime" BU_SG_REL_ EMS SG_ 1350 CF_DiBox_FrtInjVDiagReg2 1000;
BA_REL_ "GenSigTimeoutTime" BU_SG_REL_ EMS SG_ 1350 CF_DiBox_SedInjVDiagReg0 1000;
BA_REL_ "GenSigTimeoutTime" BU_SG_REL_ EMS SG_ 1350 CF_DiBox_SedInjVDiagReg1 1000;
BA_REL_ "GenSigTimeoutTime" BU_SG_REL_ EMS SG_ 1350 CF_DiBox_SedInjVDiagReg2 1000;
BA_REL_ "GenSigTimeoutTime" BU_SG_REL_ EMS SG_ 1350 CR_DiBox_BatVol 1000;
BA_REL_ "GenSigTimeoutTime" BU_SG_REL_ EMS SG_ 1350 CF_DiBox_SedInjVChg 1000;
BA_REL_ "GenSigTimeoutTime" BU_SG_REL_ EMS SG_ 1350 CF_DiBox_FrtInjVChg 1000;
BA_REL_ "GenSigTimeoutTime" BU_SG_REL_ EMS SG_ 1350 CF_DiBox_SedInjVErrSPI 1000;
BA_REL_ "GenSigTimeoutTime" BU_SG_REL_ EMS SG_ 1350 CF_DiBox_FrtInjVErrSPI 1000;
BA_ "GenMsgCycleTime" BO_ 1281 100;
BA_REL_ "GenSigTimeoutTime" BU_SG_REL_ CLU SG_ 1281 ECS_W_LAMP 1000;
BA_REL_ "GenSigTimeoutTime" BU_SG_REL_ CUBIS SG_ 1281 ECS_W_LAMP 1000;
BA_REL_ "GenSigTimeoutTime" BU_SG_REL_ IBOX SG_ 1281 ECS_W_LAMP 1000;
BA_REL_ "GenSigTimeoutTime" BU_SG_REL_ CLU SG_ 1281 SYS_NA 1000;
BA_REL_ "GenSigTimeoutTime" BU_SG_REL_ CLU SG_ 1281 ECS_DEF 1000;
BA_REL_ "GenSigTimeoutTime" BU_SG_REL_ CLU SG_ 1281 ECS_DIAG 1000;
BA_REL_ "GenSigTimeoutTime" BU_SG_REL_ CLU SG_ 1281 L_CHG_NA 1000;
BA_REL_ "GenSigTimeoutTime" BU_SG_REL_ CLU SG_ 1281 Leveling_Off 1000;
BA_REL_ "GenSigTimeoutTime" BU_SG_REL_ CLU SG_ 1281 LC_overheat 1000;
BA_REL_ "GenSigTimeoutTime" BU_SG_REL_ CLU SG_ 1281 Lifting 1000;
BA_REL_ "GenSigTimeoutTime" BU_SG_REL_ CLU SG_ 1281 Lowering 1000;
BA_REL_ "GenSigTimeoutTime" BU_SG_REL_ CLU SG_ 1281 Damping_Mode 1000;
BA_REL_ "GenSigTimeoutTime" BU_SG_REL_ CLU SG_ 1281 REQ_Damping 1000;
BA_REL_ "GenSigTimeoutTime" BU_SG_REL_ CLU SG_ 1281 REQ_Height 1000;
BA_REL_ "GenSigTimeoutTime" BU_SG_REL_ CLU SG_ 1281 REQ_level 1000;
BA_REL_ "GenSigTimeoutTime" BU_SG_REL_ CLU SG_ 1281 ACT_Height 1000;
BA_ "GenMsgCycleTime" BO_ 1353 100;
BA_ "GenSigStartValue" SG_ 1353 BAT_SNSR_I 65535;
BA_ "GenSigStartValue" SG_ 1353 BAT_SNSR_V 16383;
BA_ "GenSigStartValue" SG_ 1353 BAT_SNSR_Temp 511;
BA_ "GenSigStartValue" SG_ 1353 BAT_SNSR_State 1;
BA_ "GenSigStartValue" SG_ 1353 BAT_SOH 127;
BA_ "GenSigStartValue" SG_ 1353 BAT_SNSR_Invalid 1;
BA_ "GenSigStartValue" SG_ 1353 BAT_SOF 127;
BA_ "GenSigStartValue" SG_ 1353 BAT_SNSR_Error 1;
BA_ "GenSigStartValue" SG_ 790 SWI_IGK 1;
BA_ "GenSigStartValue" SG_ 790 RATIO_TQI_BAS_MAX_STND 127;
BA_ "GenSigStartValue" SG_ 809 TEMP_ENG 255;
BA_ "GenSigStartValue" SG_ 809 MAF_FAC_ALTI_MMV 128;
BA_ "GenSigStartValue" SG_ 809 CONF_MIL_FMY 3;
BA_ "GenSigStartValue" SG_ 809 BRAKE_ACT 1;
BA_ "GenSigStartValue" SG_ 809 TPS 32;
BA_ "GenMsgCycleTime" BO_ 1349 100;
BA_ "GenSigStartValue" SG_ 1349 AMP_CAN 28;
BA_ "GenSigStartValue" SG_ 1349 BAT_Alt_FR_Duty 255;
BA_ "GenSigStartValue" SG_ 1349 TEMP_FUEL 255;
BA_ "GenMsgCycleTime" BO_ 1351 100;
BA_ "GenMsgCycleTime" BO_ 48 20;
BA_ "GenMsgNrOfRepetition" BO_ 48 3;
BA_REL_ "GenSigTimeoutTime" BU_SG_REL_ DI_BOX SG_ 48 CF_Ems_DC1NumPerMSV 1000;
BA_ "GenSigSendType" SG_ 48 CF_Ems_DC1NumPerMSV 4;
BA_REL_ "GenSigTimeoutTime" BU_SG_REL_ DI_BOX SG_ 48 CF_Ems_DC2NumPerMSV 1000;
BA_ "GenSigSendType" SG_ 48 CF_Ems_DC2NumPerMSV 4;
BA_REL_ "GenSigTimeoutTime" BU_SG_REL_ DI_BOX SG_ 48 CR_Ems_DutyCyc1MSV 1000;
BA_ "GenSigSendType" SG_ 48 CR_Ems_DutyCyc1MSV 4;
BA_REL_ "GenSigTimeoutTime" BU_SG_REL_ DI_BOX SG_ 48 CR_Ems_DutyCyc2MSV 1000;
BA_ "GenSigSendType" SG_ 48 CR_Ems_DutyCyc2MSV 4;
BA_REL_ "GenSigTimeoutTime" BU_SG_REL_ DI_BOX SG_ 48 CR_Ems_DutyCyc3MSV 1000;
BA_ "GenSigSendType" SG_ 48 CR_Ems_DutyCyc3MSV 4;
BA_ "GenSigStartValue" SG_ 339 TQI_TCS 255;
BA_ "GenSigStartValue" SG_ 339 TQI_SLW_TCS 255;
BA_ "GenMsgCycleTime" BO_ 1287 100;
BA_ "GenMsgCycleTime" BO_ 1360 100;
BA_ "GenSigStartValue" SG_ 832 CR_Lkas_StrToqReq 1024;
BA_ "GenMsgCycleTime" BO_ 1342 100;
BA_ "GenSigStartValue" SG_ 593 CR_Mdps_StrColTq 1024;
BA_ "GenSigStartValue" SG_ 593 CR_Mdps_StrTq 2048;
BA_ "GenSigStartValue" SG_ 593 CR_Mdps_OutTq 2048;
BA_ "GenMsgCycleTime" BO_ 1056 20;
BA_ "GenSigStartValue" SG_ 1056 ACC_ObjStatus 3;
BA_ "GenSigStartValue" SG_ 1056 ACC_ObjLatPos 511;
BA_ "GenSigStartValue" SG_ 1056 ACC_ObjDist 2047;
BA_ "GenSigStartValue" SG_ 1056 ACC_ObjRelSpd 4095;
BA_ "GenMsgCycleTime" BO_ 1057 20;
BA_ "GenMsgCycleTime" BO_ 1290 200;
BA_ "GenMsgNrOfRepetition" BO_ 1290 3;
BA_REL_ "GenSigTimeoutTime" BU_SG_REL_ CLU SG_ 1290 SCCDrvModeRValue 0;
BA_ "GenSigSendType" SG_ 1290 SCCDrvModeRValue 4;
BA_ "GenSigStartValue" SG_ 1290 SCCDrvModeRValue 2;
BA_REL_ "GenSigTimeoutTime" BU_SG_REL_ ESC SG_ 1290 SCC_Equip 2000;
BA_ "GenSigSendType" SG_ 1290 SCC_Equip 4;
BA_REL_ "GenSigTimeoutTime" BU_SG_REL_ CLU SG_ 1290 AebDrvSetStatus 2000;
BA_REL_ "GenSigTimeoutTime" BU_SG_REL_ ESC SG_ 1290 AebDrvSetStatus 2000;
BA_ "GenSigSendType" SG_ 1290 AebDrvSetStatus 4;
BA_ "GenSigStartValue" SG_ 1290 AebDrvSetStatus 2;
BA_ "GenMsgCycleTime" BO_ 1362 100;
BA_ "GenSigStartValue" SG_ 273 G_SEL_DISP 9;
BA_ "GenSigStartValue" SG_ 273 TQI_TCU 255;
BA_ "GenSigStartValue" SG_ 273 TEMP_AT 255;
BA_ "GenSigStartValue" SG_ 274 ETL_TCU 255;
BA_ "GenSigStartValue" SG_ 274 SPK_RTD_TCU 255;
BA_ "GenSigStartValue" SG_ 275 N_TGT_LUP 255;
BA_ "GenSigStartValue" SG_ 275 SLOPE_TCU 32;
BA_ "GenMsgCycleTime" BO_ 1282 100;
BA_ "GenSigStartValue" SG_ 1282 CF_Tcu_StRelStat 1;
BA_ "GenMsgCycleTime" BO_ 1356 200;
BA_REL_ "GenSigTimeoutTime" BU_SG_REL_ CLU SG_ 1356 Vehicle_Stop_Time 0;
BA_REL_ "GenSigTimeoutTime" BU_SG_REL_ CLU SG_ 1356 HILL_HOLD_WARNING 0;
VAL_ 1064 _4WD_TYPE 0 "Reserved" 1 "Electronic 4WD (FF)" 2 "Electronic 4WD (FR)" 3 "Electric shift 4WD (FR)" ;
VAL_ 1064 _2H_ACT 0 "2H mode is inactive" 1 "2H mode is activated" ;
VAL_ 1064 _4H_ACT 0 "4H mode is inactive" 1 "4H mode is activated" ;
VAL_ 1064 LOW_ACT 0 "LOW mode is inactive" 1 "LOW mode is activated" ;
VAL_ 1064 AUTO_ACT 0 "AUTO mode is inactive" 1 "AUTO mode is activated" ;
VAL_ 1064 LOCK_ACT 0 "LOCK mode is inactive" 1 "LOCK mode is activated" ;
VAL_ 1066 _4WD_STATUS 0 "deactivated" 1 "initialization" 21 "Signal not available" 2 "calibration" 3 "normal operation (torque setting)" 4 "temporary failed (return to normal operation in same running cycle, clutch will be opened, reactivation of ESP requested)" 5 "failed" 6 "failed, clutch open" 7 "failed, position unknown" ;
VAL_ 16 CF_Acu_CshAct 0 "Crash Active time is expired (Crash is Inactive)" 1 "Crash Active time started (Crash Detected)" ;
VAL_ 1280 CF_SWL_Ind 0 "Warning Lamp on" 1 "Warning Lamp off" 2 "Warning Lamp flash" 3 "Not used" ;
VAL_ 1280 CF_TTL_Ind 0 "Telltale Lamp on" 1 "Telltale Lamp off" 2 "Telltale Lamp flash" 3 "Not used" ;
VAL_ 1280 CF_SBR_Ind 0 "SBR Lamp on" 1 "SBR Lamp off" 2 "SBR Lamp flash" 3 "Not used" ;
VAL_ 1345 CF_Gway_IGNSw 0 "Key Off" 1 "Key In" 2 "ACC" 3 "IGN" 4 "Start" 7 "B-CAN signal Time-out" ;
VAL_ 1345 CF_Gway_RKECmd 0 "None" 1 "Lock" 2 "Unlock" 3 "Panic" 4 "Panic Stop" 5 "Trunk(Or Tail Gate)" 6 "Reserved" 7 "Reserved" ;
VAL_ 1345 CF_Gway_DrvKeyLockSw 0 "Off" 1 "lock" ;
VAL_ 1345 CF_Gway_DrvKeyUnlockSw 0 "Off" 1 "Unlock" ;
VAL_ 1345 CF_Gway_DrvDrSw 0 "Close" 1 "Open" 3 "B-CAN signal Time-out" ;
VAL_ 1345 CF_Gway_DrvSeatBeltSw 0 "Unbelted" 1 "Belted" 3 "B-CAN signal Time-out" ;
VAL_ 1345 CF_Gway_TrunkTgSw 0 "Trunk Close" 1 "Trunk Open" 3 "B-CAN signal Time-out" ;
VAL_ 1345 CF_Gway_AstSeatBeltSw 0 "Unbelted" 1 "Belted" 3 "B-CAN signal Time-out" ;
VAL_ 1345 CF_Gway_SMKOption 0 "Non SMK Option" 1 "SMK Option" ;
VAL_ 1345 CF_Gway_HoodSw 0 "Hood Close" 1 "Hood Open" 3 "B-CAN signal Time-out" ;
VAL_ 1345 CF_Gway_TurnSigLh 0 "Off" 1 "On" 3 "B-CAN signal Time-out" ;
VAL_ 1345 CF_Gway_WiperIntT 0 "Step1(SLOW)" 1 "Step2" 2 "Step3" 3 "Step4" 4 "Step5(FAST)" ;
VAL_ 1345 CF_Gway_WiperIntSw 0 "Off" 1 "On" ;
VAL_ 1345 CF_Gway_WiperLowSw 0 "Off" 1 "On" ;
VAL_ 1345 CF_Gway_WiperHighSw 0 "Off" 1 "On" ;
VAL_ 1345 CF_Gway_WiperAutoSw 0 "Off" 1 "On" ;
VAL_ 1345 CF_Gway_RainSnsState 0 "OFF" 1 "Rain Detected" 2 "Low" 3 "High" 4 "Fault 1" 5 "Fault 2" 6 "Fault 3" 7 "Reserved" ;
VAL_ 1345 CF_Gway_HeadLampLow 0 "Off" 1 "On" ;
VAL_ 1345 CF_Gway_HeadLampHigh 0 "Off" 1 "On" ;
VAL_ 1345 CF_Gway_HazardSw 0 "Off" 1 "On" 3 "B-CAN signal Time-out" ;
VAL_ 1345 CF_Gway_AstDrSw 0 "Close" 1 "Open" ;
VAL_ 1345 CF_Gway_DefoggerRly 0 "Off" 1 "On" ;
VAL_ 1345 CF_Gway_ALightStat 0 "OFF" 1 "ON" ;
VAL_ 1345 CF_Gway_LightSwState 0 "Light Sw Off" 1 "Tail Sw On" 2 "HeadLamp Low Sw On" 3 "AutoLight Sw On" ;
VAL_ 1345 CF_Gway_Frt_Fog_Act 0 "OFF" 1 "ON" ;
VAL_ 1345 CF_Gway_TSigRHSw 0 "Off" 1 "On" ;
VAL_ 1345 CF_Gway_TSigLHSw 0 "Off" 1 "On" ;
VAL_ 1345 CF_Gway_DriveTypeOption 0 "LHD" 1 "RHD" ;
VAL_ 1345 CF_Gway_StarterRlyState 0 "Starter Relay Output Off" 1 "Starter Relay Output On" ;
VAL_ 1345 CF_Gway_PassiveAccessLock 0 "None" 1 "Lock" 2 "PassiveTrunkLock" ;
VAL_ 1345 CF_Gway_WiperMistSw 0 "Off" 1 "On" ;
VAL_ 1345 CF_Gway_PassiveAccessUnlock 0 "None" 1 "UnLock" 2 "Unlock only DRV Door" 3 "PIC_Key_Reminder" ;
VAL_ 1345 CF_Gway_RrSunRoofOpenState 0 "Close" 1 "Open" ;
VAL_ 1345 CF_Gway_PassingSW 0 "SW Off" 1 "SW On" ;
VAL_ 1345 CF_Gway_HBAControlMode 0 "HLamp High Control Mode by BCM" 1 "HLamp High Control Mode by HBA" ;
VAL_ 1345 CF_Gway_HLpHighSw 0 "Off" 1 "On" ;
VAL_ 1345 CF_Gway_InhibitRMT 0 "Gear_R Switch Off" 1 "Gear_R Switch On" 3 "B-CAN signal Time-out" ;
VAL_ 1345 CF_Gway_RainSnsOption 0 "Non Rain Sensor Option" 1 "Rain Sensor Option" ;
VAL_ 1345 C_SunRoofOpenState 0 "close" 1 "open" ;
VAL_ 1345 CF_Gway_Ign1 0 "IGN1 Off" 1 "IGN1 On" ;
VAL_ 1345 CF_Gway_Ign2 0 "IGN2 Off" 1 "IGN2 On" ;
VAL_ 1345 CF_Gway_ParkBrakeSw 0 "Off" 1 "On" 3 "B-CAN signal Time-out" ;
VAL_ 1345 CF_Gway_TurnSigRh 0 "Off" 1 "On" 3 "B-CAN signal Time-out" ;
VAL_ 1312 CF_Hoodsw_memory 0 "no event" 1 "hood open->close" 2 "reserved" 3 "reserved" ;
VAL_ 1040 CF_Gway_ATTurnRValue 0 "Default Value" 1 "Auto Triple Turn Off" 2 "Auto Triple Turn On" 3 "Invalid" ;
VAL_ 1040 CF_Gway_PTGMRValue 0 "Default Value" 1 "Power Mode" 2 "Manual Mode" 3 "Invalid" ;
VAL_ 1040 CF_Gway_EscortHLRValue 0 "Default Value" 1 "Escort Off" 2 "Escort On" 3 "Invalid" ;
VAL_ 1040 CF_Gway_TTUnlockRValue 0 "Default" 1 "Ttunlock Off" 2 "Ttunlock On" 3 "Invalid" ;
VAL_ 1040 CF_Gway_ADrLRValue 0 "Default Value" 1 "Off" 2 "Vehicle Speed On(15km)" 3 "Shift Lever On" 4 "Invalid" ;
VAL_ 1040 CF_Gway_ADrURValue 0 "Default" 1 "Off" 2 "Key Out On" 3 "Shift Lever On" 4 "Override" 5 "Invalid" ;
VAL_ 1040 CF_Gway_SCMRValue 0 "Default" 1 "Steering Off" 2 "Steering On" 3 "Invalid" ;
VAL_ 1040 CF_Gway_WlightRValue 0 "Default Value" 1 "Welcome Light Off" 2 "Welcome Light On" 3 "Invalid" ;
VAL_ 1040 CF_Gway_PSMRValue 0 "Default Value" 1 "Off (Disable)" 2 "50mmOn (Enable)" 3 "75mmOn (Enable)" 4 "Reserved" 5 "Reserved" 6 "Reserved" 7 "Invalid" ;
VAL_ 1040 CF_Gway_OTTurnRValue 0 "Default" 1 "One Touch Turn Off" 2 "3 Flashing" 3 "5 Flashing" 4 "7 Flashing" 5 "Invalid" ;
VAL_ 1040 CF_Gway_DrLockSoundRValue 0 "Default" 1 "Disable" 2 "Enable" 3 "Invalid" ;
VAL_ 1040 CF_Gway_HAnBRValue 0 "Default Value" 1 "Arm Disarm Buzzer Off" 2 "Arm Disarm Buzzer On" 3 "Invalid" ;
VAL_ 1040 CF_Gway_MoodLpRValue 0 "Default Value" 1 "Mood Lamp Off" 2 "Mood Lamp On" 3 "Invalid" ;
VAL_ 1040 CF_Gway_HfreeTrunkRValue 0 "Default Value" 1 "HandsFree Off" 2 "HandsFree On" 3 "Reserve" 4 "Invalid" ;
VAL_ 1040 CF_Gway_AutoLightRValue 0 "Default Value" 1 "Bright" 2 "Normal" 3 "Overcast" 4 "Invalid" ;
VAL_ 1040 CF_Gway_RearWiperRValue 0 "Default Value" 1 "Rear Wiper(reverse) Off" 2 "Rear Wiper(reverse) On" 3 "Invalid" ;
VAL_ 1040 CF_Gway_PasSpkrLvRValue 0 "Default" 1 "Level 1" 2 "Level 2" 3 "Level 3" 4 "Reserved" 5 "Reserved" 6 "Reserved" 7 "Invalid (Error Value)" ;
VAL_ 1313 C_DRVDoorStatus 0 "Close" 1 "Open" 2 "reserved" 3 "Invalid" ;
VAL_ 1313 C_ASTDoorStatus 0 "Close" 1 "Open" 2 "reserved" 3 "Invalid" ;
VAL_ 1313 C_RLDoorStatus 0 "Close" 1 "Open" 2 "reserved" 3 "Invalid" ;
VAL_ 1313 C_RRDoorStatus 0 "Close" 1 "Open" 2 "reserved" 3 "Invalid" ;
VAL_ 1313 C_TrunkStatus 0 "Closed" 1 "Opened" 2 "reserved" 3 "Invalid" ;
VAL_ 1313 C_OSMirrorStatus 0 "Stop" 1 "Fold" 2 "Unfold" 3 "Invalid" ;
VAL_ 1316 C_ADrLUNValueConf 0 "Default" 1 "Set new value" 2 "not used" 3 "Invalid" ;
VAL_ 1316 C_TwUnNValueConf 0 "Default" 1 "Set new value" 2 "not used" 3 "Invalid" ;
VAL_ 1316 C_AlarmNValueConf 0 "Default" 1 "Set new value" 2 "not used" 3 "Invalid" ;
VAL_ 1316 C_PSMNValueConf 0 "Default" 1 "Set new value" 2 "not used" 3 "Invalid" ;
VAL_ 1316 C_SCMNValueConf 0 "Default" 1 "Set new value" 2 "not used" 3 "Invalid" ;
VAL_ 1316 C_HLEscortNValueConf 0 "Default" 1 "Set new value" 2 "not used" 3 "Invalid" ;
VAL_ 1316 C_WELNValueConf 0 "Default" 1 "Set new value" 2 "not used" 3 "Invalid" ;
VAL_ 1316 C_TriTurnLNValueConf 0 "Default" 1 "Set new value" 2 "not used" 3 "Invalid" ;
VAL_ 1317 C_ADrLRValue 0 "Default" 1 "Off" 2 "Vehicle Speed On" 3 "Shift Lever On" 4 "reserved" 5 "reserved" 6 "reserved" 7 "Invalid" ;
VAL_ 1317 C_ADrURValue 0 "Default" 1 "Off" 2 "Key Out On" 3 "Shift Lever On" 4 "Override" 5 "reserved" 6 "reserved" 7 "Invalid" ;
VAL_ 1317 C_TwUnRValue 0 "Default" 1 "Twice Unlock Off" 2 "Twice Unlock On" 3 "Invalid" ;
VAL_ 1317 C_ABuzzerRValue 0 "Default" 1 "Answer Buzzer Off" 2 "Answer Buzzer On" 3 "Invalid" ;
VAL_ 1317 C_ArmWKeyRValue 0 "Default" 1 "Alarm with Key Off" 2 "Alarm with Key On" 3 "Invalid" ;
VAL_ 1317 C_PSMRValue 0 "Default" 1 "Easy Seat Access Off" 2 "Easy Seat Access On" 3 "Invalid" ;
VAL_ 1317 C_SCMRValue 0 "Default" 1 "Easy Steering Access Off" 2 "Easy Steering Access On" 3 "Invalid" ;
VAL_ 1317 C_HLEscortRValue 0 "Default" 1 "Head Lamp Escort Off" 2 "Head Lamp Escort On" 3 "Invalid" ;
VAL_ 1317 C_WELRValue 0 "Default" 1 "Welcome Light Off" 2 "Welcome Light On" 3 "Invalid" ;
VAL_ 1317 C_TriTurnLRValue 0 "Default" 1 "One Touch Triple Turn Signal Off" 2 "One Touch Triple Turn Signal On" 3 "Invalid" ;
VAL_ 1314 C_AV_Tail 0 "Off" 1 "On" 2 "not used" 3 "Invalid" ;
VAL_ 1314 C_ParkingBrakeSW 0 "Off" 1 "On" 2 "not used" 3 "Invalid" ;
VAL_ 1314 C_RKECMD 0 "None" 1 "Lock_No1" 2 "Unlock_ No1" 3 "Lock_No2" 4 "Unlock_ No2" 5 "Lock_ No3" 6 "Unlock_No3" 7 "Lock_ No4" 8 "Unlock_No4" 9 "Lock" 10 "Unlock" 15 "invalid" ;
VAL_ 1314 C_BAState 0 "off" 1 "on" 2 "not used" 3 "Invalid" ;
VAL_ 1314 C_IGNSW 0 "KeyOff" 1 "KeyIn" 2 "ACC" 3 "IGN" 4 "Start" 7 "Invalid" ;
VAL_ 1314 C_CountryCfg 0 "DOM" 1 "NA" 2 "EU" 3 "AUS" 4 "CHINA" 5 "GEN, MES" ;
VAL_ 1314 C_TailLampActivity 0 "Default" 1 "OFF" 2 "ON" 3 "Invalid" ;
VAL_ 1314 RearSW_RSELockOnOff 0 "Off" 1 "LockOn" 2 "reserved" 3 "Invalid" ;
VAL_ 1314 C_SMKTeleCrankingState 0 "Default" 1 "Off" 2 "On" 3 "Invalid" ;
VAL_ 1314 C_SMKTeleCrankingFailRes 3 "Invalid" ;
VAL_ 1315 C_ModeSW 0 "off" 1 "Key on" 2 "reserved" 3 "Invalid" ;
VAL_ 1315 C_MuteSW 0 "off" 1 "Key on" 2 "reserved" 3 "Invalid" ;
VAL_ 1315 C_SeekDnSW 0 "off" 1 "Key on" 2 "reserved" 3 "Invalid" ;
VAL_ 1315 C_SeekUpSW 0 "off" 1 "Key on" 2 "reserved" 3 "Invalid" ;
VAL_ 1315 C_BTPhoneCallSW 0 "off" 1 "Key on" 2 "reserved" 3 "Invalid" ;
VAL_ 1315 C_BTPhoneHangUpSW 0 "off" 1 "Key on" 2 "reserved" 3 "Invalid" ;
VAL_ 1315 C_DISCDownSW 0 "off" 1 "Key on" 2 "reserved" 3 "Invalid" ;
VAL_ 1315 C_DISCUpSW 0 "off" 1 "Key on" 2 "reserved" 3 "Invalid" ;
VAL_ 1315 C_SdsSW 0 "off" 1 "Key on" 2 "reserved" 3 "Invalid" ;
VAL_ 1315 C_MTSSW 0 "off" 1 "Key on" 2 "reserved" 3 "Invalid" ;
VAL_ 1315 C_VolDnSW 0 "off" 1 "Key on" 2 "reserved" 3 "Invalid" ;
VAL_ 1315 C_VolUpSW 0 "Lock" 1 "Unlock" 2 "reserved" 3 "Invalid" ;
VAL_ 1078 CF_Gway_PASDisplayFLH 0 "Off" 1 "1st warning" 2 "2nd warning" 3 "3rd warning" 4 "Error" ;
VAL_ 1078 CF_Gway_PASDisplayFRH 0 "Off" 1 "1st warning" 2 "2nd warning" 3 "3rd warning" 4 "Error" ;
VAL_ 1078 CF_Gway_PASRsound 0 "OFF (No warning alarm)" 1 "1st warning" 2 "2nd warning" 3 "3rd warning" ;
VAL_ 1078 CF_Gway_PASDisplayFCTR 0 "Off" 1 "1st warning" 2 "2nd warning" 3 "3rd warning" 4 "Error" ;
VAL_ 1078 CF_Gway_PASDisplayRCTR 0 "Off" 1 "1st warning" 2 "2nd warning" 3 "3rd warning" 4 "Error" 5 "Long warning" ;
VAL_ 1078 CF_Gway_PASFsound 0 "OFF (No warning alarm)" 1 "1st warning" 2 "2nd warning" 3 "3rd warning" ;
VAL_ 1078 CF_Gway_PASDisplayRLH 0 "Off" 1 "1st warning" 2 "2nd warning" 3 "3rd warning" 4 "Error" ;
VAL_ 1078 CF_Gway_PASDisplayRRH 0 "Off" 1 "1st warning" 2 "2nd warning" 3 "3rd warning" 4 "Error" ;
VAL_ 1078 CF_Gway_PASCheckSound 0 "Off" 1 "R_Confirm" 2 "Error" 3 "Reserved" ;
VAL_ 1078 CF_Gway_PASSystemOn 0 "OFF" 1 "ON" 2 "reserved" 3 "reserved" ;
VAL_ 1078 CF_Gway_PASOption 0 "Non" 1 "RPAS" 2 "PAS" 3 "reserved" ;
VAL_ 1078 CF_Gway_PASDistance 0 "Short Distance" 1 "Long Distance" ;
VAL_ 1292 CF_Clu_LowfuelWarn 0 "Low fuel Warning is off" 1 "Low fuel Warning is on" 2 "Not used" 3 "Invalid" ;
VAL_ 1292 CF_Clu_RefDetMod 0 "Non refuel detected" 1 "Refuel detected" ;
VAL_ 1292 CF_Clu_AvgFCU 0 "km/L" 1 "L/100km" 2 "MPG(US)" 3 "MPG(UK)" ;
VAL_ 1292 CF_Clu_AvsmCur 0 "AVSM SYSTEM ON" 1 "AVSM SYSTEM OFF" ;
VAL_ 1292 CF_Clu_DrivingModeSwi 0 "Normal" 1 "Sports" 2 "Snow" 3 "Eco" ;
VAL_ 1292 CF_Clu_FuelDispLvl 0 "Empty" 1 "Level 0" 2 "Level 1" 3 "Level 2" 4 "Level 3" 5 "Level 4" 6 "Level 5" 7 "Level 6" 8 "Level 7" 9 "Level 8" 10 "Level 9" 11 "Level 10" 12 "Level 11" 13 "Level 12" 14 "Level 13" 15 "Level 14" 16 "Level 15" 17 "Level 16" 31 "Invalid (Error)" ;
VAL_ 1292 CF_Clu_FlexSteerSW 0 "Off" 1 "On" ;
VAL_ 1292 CF_Clu_TripUnit 0 "Not Used" 1 "km" 2 "mile" 3 "Invailid" ;
VAL_ 1292 CF_Clu_SWL_Stat 0 "Lamp OFF" 1 "Lamp On" 2 "Lamp Flashing" 3 "ACU message error" 7 "Lamp Circuit Failure" ;
VAL_ 1292 CF_Clu_ActiveEcoSW 0 "Off" 1 "On" ;
VAL_ 1292 CF_Clu_EcoDriveInf 0 "Not Activated" 1 "Green Lamp On" 2 "Yellow Lamp On" 3 "Red Lamp On" 7 "Error" ;
VAL_ 1292 CF_Clu_IsaMainSW 0 "Off" 1 "On" ;
VAL_ 1292 CF_Clu_LdwsLkasSW 0 "Off" 1 "On" ;
VAL_ 1292 CF_Clu_AltLStatus 0 "Off (Low)" 1 "On (Open or High)" ;
VAL_ 1301 CF_Clu_ADrUNValueSet 0 "Default" 1 "Off" 2 "Key Out On" 3 "Shift Lever On" 4 "Override" 5 "Invalid" ;
VAL_ 1301 CF_Clu_ADrLNValueSet 0 "Default" 1 "Off" 2 "Vehicle Speed On(15Km)" 3 "Shift Lever On" 4 "Invalid" ;
VAL_ 1301 CF_Clu_EscortHLNValueSet 0 "Default Value" 1 "Escort Off" 2 "Escort On" 3 "Invalid" ;
VAL_ 1301 CF_Clu_DoorLSNValueSet 0 "Off" 1 "Disable" 2 "Enable" 3 "Invalid" ;
VAL_ 1301 CF_Clu_PSMNValueSet 0 "Default Value" 1 "Off (Disable)" 2 "50mmOn (Enable)" 3 "75mmOn (Enable)" 4 "Reserved" 5 "Reserved" 6 "Reserved" 7 "Invalid" ;
VAL_ 1301 CF_Clu_TTUnlockNValueSet 0 "Default" 1 "Off" 2 "On" 3 "Invalid" ;
VAL_ 1301 CF_Clu_PTGMNValueSet 0 "Default" 1 "Power Mode" 2 "Manual Mode" 3 "Invalid" ;
VAL_ 1301 CF_Clu_SCMNValueSet 0 "Default" 1 "Steering Off" 2 "Steering On" 3 "Invalid" ;
VAL_ 1301 CF_Clu_WlightNValueSet 0 "Default Value" 1 "Welcome Light Off" 2 "Welcome Light On" 3 "Invalid" ;
VAL_ 1301 CF_Clu_TempUnitNValueSet 0 "Off" 1 "Centigrade(¡É)" 2 "Fahrenheit(¢µ)" 3 "Invalid" ;
VAL_ 1301 CF_Clu_MoodLpNValueSet 0 "Default Value" 1 "Mood Lamp Off" 2 "Mood Lamp On" 3 "Mood Lamp Auto" 4 "Invalid" 5 "Reserved" 6 "Reserved" 7 "Reserved" ;
VAL_ 1301 CF_Clu_TrfChgSet 0 "Off" 1 "On" 2 "Invalid" 3 "Invalid" ;
VAL_ 1301 CF_Clu_OTTurnNValueSet 0 "Default" 1 "One Touch Turn Off" 2 "3 Flashing" 3 "5 Flashing" 4 "7 Flashing" 5 "Invalid" 6 "Reserved" 7 "Reserved" ;
VAL_ 1301 CF_Clu_LcaNValueSet 0 "Off" 1 "Disable" 2 "Enable" 3 "Invalid" ;
VAL_ 1301 CF_Clu_RctaNValueSet 0 "Off" 1 "Disable" 2 "Enable" 3 "Invalid" ;
VAL_ 1301 CF_Clu_RcwNValueSet 0 "Off" 1 "Disable" 2 "Enable" 3 "Invalid" ;
VAL_ 1301 CF_Clu_EscOffNValueSet 0 "Default" 1 "Off Mode" 2 "Normal Mode" 3 "Sports Mode" 4 "Reserved" 5 "Reserved" 6 "Reserved" 7 "Invalid" ;
VAL_ 1301 CF_Clu_SccNaviCrvNValueSet 0 "Default" 1 "Disable" 2 "Enable" 3 "Invalid" ;
VAL_ 1301 CF_Clu_SccNaviCamNValueSet 0 "Default" 1 "Disable" 2 "Enable" 3 "Invalid" ;
VAL_ 1301 CF_Clu_SccAebNValueSet 0 "Default" 1 "Disable" 2 "Enable" 3 "Invalid" ;
VAL_ 1301 CF_Clu_LkasModeNValueSet 0 "Default Value" 1 "LDW Mode" 2 "LKA Mode(Pre-Departure)" 3 "LKA Mode(Post_Departure)" ;
VAL_ 1301 CF_Clu_FcwNValueSet 0 "Default" 1 "Disable" 2 "Enable" 3 "Invalid" ;
VAL_ 1301 CF_Clu_PasSpkrLvNValueSet 0 "Default" 1 "Level 1" 2 "Level 2" 3 "Level 3" 4 "Reserved" 5 "Reserved" 6 "Reserved" 7 "Invalid (Error Value)" ;
VAL_ 1301 CF_Clu_SccDrvModeNValueSet 0 "Default" 1 "SCC_Slow" 2 "SCC_Normal" 3 "SCC_Fast" 4 "AEB_Early" 5 "AEB_Normal" 6 "AEB_Late" 7 "Invalid" ;
VAL_ 1301 CF_Clu_HAnBNValueSet 0 "Default" 1 "Arm Disarm Buzzer Off" 2 "Arm Disarm Buzzer On" 3 "Invalid" ;
VAL_ 1301 CF_Clu_HfreeTrunkTgNValueSet 0 "Default" 1 "HandsFree Off" 2 "HandsFree On" 3 "Reserved" 4 "Invalid" ;
VAL_ 1322 CF_Clu_VehicleSpeed 597 "Error" ;
VAL_ 1322 CF_Clu_InhibitP 0 "Off" 1 "(On)P" ;
VAL_ 1322 CF_Clu_InhibitR 0 "Off" 1 "(On)R" ;
VAL_ 1322 CF_Clu_InhibitN 0 "Off" 1 "(On)N" ;
VAL_ 1322 CF_Clu_InhibitD 0 "Off" 1 "(On)D" ;
VAL_ 1322 CF_Clu_HudFontColorSet 0 "White" 1 "Yellow" 2 "Green" 3 "Sky blue" ;
VAL_ 1322 CF_Clu_HudBrightUpSW 0 "OFF(default)" 1 "ON(status1)" 2 "ON(status2)" 3 "Reserved" ;
VAL_ 1322 CF_Clu_HudBrightDnSW 0 "OFF(default)" 1 "ON(status1)" 2 "ON(status2)" 3 "Reserved" ;
VAL_ 1322 CF_Clu_HudHeightUpSW 0 "OFF(default)" 1 "ON(status1)" 2 "ON(status2)" 3 "Reserved" ;
VAL_ 1322 CF_Clu_HudHeightDnSW 0 "OFF(default)" 1 "ON(status1)" 2 "ON(status2)" 3 "Reserved" ;
VAL_ 1322 CF_Clu_HudSet 0 "OFF" 1 "ON" ;
VAL_ 1322 CF_Clu_HudFontSizeSet 0 "Large" 1 "Mid" 2 "Small" 3 "Reserved" ;
VAL_ 1322 CF_Clu_LanguageInfo 0 "Off" 1 "Korean" 2 "English(US)" 3 "English(UK)" 4 "Chinese(Mandarin)" 5 "Chinese(Cantonese)" 6 "French(EU)" 7 "Spanish(EU)" 8 "Arabic" 9 "Czech" 10 "Danish" 11 "German" 12 "Italian" 13 "Dutch" 14 "Polish" 15 "Portuguese" 16 "Russian" 17 "Slovak" 18 "Swedish" 19 "Turkish" 20 "French(US)" 21 "Spanish(US)" 22 "Reserved" 23 "Reserved" 24 "Reserved" 25 "Reserved" 26 "Reserved" 27 "Reserved" 28 "Reserved" 29 "Reserved" 30 "Reserved" 31 "Invalid" ;
VAL_ 1322 CF_Clu_ClusterSound 0 "Cluster applied speaker" 1 "Cluster applied buzzer" ;
VAL_ 1307 CF_Clu_TirePressUnitNValueSet 0 "Default Value" 1 "psi" 2 "kpa" 3 "bar" 4 "Reserved" 5 "Reserved" 6 "Reserved" 7 "Invalid" ;
VAL_ 1307 CF_Clu_SlifNValueSet 0 "Default Value" 1 "Disable" 2 "Enable" 3 "Invalid" ;
VAL_ 1307 CF_Clu_RearWiperNValueSet 0 "Default" 1 "Rear Wiper(reverse) Off" 2 "Rear Wiper(reverse) On" 3 "Invalid" ;
VAL_ 1024 Vehicle_Type 1 "VI F/L Limo" 2 "VI F/L Sedan" 3 "DH" 4 "RK" ;
VAL_ 1318 C_ADrLURValueReq 0 "Off" 1 "Real value Request" 2 "reserved" 3 "Invalid" ;
VAL_ 1318 C_TwUnRValueReq 0 "Off" 1 "Real value Request" 2 "reserved" 3 "Invalid" ;
VAL_ 1318 C_AlarmRValueReq 0 "Off" 1 "Real value Request" 2 "reserved" 3 "Invalid" ;
VAL_ 1318 C_IMSRValueReq 0 "Off" 1 "Real value Request" 2 "reserved" 3 "Invalid" ;
VAL_ 1318 C_HLEscortRValueReq 0 "Off" 1 "Real value Request" 2 "reserved" 3 "Invalid" ;
VAL_ 1318 C_WELRValueReq 0 "Off" 1 "Real value Request" 2 "reserved" 3 "Invalid" ;
VAL_ 1318 C_TriTurnLRValueReq 0 "Off" 1 "Real value Request" 2 "reserved" 3 "Invalid" ;
VAL_ 1318 C_SNVWarnRValueReq 0 "Off" 1 "Real value Request" 2 "reserved" 3 "Invalid" ;
VAL_ 1318 C_LkasWarnRValueReq 0 "Off" 1 "Real value Request" 2 "reserved" 3 "Invalid" ;
VAL_ 1319 C_ADrLNValueSet 0 "Default" 1 "Off" 2 "Vehicle Speed On" 3 "Shift Lever On" 4 "reserved" 5 "reserved" 6 "reserved" 7 "Invalid" ;
VAL_ 1319 C_ADrUNValueSet 0 "Default" 1 "Off" 2 "Key Out On" 3 "Shift Lever On" 4 "Override" 5 "reserved" 6 "reserved" 7 "Invalid" ;
VAL_ 1319 C_TwUnNValueSet 0 "Default" 1 "Twice Unlock Off" 2 "Twice Unlock On" 3 "Invalid" ;
VAL_ 1319 C_ABuzzerNValueSet 0 "Default" 1 "Answer Buzzer Off" 2 "Answer Buzzer On" 3 "Invalid" ;
VAL_ 1319 C_ArmWKeyNValueSet 0 "Default" 1 "Alarm with Key Off" 2 "Alarm with Key On" 3 "Invalid" ;
VAL_ 1319 C_PSMNValueSet 0 "Default" 1 "Easy Seat Access Off" 2 "Easy Seat Access On" 3 "Invalid" ;
VAL_ 1319 C_SCMNValueSet 0 "Default" 1 "Easy Steering Access Off" 2 "Easy Steering Access On" 3 "Invalid" ;
VAL_ 1319 C_HLEscortNValueSet 0 "Default" 1 "Head Lamp Escort Off" 2 "Head Lamp Escort On" 3 "Invalid" ;
VAL_ 1319 C_WELNValueSet 0 "Default" 1 "Welcome Light Off" 2 "Welcome Light On" 3 "Invalid" ;
VAL_ 1319 C_TriTurnLNValueSet 0 "Default" 1 "One Touch Triple Turn Signal Off" 2 "One Touch Triple Turn Signal On" 3 "Invalid" ;
VAL_ 1319 C_SNVWarnNValueSet 0 "Default" 1 "Smart Night View Off" 2 "Smart Night View On" 3 "Invalid" ;
VAL_ 1319 C_LkasWarnNValueSet 0 "Default" 1 "LKAS Warning Off" 2 "LKAS Warning On" 3 "Invalid" ;
VAL_ 1338 CF_Gway_TeleReqDrLock 0 "Off" 1 "On" 2 "Not Used" 3 "Invalid" ;
VAL_ 1338 CF_Gway_TeleReqDrUnlock 0 "Off" 1 "On" 2 "Not Used" 3 "Invalid" ;
VAL_ 1338 CF_Gway_TeleReqHazard 0 "Off" 1 "On" 2 "Not Used" 3 "Invalid" ;
VAL_ 1338 CF_Gway_TeleReqHorn 0 "Off" 1 "On" 2 "Not Used" 3 "Invalid" ;
VAL_ 1338 CF_Gway_TeleReqEngineOperate 0 "Default" 1 "Cranking" 2 "Stop" 3 "Invalid" ;
VAL_ 68 CR_Datc_OutTempC 0 "Blank Display" 1 "Blank Display" 254 "Sensor Fail ( - - Display )" 255 "Invalid" ;
VAL_ 68 CR_Datc_OutTempF 0 "Blank Display" 1 "Blank Display" 254 "Sensor Fail ( - - Display )" 255 "Invalid" ;
VAL_ 68 CF_Datc_IncarTemp 255 "Error identifier" ;
VAL_ 66 CR_Datc_DrTempDispC 0 "Blank Display" 1 "Blank Display" 255 "Invalid" ;
VAL_ 66 CR_Datc_DrTempDispF 0 "Blank Display" 1 "Blank Display" 255 "Invalid" ;
VAL_ 66 CR_Datc_PsTempDispC 0 "Blank Display" 1 "Blank Display" 255 "Invalid" ;
VAL_ 66 CR_Datc_PsTempDispF 0 "Blank Display" 1 "Blank Display" 255 "Invalid" ;
VAL_ 66 CR_Datc_RearDrTempDispC 0 "Blank Display" 1 "Blank Display" 255 "Invalid" ;
VAL_ 66 CR_Datc_RearDrTempDispF 0 "Blank Display" 1 "Blank Display" 255 "Invalid" ;
VAL_ 66 CF_Datc_CO2_Warning 0 "Off" 1 "On (CO2 Warning)" 2 "Not used" 3 "Invalid" ;
VAL_ 67 CF_Datc_TempDispUnit 0 "Centigrade(¡É)" 1 "Fahrenheit(¢µ)" ;
VAL_ 67 CF_Datc_ModDisp 0 "OFF" 1 "VENT" 2 "B/L" 3 "FLOOR" 4 "MIX" 5 "DEF" 6 "AUTO Defog" ;
VAL_ 67 CF_Datc_IonClean 0 "OFF" 1 "CLEAN" 2 "ION" 3 "Invalid" ;
VAL_ 67 CF_Datc_ChgReqDisp 0 "OFF" 1 "User Input" 2 "Not used" 3 "Invalid" ;
VAL_ 67 CF_Datc_IntakeDisp 0 "REC Off (Fresh On)" 1 "REC ON (Fresh Off)" 2 "Not used" 3 "Invalid" ;
VAL_ 67 CF_Datc_AutoDisp 0 "AUTO Off" 1 "AUTO On" 2 "Not used" 3 "Invalid" ;
VAL_ 67 CF_Datc_FrDefLed 0 "Off" 1 "On" 2 "Not used" 3 "Invalid" ;
VAL_ 67 CF_Datc_AutoDefogBlink 0 "Off" 1 "AutoDefogBlink Request" 2 "Not used" 3 "Invalid" ;
VAL_ 67 CF_Datc_ClmScanDisp 0 "Deactived" 1 "Actived" 2 "Not used" 3 "Invalid" ;
VAL_ 67 CF_Datc_AqsDisp 0 "AQS Off" 1 "AQS ON" 2 "Not used" 3 "Invalid" ;
VAL_ 67 CF_Datc_AcDisp 0 "A/C Off" 1 "A/C ON" 2 "Not used" 3 "Invalid" ;
VAL_ 67 CF_Datc_OpSts 0 "DATC Off (Power Down)" 1 "DATC Normal" 2 "DATC System Off (Blower Off)" 3 "DATC Self Diagnosis" 4 "Not used" 5 "Not used" 6 "Not used" 7 "Invalid" ;
VAL_ 67 CF_Mtc_MaxAcDisp 0 "Off" 1 "On" 2 "Not used" 3 "Invalid" ;
VAL_ 67 CF_Datc_DualDisp 0 "DUAL Off" 1 "DUAL On" 2 "Not used" 3 "Invalid" ;
VAL_ 67 CF_Datc_PwrInf 0 "Off" 1 "Not used" 2 "Not used" 3 "IGN(Ignition2)" ;
VAL_ 67 CF_Datc_RearManual 0 "Off" 1 "Rear Enable" 2 "Rear Disable" 3 "Invalid" ;
VAL_ 67 CF_Datc_RearAutoDisp 0 "AUTO Off" 1 "AUTO On" 2 "Not Used" 3 "Invalid" ;
VAL_ 67 CF_Datc_RearOffDisp 0 "off" 1 "Normal Mode" 2 "¡°OFF¡± Display" 3 "Invalid" ;
VAL_ 67 CF_Datc_RearClimateScnDisp 0 "Deactived" 1 "Actived" 2 "Not Used" 3 "Invalid" ;
VAL_ 67 CF_Datc_RearChgReqDisp 0 "OFF" 1 "USER INPUT" 2 "Not Used" 3 "Invalid" ;
VAL_ 67 CF_Datc_RearModDisp 0 "OFF" 1 "VENT" 2 "B/L" 3 "FLOOR" ;
VAL_ 67 CF_Datc_RearBlwDisp 0 "Off" 1 "0 Level" 2 "1 Level" 3 "2 Level" 4 "3 Level" 5 "4 Level" 6 "5 Level" 7 "6 Level" 8 "7 Level" 9 "8 Level" 15 "Invalid" ;
VAL_ 67 CF_Datc_PSModDisp 0 "OFF" 1 "VENT" 2 "B/L" 3 "FLOOR" 4 "MIX" 5 "DEF" 6 "AUTO Defog" ;
VAL_ 67 CF_Datc_FrontBlwDisp 0 "Off" 1 "0 Level" 2 "1 Level" 3 "2 Level" 4 "3 Level" 5 "4 Level" 6 "5 Level" 7 "6 Level" 8 "7 Level" 9 "8 Level" 15 "Invalid" ;
VAL_ 64 CF_Datc_AqsLevelOut 0 "OFF" 1 "1 LEVEL" 2 "2 LEVEL" 3 "3 LEVEL" 4 "4 LEVEL" 5 "5 LEVEL" 6 "Not Used" 7 "Not Used" 8 "Not Used" 9 "Not Used" 10 "Not Used" 11 "Not Used" 12 "Not Used" 13 "Not Used" 14 "Not Used" 15 "Invalid" ;
VAL_ 64 CF_Datc_DiagMode 0 "Off" 1 "Diagnosis Code Display" 2 "Not used" 3 "Invalid" ;
VAL_ 64 CR_Datc_SelfDiagCode 0 "Blank Display" 255 "Invalid" ;
VAL_ 64 DATC_SyncDisp 0 "initial" 1 "Sync ON" 2 "Sync OFF" 3 "reserved" 4 "reserved" 5 "reserved" 6 "reserved" 7 "reserved" 8 "reserved" 9 "reserved" 10 "reserved" 11 "reserved" 12 "reserved" 13 "reserved" 14 "reserved" 15 "invaild" ;
VAL_ 64 DATC_OffDisp 0 "OFF" 1 "Normal Display" 2 "OFF Display" 3 "invalid" ;
VAL_ 64 DATC_SmartVentDisp 0 "Off" 1 "Smart Ventilation" 2 "Smart CO2" 3 "invalid" ;
VAL_ 64 DATC_SmartVentOnOffStatus 1 "Function Off" 2 "Function On" 3 "reverved" 4 "invalid" ;
VAL_ 64 DATC_AutoDefogSysOff_Disp 0 "ADS SYSTEM OFF" 1 "ADS SYSTEM ON" 2 "Not used" 3 "invalid" ;
VAL_ 64 DATC_ADSDisp 0 "ADS Deactivated" 1 "ADS Activated" 2 "reserved" 3 "Invalid" ;
VAL_ 1350 CF_DiBox_SedInjVChg 0 "NO ERROR" 1 "ERROR" ;
VAL_ 1350 CF_DiBox_FrtInjVChg 0 "NO ERROR" 1 "ERROR" ;
VAL_ 1350 CF_DiBox_SedInjVErrSPI 0 "NO ERROR" 1 "ERROR" ;
VAL_ 1350 CF_DiBox_FrtInjVErrSPI 0 "NO ERROR" 1 "ERROR" ;
VAL_ 1281 ECS_W_LAMP 0 "Off" 1 "On" ;
VAL_ 1281 SYS_NA 0 "System available" 1 "System temporary not available" ;
VAL_ 1281 ECS_DEF 0 "ECS is not defective" 1 "ECS is defective" ;
VAL_ 1281 ECS_DIAG 0 "ECS is not diagnosis states" 1 "ECS is diagnosis states" ;
VAL_ 1281 L_CHG_NA 0 "-" 1 "Height level change not available" ;
VAL_ 1281 Leveling_Off 0 "Leveling control active (normal)" 1 "Leveling control deactivated by user" ;
VAL_ 1281 LC_overheat 0 "Normal" 1 "System is overheated (cooling in progress)" ;
VAL_ 1281 Lifting 0 "no change of level" 1 "raising" ;
VAL_ 1281 Lowering 0 "no change of level" 1 "lowering" ;
VAL_ 1281 Damping_Mode 0 "Auto" 1 "Soft" 2 "Hard" 3 "Reserved" ;
VAL_ 1281 REQ_Damping 0 "Auto" 1 "Soft" 2 "Hard" 3 "Reserved" ;
VAL_ 1281 REQ_Height 0 "No Manual Switch input" 1 "Normal" 2 "High" 3 "Low" ;
VAL_ 1281 REQ_level 3 "Low" 4 "Highway" 5 "Normal" 6 "Off-road" 7 "High" ;
VAL_ 1281 ACT_Height 3 "Low" 4 "Highway" 5 "Normal" 6 "Off-road" 7 "High" ;
VAL_ 1353 BAT_SNSR_State 0 "normal state" 1 "implausible state" ;
VAL_ 1353 BAT_SNSR_Invalid 0 "Valid Condition" 1 "Invalid Condition" ;
VAL_ 1353 BAT_SNSR_Error 0 "operating correctly" 1 "response error" ;
VAL_ 790 SWI_IGK 0 "KEY OFF, control unit in self-holding phase" 1 "KEY ON" ;
VAL_ 790 F_N_ENG 0 "No error" 1 "Engine speed sensor defective" ;
VAL_ 790 ACK_TCS 0 "TCS message not received within the last 500 ms, or a plausibility error in torque intervention is ON" 1 "TCS message received, and no plausibility error" ;
VAL_ 790 PUC_STAT 0 "Engine not in fuel cut off" 1 "Engine in fuel cut off" ;
VAL_ 790 TQ_COR_STAT 0 "The desired intervention regarding ignition angle retardation and cylinder shut-off is executed. (Default value)" 1 "The desired intervention regarding ignition angle retardation and cylinder shut-off is executed; however, the requested target torque can not be adjusted precisely (torque steps)" 2 "The torque reduction regarding the ignition angle retardation cannot be completely executed. A cylinder shut-off is not possible at this time. Therefore a remaining torque (as difference between TQI_ASR/GS_REQ and TQI_INTV) is present and cannot be reduced." 3 "Due to a failure detected by a diagnosis function of the engine management system, the desired torque intervention for TCS regarding the ignition angle and cylinder shut-off is no longer executed.The torque intervention is terminated, the engine management system resets the requested engine torque to the TQI value using a ramp." ;
VAL_ 790 RLY_AC 0 "Air conditioner compressor relay OFF" 1 "Air conditioner compressor relay ON" ;
VAL_ 790 F_SUB_TQI 0 "No error" 1 "Error on Torque Measurement" ;
VAL_ 809 CONF_TCU 0 "A/T vehicle (Step Shift A/T)" 10 "CVT vehicle (CVT A/T)" 11 "DCT vehicle (DCT A/T)" 15 "M/T vehicle" ;
VAL_ 809 MUL_CODE 0 "CAN_VERS" 1 "CONF_TCU" 2 "OBD_FRF_ACK" 3 "TQ_STND" ;
VAL_ 809 VB_OFF_ACT 0 "no battery disconnection detected" 1 "battery disconnection detected and failure memory erased" ;
VAL_ 809 ACK_ES 0 "No acknowledgement" 1 "Acknowledgement engine stopped" ;
VAL_ 809 CONF_MIL_FMY 0 "no MIL, Failure Memory Management OBD-I" 1 "MIL Treatment OBD-I, Failure Memory Management OBD-I" 2 "MIL Treatment OBD-II, Exception" 3 "MIL Treatment OBD-II, Failure Memory Management OBD-II" 4 "MIL Treatment E-OBD, Failure Memory Management E-OBD" 5 "MIL Treatment K-OBD, Failure Memory Management K-OBD" ;
VAL_ 809 OD_OFF_REQ 0 "Normal operation" 1 "Over drive off request to TCU by the cruise control function" ;
VAL_ 809 ACC_ACT 0 "Auto cruise control is not active" 1 "Auto cruise control is active" ;
VAL_ 809 CLU_ACK 0 "Clutch is not operating" 1 "Clutch is operating" ;
VAL_ 809 BRAKE_ACT 0 "EMS does not support this function." 1 "Brake switch is not pressed (OFF)" 2 "Brake switch is pressed (ON)" 3 "Brake switch failure" ;
VAL_ 809 ENG_CHR 0 "Fuel - Gasoline,  ETC - No" 1 "Fuel - LPI(LPG),  ETC - No" 2 "Fuel - Diesel,     ETC - No" 3 "Reserved" 4 "Fuel - Gasoline,  ETC - Applied" 5 "Fuel - LPI(LPG),  ETC - Applied" 6 "Fuel - Diesel,    ETC - Applied" 7 "GDI type engine" ;
VAL_ 809 GP_CTL 0 "Glow plug off request" 1 "Glow plug on request" 2 "System Error" 3 "Reserved" ;
VAL_ 809 TPS 32 "Idle (port value is learnt)" 245 "Throttle perpendicular" 255 "Throttle defective" ;
VAL_ 809 PV_AV_CAN 0 "Accelerator Pedal not activated" 254 "Accelerator Pedal fully activated" 255 "Accelerator Pedal is defective (fail state) orNon-ETC system (APS is not installed)" ;
VAL_ 1349 IMMO_LAMP_STAT 0 "Immobilizer lamp OFF" 1 "Immobilizer lamp ON" ;
VAL_ 1349 L_MIL 0 "Check Engine lamp OFF" 1 "Check Engine lamp ON" ;
VAL_ 1349 IM_STAT 0 "Immobilizer active" 1 "Immobilizer passive" ;
VAL_ 1351 ECGPOvrd 0 "No Driver Override" 1 "Driver Override" ;
VAL_ 1351 QECACC 0 "No Failure detected" 1 "Failure detected" ;
VAL_ 1351 ECFail 0 "No Failure detected" 1 "Failure detected" ;
VAL_ 1351 SwitchOffCondExt 0 "No switch off condition detected" 1 "Switch off condition detected" ;
VAL_ 1351 BLECFail 0 "No Failure detected" 1 "Failure detected" ;
VAL_ 1351 CF_Ems_IsaAct 0 "ISA function is not active" 1 "ISA function is active" ;
VAL_ 1351 FA_PV_CAN 0 "Accelerator Pedal not activated" 254 "Accelerator Pedal fully activated" 255 "Accelerator Pedal is defective (fail state) orNon-ETC system (APS is not installed)" ;
VAL_ 1351 INH_DC_OBD 0 "Enable of standardized vehicle operation and all numerators/denominators for RBM" 1 "Inhibition of standardized vehicle operation and all numerators/denominators for RMB" ;
VAL_ 512 Split_Stat 0 "Split injection OFF" 1 "Split injection ON" ;
VAL_ 544 LAT_ACCEL_STAT 0 "Lateral acceleration signal is valid" 1 "Lateral acceleration signal is invalid" ;
VAL_ 544 LAT_ACCEL_DIAG 0 "Lateral acceleration signal is available" 1 "Lateral acceleration signal is not available temporarily" ;
VAL_ 544 LONG_ACCEL_STAT 0 "Longitudinal acceleration signal is valid" 1 "Longitudinal acceleration signal is invalid" ;
VAL_ 544 LONG_ACCEL_DIAG 0 "Longitudinal acceleration signal is available" 1 "Longitudinal acceleration signal is not available temporarily" ;
VAL_ 544 CYL_PRES_STAT 0 "Master cylinder pressure signal is valid" 1 "Master cylinder pressure signal is invalid" ;
VAL_ 544 CYL_PRESS_DIAG 0 "Master cylinder pressure signal is available" 1 "Master cylinder pressure is not available temporarily" ;
VAL_ 544 YAW_RATE_STAT 0 "Yaw rate sensor signal is valid" 1 "Yaw rate sensor signal is invalid" ;
VAL_ 544 YAW_RATE_DIAG 0 "Yaw rate signal is available" 1 "Yaw rate signal is not available temporarily" ;
VAL_ 339 TCS_REQ 0 "Passive" 1 "TCS/ESC control active" ;
VAL_ 339 MSR_C_REQ 0 "Passive or TCS function" 1 "MSR control active" ;
VAL_ 339 TCS_PAS 1 "TCS is disabled by user" ;
VAL_ 339 TCS_GSC 0 "passive (gear change allowed)" 1 "active (gear change not allowed)" ;
VAL_ 339 CF_Esc_LimoInfo 0 "Invalid" 1 "Invalid" 2 "Vehicle is not Limo" 3 "Vehicle is Limo" ;
VAL_ 339 ABS_DIAG 0 "ABS/TCS/ESC is not diagnostic mode" 1 "ABS/TCS/ESC is diagnostic mode" ;
VAL_ 339 ABS_DEF 0 "ABS is not defective" 1 "ABS is defective" ;
VAL_ 339 TCS_DEF 1 "TCS is defective (failed)" ;
VAL_ 339 TCS_CTL 1 "TCS Active" ;
VAL_ 339 ABS_ACT 0 "ABS control inactive" 1 "ABS control active" ;
VAL_ 339 EBD_DEF 0 "EBD is not defective" 1 "EBD is defective" ;
VAL_ 339 ESP_PAS 1 "ESC disabled by user (SW off)" ;
VAL_ 339 ESP_DEF 1 "ESC is defective (failed)" ;
VAL_ 339 ESP_CTL 1 "ESC active" ;
VAL_ 339 TCS_MFRN 0 "Using both TQI_TCS and TQI_SLW_TCS" 1 "Using TQI_TCS only (Not using TQI_SLW_TCS)" ;
VAL_ 339 DBC_CTL 1 "DBC is Active" ;
VAL_ 339 DBC_PAS 1 "DBC is stand by (SW ON)" ;
VAL_ 339 DBC_DEF 1 "DBC is defective (failed)" ;
VAL_ 339 HAC_CTL 1 "HAC is Active" ;
VAL_ 339 HAC_PAS 1 "HAC is stand by (SW ON) If SW is applied" ;
VAL_ 339 HAC_DEF 1 "HAC is defective (failed)" ;
VAL_ 339 ESS_STAT 0 "ESS control ¡°inactive¡± (Normal condition)" 1 "ESS control ¡°active¡± (Emergency stop condition)" 2 "ESS system is defective" 3 "ESS extended function active (Hazard lamp blinking)" ;
VAL_ 339 CF_Esc_BrkCtl 0 "Brake control is not in activation" 1 "Brake control is in activation" ;
VAL_ 339 BLA_CTL 0 "No request" 1 "Activate brake lights" 2 "Reserved" 3 "Reserved" ;
VAL_ 1287 ABS_W_LAMP 0 "ABS Warning lamp OFF" 1 "ABS Warning lamp ON" ;
VAL_ 1287 TCS_OFF_LAMP 0 "TCS/ESC OFF SW Lamp OFF" 1 "TCS/ESC OFF SW Lamp ON" ;
VAL_ 1287 TCS_LAMP 0 "TCS/ESC Function/Warning Lamp OFF" 1 "TCS/ESC Function/Warning Lamp ON" 2 "TCS/ESC Function/Warning Lamp BLINKING(2Hz)" 3 "Reserved" ;
VAL_ 1287 DBC_W_LAMP 0 "DBC Warning lamp OFF" 1 "DBC Warning lamp ON" ;
VAL_ 1287 DBC_F_LAMP 0 "DBC Function lamp OFF" 1 "DBC Function lamp ON" 2 "DBC Function lamp BLINKING(2Hz)" 3 "Reserved" ;
VAL_ 1287 ESC_Off_Step 0 "Normal Mode" 1 "Sports Mode" 2 "Off Mode" 3 "ESC OFF SW is defective (failed)" ;
VAL_ 1287 AVH_CLU 0 "AVH is off" 1 "AUTO HOLD to be deactivated Press Brake Pedal" 2 "Press Brake Pedal to Release AUTO HOLD" 3 "AUTO HOLD cannot be activated Close Door, Hood, Trunk" ;
VAL_ 1287 AVH_I_LAMP 0 "Lamp On" 1 "Lamp Off" 2 "Reserved" 3 "Reserved" ;
VAL_ 1287 EBD_W_LAMP 0 "EBD Warning lamp OFF" 1 "EBD Warning lamp ON" ;
VAL_ 1287 AVH_ALARM 0 "No alarm" 1 "On AVH Activation, Vehicle is not secured and driver is still inside = comfortable tone" ;
VAL_ 1287 AVH_LAMP 0 "AVH Off (Lamp Status" 1 "AVH failure (Lamp Status" 2 "AVH ACTIVE (Lamp Status" 3 "AVH READY (Lamp Status" 4 "Lamp Status" 5 "Lamp Status" 6 "Lamp Status" ;
VAL_ 1360 CF_Iap_EcoPmodSwi 0 "ECO-P switch is off" 1 "ECO-P switch is on" ;
VAL_ 1360 CF_Iap_EcoPmodAct 0 "ECO-P mode is inactive" 1 "ECO-P mode is active" ;
VAL_ 1360 CF_Iap_ReqWarn 0 "None" 1 "ECO warning" 2 "LDW warning" 3 "VSM warning" ;
VAL_ 832 CF_Lkas_LdwsSysState 0 "System OFF" 1 "Low Vehicle Speed" 2 "System Unavailable" 3 "Mode 1 ? MDPS Control" 4 "Mode 2 Full Lane" 5 "Mode 2 Left Line" 6 "Mode 2 Right Line" 14 "System Not Calibrated" 15 "System Failure" ;
VAL_ 832 CF_Lkas_SysWarning 0 "No Info" 1 "Missing Lane Marking" 2 "Wiper High Unavailable" 3 "Out-of-Control State" 4 "Hands-Off Warning" 7 "Camera Internal Failure" ;
VAL_ 832 CF_Lkas_LdwsLHWarning 0 "No Warning" 1 "HAPTIC Warning and Display" 2 "Acoustic Warning and Display" ;
VAL_ 832 CF_Lkas_LdwsRHWarning 0 "No Warning" 1 "HAPTIC Warning and Display" 2 "Acoustic Warning and Display" ;
VAL_ 832 CF_Lkas_HbaLamp 0 "HBA Indicator Lamp Off" 1 "HBA Indicator Lamp On" ;
VAL_ 832 CF_Lkas_FcwBasReq 0 "FCWS BAS READY (Default)" 1 "FCW BAS ACT" ;
VAL_ 832 CF_Lkas_ActToi 0 "De-activate TOI" 1 "Activate TOI" ;
VAL_ 832 CF_Lkas_ToiFlt 0 "No Fault" 1 "Fault Present" ;
VAL_ 832 CF_Lkas_HbaSysState 0 "None(HBA off)" 1 "HBA On & High Bean Off" 2 "HBA On & High Bean On" 7 "System Fail" ;
VAL_ 832 CF_Lkas_FcwOpt 0 "None FCW Option" 1 "System Disable by USM" 2 "System Enable by USM" ;
VAL_ 832 CF_Lkas_HbaOpt 0 "None HBA Option (Default)" 1 "HBA System Enable" ;
VAL_ 832 CF_Lkas_FcwSysState 0 "System Off" 1 "System On(Unrecognition of vehicle)" 2 "System On(Recognition of vehicle)" 3 "System On(Collision Warning)" 7 "System Fail" ;
VAL_ 832 CF_Lkas_FcwCollisionWarning 0 "No warning" 1 "First step collision warning" 2 "Second step collision warning" ;
VAL_ 832 CF_Lkas_FusionState 0 "Normal" 1 "Fusion Disabled" 2 "SCC Communication Error" 3 "Reserved" ;
VAL_ 832 CF_Lkas_FcwOpt_USM 0 "None FCW Option" 1 "System Disable" 2 "System Enable (Early)" 3 "System Enable (Normal)" 4 "System Enable (Late)" 7 "Invalid" ;
VAL_ 832 CF_Lkas_LdwsOpt_USM 0 "Invalid" 1 "LDW Mode" 2 "LKA Mode (Pre-Departure)" 3 "LKA Mode (Post-Departure)" 4 "LDWS Only (None LKAS)" ;
VAL_ 1342 CF_Lkas_TsrSlifOpt 0 "None SLIF Option (default)" 1 "System Disable by USM" 2 "System Enable by USM" ;
VAL_ 1342 CF_LkasTsrStatus 0 "TSR Information Valid (default)" 1 "TSR Information Invalid/Failure" 2 "TSR Information Temporary Unavailable" ;
VAL_ 1342 CF_Lkas_TsrSpeed_Display_Clu 0 "No Recognition (default)" 253 "End of Speed limit" 254 "Out of Speed limit" 255 "Invalid" ;
VAL_ 1342 CF_LkasTsrSpeed_Display_Navi 0 "No Recognition (default)" 253 "End of Speed Limit" 254 "Out Of Speed Limit" 255 "Invalid" ;
VAL_ 1342 CF_Lkas_TsrAddinfo_Display 0 "No Display (Default)" 1 "No Passing Zone Display" ;
VAL_ 593 CF_Mdps_Def 0 "MDPS is not defective" 1 "MDPS is defective" ;
VAL_ 593 CF_Mdps_ToiUnavail 0 "Available" 1 "Unavailable" ;
VAL_ 593 CF_Mdps_ToiActive 0 "Deactivated" 1 "Activated" ;
VAL_ 593 CF_Mdps_ToiFlt 0 "No fault" 1 "Faulty" ;
VAL_ 593 CF_Mdps_FailStat 0 "Not in fail state" 1 "In fail state" ;
VAL_ 593 CF_Mdps_SErr 0 "VSM1 signal is not error" 1 "VSM1 signal is error" ;
VAL_ 1056 MainMode_ACC 0 "OFF" 1 "ON" ;
VAL_ 1056 SCCInfoDisplay 0 "-" 1 "Display ¡°SCC Mode¡±" 2 "Display ¡°Conventional Cruise Mode¡±" 3 "Display ¡°Object disappeared at low speed¡±" 4 "Display ¡°Available to resume acceleration control¡±" ;
VAL_ 1056 ObjValid 0 "No in-path object detected" 1 "In-path object detected" ;
VAL_ 1056 DriverAlertDisplay 0 "-" 1 "Display ¡°SCC Disengaged¡°" 2 "Display ¡°No SCC Engage Condition!¡°" 3 "Display ¡°SCC Disengaged When The Vehicle Stops'" ;
VAL_ 1056 TauGapSet 0 "No time gap set" 1 "1st level distance" 2 "2nd level distance" 3 "3rd level distance" 4 "4th level distance" ;
VAL_ 1056 ACC_ObjStatus 0 "No SCC object detected" 1 "SCC Object detected" 2 "Reserved" 3 "SCC Pre-Safe I/F inactive (No VI platform detected)" ;
VAL_ 1056 Navi_SCC_Curve_Status 0 "Not Applied" 1 "Function Off" 2 "Function On" 3 "Invalid(Fail)" ;
VAL_ 1056 Navi_SCC_Curve_Act 0 "Off" 1 "Ready" 2 "Act" 3 "Reserved" ;
VAL_ 1056 Navi_SCC_Camera_Act 0 "Off" 1 "Ready" 2 "Act" 3 "Reserved" ;
VAL_ 1056 Navi_SCC_Camera_Status 0 "Not Applied" 1 "Function Off" 2 "Function On" 3 "Invalid(Fail)" ;
VAL_ 1057 CF_VSM_Prefill 0 "No pre-fill" 1 "Pre-fill" ;
VAL_ 1057 CF_VSM_DecCmdAct 0 "No request" 1 "Request valid" ;
VAL_ 1057 CF_VSM_HBACmd 0 "Standard threshold" 1 "Lowered threshold 1" 2 "Lowered threshold 2" 3 "Lowered threshold 3" ;
VAL_ 1057 CF_VSM_Warn 0 "No warning" 1 "Warning level 1" 2 "Warning level 2" 3 "Warning level 3" ;
VAL_ 1057 CF_VSM_Stat 0 "Not applicable" 1 "Available" 2 "Temporarily not available" 3 "Permanently not available" ;
VAL_ 1057 CF_VSM_BeltCmd 0 "Release / No alert" 1 "Pre-crash full retraction" 2 "Haptic warning" ;
VAL_ 1057 ACCFailInfo 0 "System without error" 1 "Performance degredation" 2 "System temporairy unavailable" 3 "SCC Service Required" ;
VAL_ 1057 ACCMode 0 "Off" 1 "Engaged" 2 "Override" 3 "Shutoff" ;
VAL_ 1057 StopReq 0 "No request" 1 "Stop control is required" ;
VAL_ 1057 TakeOverReq 0 "No takeover request" 1 "Takeover request" ;
VAL_ 1057 PreFill 0 "No pre-filling of the brake system is required" 1 "Pre-filling of the brake system is required" ;
VAL_ 1057 CF_VSM_ConfMode 0 "Reserved" 1 "CDM Off" 2 "CDM On" 3 "Reserved" ;
VAL_ 1057 AEB_Failinfo 0 "Normal" 1 "Temp. Unavailable by Camera" 2 "Temp. Unavailable by Radar" 3 "Service Required" ;
VAL_ 1057 AEB_Status 0 "Not Applied" 1 "System Off" 2 "System On" 3 "Invaild (Fail)" ;
VAL_ 1057 AEB_CmdAct 0 "No request" 1 "Request valid" ;
VAL_ 1057 AEB_StopReq 0 "No request" 1 "Stop control is required" ;
VAL_ 1057 CR_VSM_Alive 15 "Signal Invalid" ;
VAL_ 1290 SCCDrvModeRValue 0 "Default" 1 "Comford Mode" 2 "Normal Mode" 3 "Dynamic Mode" 4 "Reserved" 5 "Reserved" 6 "Reserved" 7 "Invalid" ;
VAL_ 1290 SCC_Equip 0 "Not Applied" 1 "Applied" ;
VAL_ 1290 AebDrvSetStatus 0 "OFF" 1 "ON (Early)" 2 "ON (Normal)" 3 "ON (Late)" 4 "Reserved" 5 "Reserved" 6 "Not Applied" 7 "Invalid" ;
VAL_ 1362 CF_SNV_DisplayControl 0 "Display Off" 1 "Display Black" 2 "Display On" 3 "Reserved" ;
VAL_ 1362 CF_Snv_BeepWarning 0 "None" 1 "Beep Warning" 2 "Reserved" 3 "Reserved" ;
VAL_ 1362 CF_Snv_WarningMessage 0 "No Warning" 1 "System Failure" 2 "System ON & luminous intensity High (day)" 3 "System ON & luminous intensity Low & H/Lamp Off" 4 "System ON & luminous intensity Low & H/Lamp On & IR LAMP Left Fail" 5 "System ON & luminous intensity Low & H/Lamp On IR LAMP Right Fail" 6 "System ON luminous intensity Low H/Lamp On IR LAMP All Fail" 7 "Reserved" ;
VAL_ 1362 CF_Snv_DetectionEnable 0 "Detection Mode Disable" 1 "Detection Mode Enable" ;
VAL_ 1362 CF_Snv_PedestrianDetect 0 "None" 1 "Detected" 2 "Reserved" 3 "Reserved" ;
VAL_ 1362 CF_Snv_IRLampControl 0 "IR-Lamp Off" 1 "IR-Lamp On" 2 "Reserved" 3 "Reserved" ;
VAL_ 273 TQI_TCU_INC 0 "No request" 255 "Max. Increase" ;
VAL_ 273 G_SEL_DISP 0 "P" 1 "L" 2 "2" 3 "3" 4 "DS Mode" 5 "D" 6 "N" 7 "R" 8 "sports mode / manual shift / paddle shift" 9 "Not Display at Cluster" 10 "Sub-Rom Communication" 11 "Sub-Rom Communication Error" 12 "Paddle shift (D-position)" 13 "Reserved" 14 "Intermediate Position" 15 "fault" ;
VAL_ 273 F_TCU 0 "no failure" 1 "diagnostic failure in TCU" 2 "diagnostic failure in TCU, limp home activated" 3 "not used" ;
VAL_ 273 TCU_TYPE 0 "Reserved" 1 "Step A/T" 2 "CVT" 3 "DCT" ;
VAL_ 273 TCU_OBD 2 "Failure information of TCU" 3 "Failure information of TCU" 4 "MIL on request" 5 "MIL on request" 6 "Failure information of TCU & MIL on request" 7 "Failure information of TCU & MIL on request" ;
VAL_ 273 SWI_GS 0 "no gear change" 1 "gear change is active" ;
VAL_ 273 GEAR_TYPE 3 "3 - Speed A/T or DCT" 4 "4 - Speed A/T or DCT" 5 "5 - Speed A/T or DCT" 6 "6 - Speed A/T or DCT" ;
VAL_ 273 TQI_TCU 0 "Max. reduction" 255 "No reduction" ;
VAL_ 273 SWI_CC 0 "No lock up control" 1 "Slip lock up" 2 "Fully lock up" 3 "Off slip lock up" ;
VAL_ 274 ETL_TCU 0 "Max. reduction" 255 "No reduction" ;
VAL_ 274 CUR_GR 0 "if N or P are detected (no frictional connection)" 1 "1st speed" 2 "2nd speed" 3 "3rd speed" 4 "4th speed" 5 "5th speed" 6 "6th speed" 7 "7th speed" 8 "8th speed" 14 "Reverse speed" ;
VAL_ 274 FUEL_CUT_TCU 0 "No request" 1 "Fuel cut request from TCU" ;
VAL_ 274 INH_FUEL_CUT 0 "No request" 1 "Fuel cut inhibition request from TCU" ;
VAL_ 274 IDLE_UP_TCU 0 "No IDLE UP request" 1 "IDLE UP request" ;
VAL_ 274 N_INC_TCU 0 "No request" 1 "Engine speed increase is requested" ;
VAL_ 275 CF_Tcu_InhCda 0 "CDA transition is available" 1 "TCU prohibits CDA transition" ;
VAL_ 275 CF_Tcu_IsgInhib 0 "TCU inhibits the ISG function" 1 "ISG is available" ;
VAL_ 275 CF_Tcu_BkeOnReq 0 "No request" 1 "Brake On Request" ;
VAL_ 275 CF_Tcu_NCStat 0 "No NC" 1 "NC Entry" 2 "NC Applied" 3 "NC Exit" ;
VAL_ 275 CF_Tcu_TarGr 0 "if N or P are detected (no frictional connection)" 1 "1st speed" 2 "2nd speed" 3 "3rd speed" 4 "4th speed" 5 "5th speed" 6 "6th speed" 7 "7th speed" 8 "8th speed" 14 "Reverse speed" ;
VAL_ 275 CF_Tcu_ShfPatt 0 "Normal (ECO)" 1 "Uphill 1 (Optional)" 2 "Uphill 2 (Optional)" 3 "Reserved" 4 "Downhill 1 (Optional)" 5 "Cruise (Optional)" 6 "Cruise_Uphill 1 (Optional)" 7 "Cruise_Uphill 2 (Optional)" 8 "Active ECO (Optional)" 9 "Sport Drive (Optional)" 15 "None of the above" ;
VAL_ 275 CF_Tcu_InhVis 0 "There¡¯s no request from TCU" 1 "TCU inhibits ECU from changing VGIS status" ;
VAL_ 275 CF_Tcu_PRelReq 0 "No Request" 1 "E-shifter Parking Release" ;
VAL_ 275 CF_Tcu_ITPhase 0 "In-Gear" 1 "Inertia Phase(Real Shifting)" ;
VAL_ 275 CF_Tcu_ActEcoRdy 0 "Not Ready" 1 "Ready" ;
VAL_ 275 CF_Tcu_TqGrdLim 255 "No torque gradient limitation" ;
VAL_ 275 CF_Tcu_SptRdy 0 "Not Ready" 1 "Ready" ;
VAL_ 275 CF_Tcu_SbwPInfo 0 "P" 1 "non P" ;
VAL_ 1282 CF_TCU_WarnMsg 0 "No Warning message" 1 "Warning message 1" 2 "Warning message 2" 3 "Warning message 3" 4 "Warning message 4" ;
VAL_ 1282 CF_TCU_WarnImg 0 "No Warning Image" 1 "Warning Image" ;
VAL_ 1282 CF_TCU_WarnSnd 0 "No Warning Sound" 1 "Warning Sound" ;
VAL_ 1282 CF_Tcu_GSel_BlinkReq 0 "No blink" 1 "Request lamp blinking" ;
VAL_ 1282 CF_Tcu_StRelStat 0 "Start release ready" 1 "Start release NOT ready" ;
VAL_ 1282 CF_Tcu_DriWarn2 0 "Normal Display" 1 "Clutch Off(Warning Message 1)" 2 "None-EOL" 3 "Pre-Clutch Off(Warning Message 2)" ;
VAL_ 1356 HILL_HOLD_WARNING 0 "Normal" 1 "HILL HOLD Warning" ;
